VERSION ""

NS_ :

BS_:

BU_:

BO_ 2566697982 FPOC: 64 Vector__XXX
 SG_ FusedOutput10Current : 144|16@1+ (0.005,0) [0|321.275] "A" Vector__XXX
 SG_ FusedOutput11Current : 160|16@1+ (0.005,0) [0|321.275] "A" Vector__XXX
 SG_ FusedOutput12Current : 176|16@1+ (0.005,0) [0|321.275] "A" Vector__XXX
 SG_ FusedOutput13Current : 192|16@1+ (0.005,0) [0|321.275] "A" Vector__XXX
 SG_ FusedOutput14Current : 208|16@1+ (0.005,0) [0|321.275] "A" Vector__XXX
 SG_ FusedOutput15Current : 224|16@1+ (0.005,0) [0|321.275] "A" Vector__XXX
 SG_ FusedOutput16Current : 240|16@1+ (0.005,0) [0|321.275] "A" Vector__XXX
 SG_ FusedOutput17Current : 256|16@1+ (0.005,0) [0|321.275] "A" Vector__XXX
 SG_ FusedOutput18Current : 272|16@1+ (0.005,0) [0|321.275] "A" Vector__XXX
 SG_ FusedOutput19Current : 288|16@1+ (0.005,0) [0|321.275] "A" Vector__XXX
 SG_ FusedOutput1Current : 0|16@1+ (0.005,0) [0|321.275] "A" Vector__XXX
 SG_ FusedOutput20Current : 304|16@1+ (0.005,0) [0|321.275] "A" Vector__XXX
 SG_ FusedOutput21Current : 320|16@1+ (0.005,0) [0|321.275] "A" Vector__XXX
 SG_ FusedOutput22Current : 336|16@1+ (0.005,0) [0|321.275] "A" Vector__XXX
 SG_ FusedOutput23Current : 352|16@1+ (0.005,0) [0|321.275] "A" Vector__XXX
 SG_ FusedOutput24Current : 368|16@1+ (0.005,0) [0|321.275] "A" Vector__XXX
 SG_ FusedOutput25Current : 384|16@1+ (0.005,0) [0|321.275] "A" Vector__XXX
 SG_ FusedOutput26Current : 400|16@1+ (0.005,0) [0|321.275] "A" Vector__XXX
 SG_ FusedOutput27Current : 416|16@1+ (0.005,0) [0|321.275] "A" Vector__XXX
 SG_ FusedOutput28Current : 432|16@1+ (0.005,0) [0|321.275] "A" Vector__XXX
 SG_ FusedOutput29Current : 448|16@1+ (0.005,0) [0|321.275] "A" Vector__XXX
 SG_ FusedOutput2Current : 16|16@1+ (0.005,0) [0|321.275] "A" Vector__XXX
 SG_ FusedOutput30Current : 464|16@1+ (0.005,0) [0|321.275] "A" Vector__XXX
 SG_ FusedOutput31Current : 480|16@1+ (0.005,0) [0|321.275] "A" Vector__XXX
 SG_ FusedOutput32Current : 496|16@1+ (0.005,0) [0|321.275] "A" Vector__XXX
 SG_ FusedOutput3Current : 32|16@1+ (0.005,0) [0|321.275] "A" Vector__XXX
 SG_ FusedOutput4Current : 48|16@1+ (0.005,0) [0|321.275] "A" Vector__XXX
 SG_ FusedOutput5Current : 64|16@1+ (0.005,0) [0|321.275] "A" Vector__XXX
 SG_ FusedOutput6Current : 80|16@1+ (0.005,0) [0|321.275] "A" Vector__XXX
 SG_ FusedOutput7Current : 96|16@1+ (0.005,0) [0|321.275] "A" Vector__XXX
 SG_ FusedOutput8Current : 112|16@1+ (0.005,0) [0|321.275] "A" Vector__XXX
 SG_ FusedOutput9Current : 128|16@1+ (0.005,0) [0|321.275] "A" Vector__XXX

BO_ 2566698238 SPOS: 8 Vector__XXX
 SG_ SwitchedOutput1 : 6|2@1+ (1,0) [0|3] "" Vector__XXX
 SG_ SwitchedOutput10 : 20|2@1+ (1,0) [0|3] "" Vector__XXX
 SG_ SwitchedOutput11 : 18|2@1+ (1,0) [0|3] "" Vector__XXX
 SG_ SwitchedOutput12 : 16|2@1+ (1,0) [0|3] "" Vector__XXX
 SG_ SwitchedOutput13 : 30|2@1+ (1,0) [0|3] "" Vector__XXX
 SG_ SwitchedOutput14 : 28|2@1+ (1,0) [0|3] "" Vector__XXX
 SG_ SwitchedOutput15 : 26|2@1+ (1,0) [0|3] "" Vector__XXX
 SG_ SwitchedOutput16 : 24|2@1+ (1,0) [0|3] "" Vector__XXX
 SG_ SwitchedOutput17 : 38|2@1+ (1,0) [0|3] "" Vector__XXX
 SG_ SwitchedOutput18 : 36|2@1+ (1,0) [0|3] "" Vector__XXX
 SG_ SwitchedOutput19 : 34|2@1+ (1,0) [0|3] "" Vector__XXX
 SG_ SwitchedOutput2 : 4|2@1+ (1,0) [0|3] "" Vector__XXX
 SG_ SwitchedOutput20 : 32|2@1+ (1,0) [0|3] "" Vector__XXX
 SG_ SwitchedOutput21 : 46|2@1+ (1,0) [0|3] "" Vector__XXX
 SG_ SwitchedOutput22 : 44|2@1+ (1,0) [0|3] "" Vector__XXX
 SG_ SwitchedOutput23 : 42|2@1+ (1,0) [0|3] "" Vector__XXX
 SG_ SwitchedOutput24 : 40|2@1+ (1,0) [0|3] "" Vector__XXX
 SG_ SwitchedOutput25 : 54|2@1+ (1,0) [0|3] "" Vector__XXX
 SG_ SwitchedOutput26 : 52|2@1+ (1,0) [0|3] "" Vector__XXX
 SG_ SwitchedOutput27 : 50|2@1+ (1,0) [0|3] "" Vector__XXX
 SG_ SwitchedOutput28 : 48|2@1+ (1,0) [0|3] "" Vector__XXX
 SG_ SwitchedOutput29 : 62|2@1+ (1,0) [0|3] "" Vector__XXX
 SG_ SwitchedOutput3 : 2|2@1+ (1,0) [0|3] "" Vector__XXX
 SG_ SwitchedOutput30 : 60|2@1+ (1,0) [0|3] "" Vector__XXX
 SG_ SwitchedOutput31 : 58|2@1+ (1,0) [0|3] "" Vector__XXX
 SG_ SwitchedOutput32 : 56|2@1+ (1,0) [0|3] "" Vector__XXX
 SG_ SwitchedOutput4 : 0|2@1+ (1,0) [0|3] "" Vector__XXX
 SG_ SwitchedOutput5 : 14|2@1+ (1,0) [0|3] "" Vector__XXX
 SG_ SwitchedOutput6 : 12|2@1+ (1,0) [0|3] "" Vector__XXX
 SG_ SwitchedOutput7 : 10|2@1+ (1,0) [0|3] "" Vector__XXX
 SG_ SwitchedOutput8 : 8|2@1+ (1,0) [0|3] "" Vector__XXX
 SG_ SwitchedOutput9 : 22|2@1+ (1,0) [0|3] "" Vector__XXX

BO_ 2566698494 FPOS: 8 Vector__XXX
 SG_ FusedOutput1 : 6|2@1+ (1,0) [0|3] "" Vector__XXX
 SG_ FusedOutput10 : 20|2@1+ (1,0) [0|3] "" Vector__XXX
 SG_ FusedOutput11 : 18|2@1+ (1,0) [0|3] "" Vector__XXX
 SG_ FusedOutput12 : 16|2@1+ (1,0) [0|3] "" Vector__XXX
 SG_ FusedOutput13 : 30|2@1+ (1,0) [0|3] "" Vector__XXX
 SG_ FusedOutput14 : 28|2@1+ (1,0) [0|3] "" Vector__XXX
 SG_ FusedOutput15 : 26|2@1+ (1,0) [0|3] "" Vector__XXX
 SG_ FusedOutput16 : 24|2@1+ (1,0) [0|3] "" Vector__XXX
 SG_ FusedOutput17 : 38|2@1+ (1,0) [0|3] "" Vector__XXX
 SG_ FusedOutput18 : 36|2@1+ (1,0) [0|3] "" Vector__XXX
 SG_ FusedOutput19 : 34|2@1+ (1,0) [0|3] "" Vector__XXX
 SG_ FusedOutput2 : 4|2@1+ (1,0) [0|3] "" Vector__XXX
 SG_ FusedOutput20 : 32|2@1+ (1,0) [0|3] "" Vector__XXX
 SG_ FusedOutput21 : 46|2@1+ (1,0) [0|3] "" Vector__XXX
 SG_ FusedOutput22 : 44|2@1+ (1,0) [0|3] "" Vector__XXX
 SG_ FusedOutput23 : 42|2@1+ (1,0) [0|3] "" Vector__XXX
 SG_ FusedOutput24 : 40|2@1+ (1,0) [0|3] "" Vector__XXX
 SG_ FusedOutput25 : 54|2@1+ (1,0) [0|3] "" Vector__XXX
 SG_ FusedOutput26 : 52|2@1+ (1,0) [0|3] "" Vector__XXX
 SG_ FusedOutput27 : 50|2@1+ (1,0) [0|3] "" Vector__XXX
 SG_ FusedOutput28 : 48|2@1+ (1,0) [0|3] "" Vector__XXX
 SG_ FusedOutput29 : 62|2@1+ (1,0) [0|3] "" Vector__XXX
 SG_ FusedOutput3 : 2|2@1+ (1,0) [0|3] "" Vector__XXX
 SG_ FusedOutput30 : 60|2@1+ (1,0) [0|3] "" Vector__XXX
 SG_ FusedOutput31 : 58|2@1+ (1,0) [0|3] "" Vector__XXX
 SG_ FusedOutput32 : 56|2@1+ (1,0) [0|3] "" Vector__XXX
 SG_ FusedOutput4 : 0|2@1+ (1,0) [0|3] "" Vector__XXX
 SG_ FusedOutput5 : 14|2@1+ (1,0) [0|3] "" Vector__XXX
 SG_ FusedOutput6 : 12|2@1+ (1,0) [0|3] "" Vector__XXX
 SG_ FusedOutput7 : 10|2@1+ (1,0) [0|3] "" Vector__XXX
 SG_ FusedOutput8 : 8|2@1+ (1,0) [0|3] "" Vector__XXX
 SG_ FusedOutput9 : 22|2@1+ (1,0) [0|3] "" Vector__XXX

BO_ 2566698750 VEP5: 8 Vector__XXX
 SG_ SLIBatteryPackCapacity : 16|16@1+ (1,0) [0|64255] "Ah" Vector__XXX
 SG_ SLIBatteryPackHealth : 32|8@1+ (0.5,0) [0|125] "%" Vector__XXX
 SG_ SLIBatteryPackStateofCharge : 0|16@1+ (0.0025,0) [0|160.6375] "%" Vector__XXX
 SG_ SLICrnkngPrdtdMnmmBttrVltg : 40|8@1+ (0.2,0) [0|50] "V" Vector__XXX

BO_ 2566699006 HSS2: 8 Vector__XXX
 SG_ HrdBttrPkRmnngChrg : 0|16@1+ (0.0025,0) [0|160.6375] "%" Vector__XXX
 SG_ HrdSstmEngnStpStrtRmnngPrntg : 16|8@1+ (0.4,0) [0|100] "%" Vector__XXX
 SG_ HrdPrplsnMdMxmmSpdSttng : 24|8@1+ (1,0) [0|250] "km/h" Vector__XXX
 SG_ HrdPrplsnMdRmnngDstn : 32|16@1+ (0.03125,0) [0|2007.96875] "km" Vector__XXX

BO_ 2566699262 AT2S2: 8 Vector__XXX
 SG_ Atttt2DsPttFtTtNxtAtvRt : 0|32@1+ (1,0) [0|4.21108E+09] "s" Vector__XXX
 SG_ Atttt2SCRSstTSLstSstCEvt : 32|32@1+ (1,0) [0|4.21108E+09] "s" Vector__XXX

BO_ 2566699518 AT1S2: 8 Vector__XXX
 SG_ Atttt1DsPttFtTtNxtAtvRt : 0|32@1+ (1,0) [0|4.21108E+09] "s" Vector__XXX
 SG_ Atttt1SCRSstTSLstSstCEvt : 32|32@1+ (1,0) [0|4.21108E+09] "s" Vector__XXX

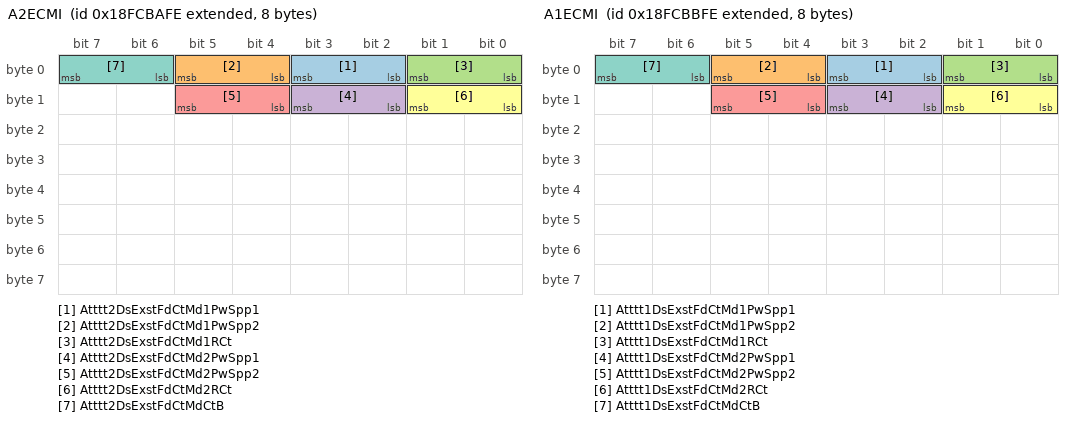
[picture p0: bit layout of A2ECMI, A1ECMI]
BO_ 2566699774 A2ECMI: 8 Vector__XXX
 SG_ Atttt2DsExstFdCtMd1PwSpp1 : 2|2@1+ (1,0) [0|3] "" Vector__XXX
 SG_ Atttt2DsExstFdCtMd1PwSpp2 : 4|2@1+ (1,0) [0|3] "" Vector__XXX
 SG_ Atttt2DsExstFdCtMd1RCt : 0|2@1+ (1,0) [0|3] "" Vector__XXX
 SG_ Atttt2DsExstFdCtMd2PwSpp1 : 10|2@1+ (1,0) [0|3] "" Vector__XXX
 SG_ Atttt2DsExstFdCtMd2PwSpp2 : 12|2@1+ (1,0) [0|3] "" Vector__XXX
 SG_ Atttt2DsExstFdCtMd2RCt : 8|2@1+ (1,0) [0|3] "" Vector__XXX
 SG_ Atttt2DsExstFdCtMdCtB : 6|2@1+ (1,0) [0|3] "" Vector__XXX

BO_ 2566700030 A1ECMI: 8 Vector__XXX
 SG_ Atttt1DsExstFdCtMd1PwSpp1 : 2|2@1+ (1,0) [0|3] "" Vector__XXX
 SG_ Atttt1DsExstFdCtMd1PwSpp2 : 4|2@1+ (1,0) [0|3] "" Vector__XXX
 SG_ Atttt1DsExstFdCtMd1RCt : 0|2@1+ (1,0) [0|3] "" Vector__XXX
 SG_ Atttt1DsExstFdCtMd2PwSpp1 : 10|2@1+ (1,0) [0|3] "" Vector__XXX
 SG_ Atttt1DsExstFdCtMd2PwSpp2 : 12|2@1+ (1,0) [0|3] "" Vector__XXX
 SG_ Atttt1DsExstFdCtMd2RCt : 8|2@1+ (1,0) [0|3] "" Vector__XXX
 SG_ Atttt1DsExstFdCtMdCtB : 6|2@1+ (1,0) [0|3] "" Vector__XXX

BO_ 2566700286 A2SCRSI2: 8 Vector__XXX
 SG_ Aftrtrtmnt2TtlDslExhstFldUsd : 0|32@1+ (0.5,0) [0|2105540607.5] "l" Vector__XXX

BO_ 2566700542 A1SCRSI2: 8 Vector__XXX
 SG_ Aftrtrtmnt1TtlDslExhstFldUsd : 0|32@1+ (0.5,0) [0|2105540607.5] "l" Vector__XXX
 SG_ AftrtrtmntTrpDslExhstFld : 32|32@1+ (0.05,0) [0|210554060.75] "l" Vector__XXX

BO_ 2566701566 TRF3: 8 Vector__XXX
 SG_ TransmissionClutch2Pressure : 0|8@1+ (16,0) [0|4000] "kPa" Vector__XXX
 SG_ TrnsmssnOlTrnsmssnClrOtltTmprtr : 8|8@1+ (1,-40) [-40|210] "degC" Vector__XXX

BO_ 2566701822 HSS1: 8 Vector__XXX
 SG_ ExtrnlEnrgSrCnntnStts : 48|4@1+ (1,0) [0|15] "" Vector__XXX
 SG_ HrdPrplsnMdTrnstnStts : 44|4@1+ (1,0) [0|15] "" Vector__XXX
 SG_ HrdSstmEltrAltrntrIndtr : 18|2@1+ (1,0) [0|3] "" Vector__XXX
 SG_ HrdSstmHghVltgExpsrIndtr : 24|2@1+ (1,0) [0|3] "" Vector__XXX
 SG_ HrdSstmIntlztnIndtr : 22|2@1+ (1,0) [0|3] "" Vector__XXX
 SG_ HrdSstmMtrOvrspdAdlAlrm : 16|2@1+ (1,0) [0|3] "" Vector__XXX
 SG_ HrdSstmMtrOvrspdIndtr : 14|2@1+ (1,0) [0|3] "" Vector__XXX
 SG_ HrdSstmPrplsnDslStts : 52|2@1+ (1,0) [0|3] "" Vector__XXX
 SG_ HrdSstmRgnrtvBrkngIndtr : 20|2@1+ (1,0) [0|3] "" Vector__XXX
 SG_ HybridPropulsionModeStatus : 40|4@1+ (1,0) [0|15] "" Vector__XXX
 SG_ HybridSystemEngineAssistStatus : 10|2@1+ (1,0) [0|3] "" Vector__XXX
 SG_ HybridSystemOBDRelatedDTCStatus : 6|2@1+ (1,0) [0|3] "" Vector__XXX
 SG_ HybridSystemOverheatIndicator : 2|2@1+ (1,0) [0|3] "" Vector__XXX
 SG_ HybridSystemServiceIndicator : 12|2@1+ (1,0) [0|3] "" Vector__XXX
 SG_ HybridSystemStopIndicator : 4|2@1+ (1,0) [0|3] "" Vector__XXX
 SG_ HybridSystemWarningIndicator : 0|2@1+ (1,0) [0|3] "" Vector__XXX
 SG_ PropulsionSystemActive : 8|2@1+ (1,0) [0|3] "" Vector__XXX
 SG_ StoredEnergySourceLevel : 32|8@1+ (0.4,0) [0|100] "%" Vector__XXX
 SG_ StrdEnrgSrInrsngMdAllwd : 28|2@1+ (1,0) [0|3] "" Vector__XXX
 SG_ StrdEnrgSrOnlMdAllwd : 26|2@1+ (1,0) [0|3] "" Vector__XXX

BO_ 2566702078 GFI4: 8 Vector__XXX
 SG_ SupplyGasMethanePercentage : 0|16@1+ (0.0025,0) [0|160.6375] "%" Vector__XXX

BO_ 2566702334 A2SCREGT2: 8 Vector__XXX
 SG_ Aftrtrtmnt2SCRIntrmdtTmprtr : 0|16@1+ (0.03125,-273) [-273|1734.96875] "degC" Vector__XXX
 SG_ Atttt2SCRItdtTptPFMI : 16|5@1+ (1,0) [0|31] "binary" Vector__XXX

BO_ 2566702590 A1SCREGT2: 8 Vector__XXX
 SG_ Aftrtrtmnt1SCRIntrmdtTmprtr : 0|16@1+ (0.03125,-273) [-273|1734.96875] "degC" Vector__XXX
 SG_ Atttt1SCRItdtTptPFMI : 16|5@1+ (1,0) [0|31] "binary" Vector__XXX

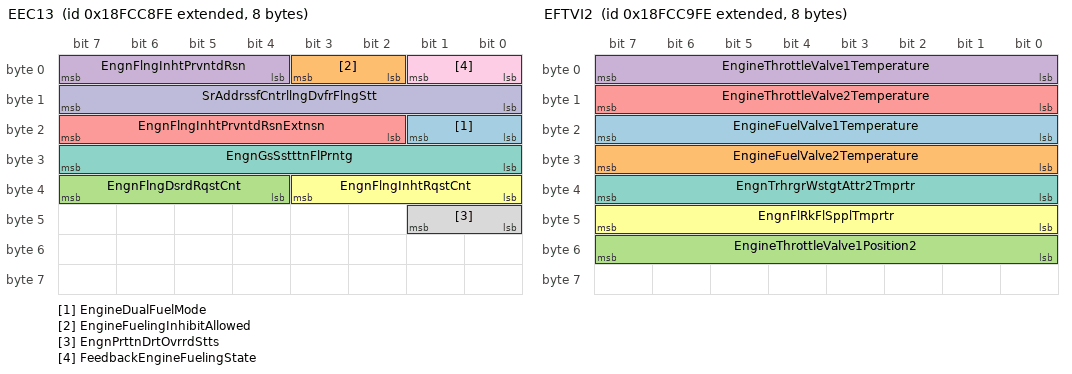
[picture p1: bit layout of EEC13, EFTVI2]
BO_ 2566703358 EEC13: 8 Vector__XXX
 SG_ EngineDualFuelMode : 16|2@1+ (1,0) [0|3] "" Vector__XXX
 SG_ EngineFuelingInhibitAllowed : 2|2@1+ (1,0) [0|3] "" Vector__XXX
 SG_ EngnFlngDsrdRqstCnt : 36|4@1+ (1,0) [0|15] "" Vector__XXX
 SG_ EngnFlngInhtPrvntdRsn : 4|4@1+ (1,0) [0|15] "" Vector__XXX
 SG_ EngnFlngInhtPrvntdRsnExtnsn : 18|6@1+ (1,0) [0|63] "" Vector__XXX
 SG_ EngnFlngInhtRqstCnt : 32|4@1+ (1,0) [0|15] "" Vector__XXX
 SG_ EngnGsSstttnFlPrntg : 24|8@1+ (0.5,0) [0|125] "%" Vector__XXX
 SG_ EngnPrttnDrtOvrrdStts : 40|2@1+ (1,0) [0|3] "" Vector__XXX
 SG_ FeedbackEngineFuelingState : 0|2@1+ (1,0) [0|3] "" Vector__XXX
 SG_ SrAddrssfCntrllngDvfrFlngStt : 8|8@1+ (1,0) [0|255] "SA" Vector__XXX

BO_ 2566703614 EFTVI2: 8 Vector__XXX
 SG_ EngineFuelValve1Temperature : 16|8@1+ (1,-40) [-40|210] "degC" Vector__XXX
 SG_ EngineFuelValve2Temperature : 24|8@1+ (1,-40) [-40|210] "degC" Vector__XXX
 SG_ EngineThrottleValve1Position2 : 48|8@1+ (0.4,0) [0|100] "%" Vector__XXX
 SG_ EngineThrottleValve1Temperature : 0|8@1+ (1,-40) [-40|210] "degC" Vector__XXX
 SG_ EngineThrottleValve2Temperature : 8|8@1+ (1,-40) [-40|210] "degC" Vector__XXX
 SG_ EngnFlRkFlSpplTmprtr : 40|8@1+ (1,-40) [-40|210] "degC" Vector__XXX
 SG_ EngnTrhrgrWstgtAttr2Tmprtr : 32|8@1+ (1,-40) [-40|210] "degC" Vector__XXX

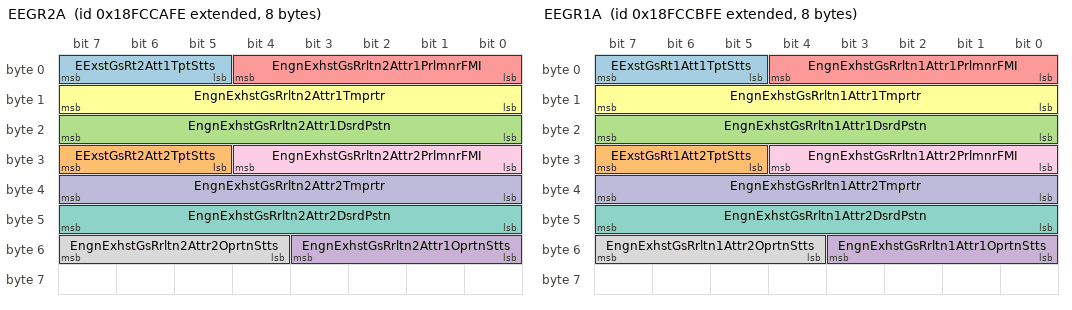
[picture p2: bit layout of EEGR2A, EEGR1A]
BO_ 2566703870 EEGR2A: 8 Vector__XXX
 SG_ EExstGsRt2Att1TptStts : 5|3@1+ (1,0) [0|7] "" Vector__XXX
 SG_ EExstGsRt2Att2TptStts : 29|3@1+ (1,0) [0|7] "" Vector__XXX
 SG_ EngnExhstGsRrltn2Attr1DsrdPstn : 16|8@1+ (0.4,0) [0|100] "%" Vector__XXX
 SG_ EngnExhstGsRrltn2Attr1OprtnStts : 48|4@1+ (1,0) [0|15] "" Vector__XXX
 SG_ EngnExhstGsRrltn2Attr1PrlmnrFMI : 0|5@1+ (1,0) [0|31] "binary" Vector__XXX
 SG_ EngnExhstGsRrltn2Attr1Tmprtr : 8|8@1+ (1,-40) [-40|210] "degC" Vector__XXX
 SG_ EngnExhstGsRrltn2Attr2DsrdPstn : 40|8@1+ (0.4,0) [0|100] "%" Vector__XXX
 SG_ EngnExhstGsRrltn2Attr2OprtnStts : 52|4@1+ (1,0) [0|15] "" Vector__XXX
 SG_ EngnExhstGsRrltn2Attr2PrlmnrFMI : 24|5@1+ (1,0) [0|31] "binary" Vector__XXX
 SG_ EngnExhstGsRrltn2Attr2Tmprtr : 32|8@1+ (1,-40) [-40|210] "degC" Vector__XXX

BO_ 2566704126 EEGR1A: 8 Vector__XXX
 SG_ EExstGsRt1Att1TptStts : 5|3@1+ (1,0) [0|7] "" Vector__XXX
 SG_ EExstGsRt1Att2TptStts : 29|3@1+ (1,0) [0|7] "" Vector__XXX
 SG_ EngnExhstGsRrltn1Attr1DsrdPstn : 16|8@1+ (0.4,0) [0|100] "%" Vector__XXX
 SG_ EngnExhstGsRrltn1Attr1OprtnStts : 48|4@1+ (1,0) [0|15] "" Vector__XXX
 SG_ EngnExhstGsRrltn1Attr1PrlmnrFMI : 0|5@1+ (1,0) [0|31] "binary" Vector__XXX
 SG_ EngnExhstGsRrltn1Attr1Tmprtr : 8|8@1+ (1,-40) [-40|210] "degC" Vector__XXX
 SG_ EngnExhstGsRrltn1Attr2DsrdPstn : 40|8@1+ (0.4,0) [0|100] "%" Vector__XXX
 SG_ EngnExhstGsRrltn1Attr2OprtnStts : 52|4@1+ (1,0) [0|15] "" Vector__XXX
 SG_ EngnExhstGsRrltn1Attr2PrlmnrFMI : 24|5@1+ (1,0) [0|31] "binary" Vector__XXX
 SG_ EngnExhstGsRrltn1Attr2Tmprtr : 32|8@1+ (1,-40) [-40|210] "degC" Vector__XXX

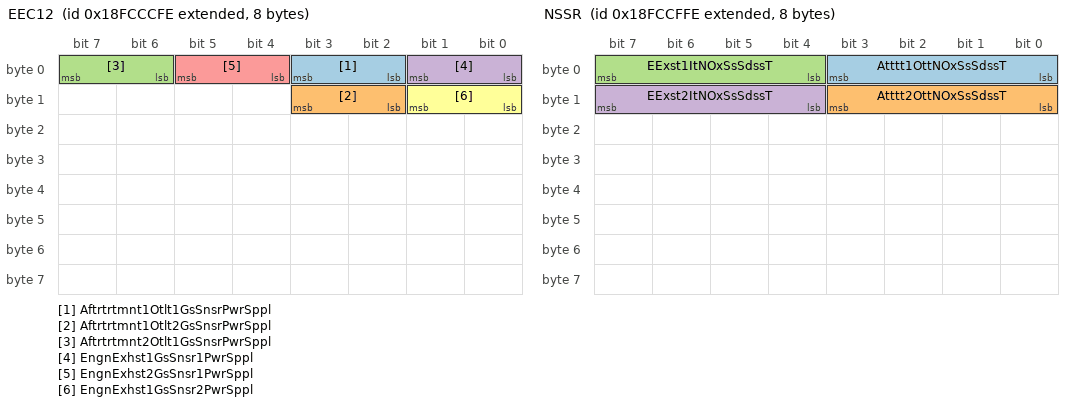
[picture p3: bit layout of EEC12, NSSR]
BO_ 2566704382 EEC12: 8 Vector__XXX
 SG_ Aftrtrtmnt1Otlt1GsSnsrPwrSppl : 2|2@1+ (1,0) [0|3] "" Vector__XXX
 SG_ Aftrtrtmnt1Otlt2GsSnsrPwrSppl : 10|2@1+ (1,0) [0|3] "" Vector__XXX
 SG_ Aftrtrtmnt2Otlt1GsSnsrPwrSppl : 6|2@1+ (1,0) [0|3] "" Vector__XXX
 SG_ EngnExhst1GsSnsr1PwrSppl : 0|2@1+ (1,0) [0|3] "" Vector__XXX
 SG_ EngnExhst2GsSnsr1PwrSppl : 4|2@1+ (1,0) [0|3] "" Vector__XXX
 SG_ EngnExhst1GsSnsr2PwrSppl : 8|2@1+ (1,0) [0|3] "" Vector__XXX

BO_ 2566705150 NSSR: 8 Vector__XXX
 SG_ Atttt1OttNOxSsSdssT : 0|4@1+ (1,0) [0|15] "" Vector__XXX
 SG_ Atttt2OttNOxSsSdssT : 8|4@1+ (1,0) [0|15] "" Vector__XXX
 SG_ EExst1ItNOxSsSdssT : 4|4@1+ (1,0) [0|15] "" Vector__XXX
 SG_ EExst2ItNOxSsSdssT : 12|4@1+ (1,0) [0|15] "" Vector__XXX

BO_ 2566705406 EPSI: 8 Vector__XXX
 SG_ Aftrtrtmnt1PrtltSnsr : 0|16@1+ (0.0125,0) [0|803.1875] "mg/(m*m*m)" Vector__XXX
 SG_ Aftrtrtmnt1PrtltSnsrCrrnt : 32|16@1+ (0.00390625,0) [0|250.99609375] "micro A" Vector__XXX
 SG_ Aftrtrtmnt2PrtltSnsr : 16|16@1+ (0.0125,0) [0|803.1875] "mg/(m*m*m)" Vector__XXX

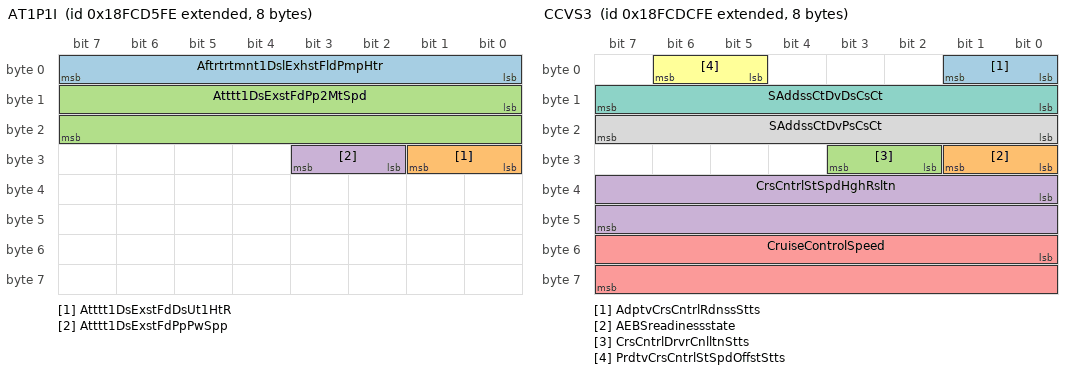
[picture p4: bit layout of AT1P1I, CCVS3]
BO_ 2566706686 AT1P1I: 8 Vector__XXX
 SG_ Aftrtrtmnt1DslExhstFldPmpHtr : 0|8@1+ (0.4,0) [0|100] "%" Vector__XXX
 SG_ Atttt1DsExstFdDsUt1HtR : 24|2@1+ (1,0) [0|3] "" Vector__XXX
 SG_ Atttt1DsExstFdPp2MtSpd : 8|16@1+ (0.5,0) [0|32127.5] "rpm" Vector__XXX
 SG_ Atttt1DsExstFdPpPwSpp : 26|2@1+ (1,0) [0|3] "" Vector__XXX

BO_ 2566706942 AT1DPF2S5: 8 Vector__XXX
 SG_ Atttt1DsPttFt2StSsAssFq3 : 0|16@1+ (0.1,0) [0|6425.5] "MHz" Vector__XXX
 SG_ Atttt1DsPttFt2StSsAssFq4 : 32|16@1+ (0.1,0) [0|6425.5] "MHz" Vector__XXX
 SG_ Atttt1DsPttFt2StSsFq3StS : 16|16@1+ (0.0025,0) [0|160.6375] "%" Vector__XXX
 SG_ Atttt1DsPttFt2StSsFq4StS : 48|16@1+ (0.0025,0) [0|160.6375] "%" Vector__XXX

BO_ 2566707198 AT1DPF2S4: 8 Vector__XXX
 SG_ Atttt1DsPttFt2StSsAssFq1 : 0|16@1+ (0.1,0) [0|6425.5] "MHz" Vector__XXX
 SG_ Atttt1DsPttFt2StSsAssFq2 : 32|16@1+ (0.1,0) [0|6425.5] "MHz" Vector__XXX
 SG_ Atttt1DsPttFt2StSsFq1StS : 16|16@1+ (0.0025,0) [0|160.6375] "%" Vector__XXX
 SG_ Atttt1DsPttFt2StSsFq2StS : 48|16@1+ (0.0025,0) [0|160.6375] "%" Vector__XXX

BO_ 2566707454 AT1DPF2S3: 8 Vector__XXX
 SG_ Atttt1DsPttFt2StSsAssRqstFq1 : 0|16@1+ (0.1,0) [0|6425.5] "MHz" Vector__XXX
 SG_ Atttt1DsPttFt2StSsAssRqstFq2 : 16|16@1+ (0.1,0) [0|6425.5] "MHz" Vector__XXX
 SG_ Atttt1DsPttFt2StSsAssRqstFq3 : 32|16@1+ (0.1,0) [0|6425.5] "MHz" Vector__XXX
 SG_ Atttt1DsPttFt2StSsAssRqstFq4 : 48|16@1+ (0.1,0) [0|6425.5] "MHz" Vector__XXX

BO_ 2566707710 AT1DPF1S5: 8 Vector__XXX
 SG_ Atttt1DsPttFt1StSsAssFq3 : 0|16@1+ (0.1,0) [0|6425.5] "MHz" Vector__XXX
 SG_ Atttt1DsPttFt1StSsAssFq4 : 32|16@1+ (0.1,0) [0|6425.5] "MHz" Vector__XXX
 SG_ Atttt1DsPttFt1StSsFq3StS : 16|16@1+ (0.0025,0) [0|160.6375] "%" Vector__XXX
 SG_ Atttt1DsPttFt1StSsFq4StS : 48|16@1+ (0.0025,0) [0|160.6375] "%" Vector__XXX

BO_ 2566707966 AT1DPF1S4: 8 Vector__XXX
 SG_ Atttt1DsPttFt1StSsAssFq1 : 0|16@1+ (0.1,0) [0|6425.5] "MHz" Vector__XXX
 SG_ Atttt1DsPttFt1StSsAssFq2 : 32|16@1+ (0.1,0) [0|6425.5] "MHz" Vector__XXX
 SG_ Atttt1DsPttFt1StSsFq1StS : 16|16@1+ (0.0025,0) [0|160.6375] "%" Vector__XXX
 SG_ Atttt1DsPttFt1StSsFq2StS : 48|16@1+ (0.0025,0) [0|160.6375] "%" Vector__XXX

BO_ 2566708222 AT1DPF1S3: 8 Vector__XXX
 SG_ Atttt1DsPttFt1StSsAssRqstFq1 : 0|16@1+ (0.1,0) [0|6425.5] "MHz" Vector__XXX
 SG_ Atttt1DsPttFt1StSsAssRqstFq2 : 16|16@1+ (0.1,0) [0|6425.5] "MHz" Vector__XXX
 SG_ Atttt1DsPttFt1StSsAssRqstFq3 : 32|16@1+ (0.1,0) [0|6425.5] "MHz" Vector__XXX
 SG_ Atttt1DsPttFt1StSsAssRqstFq4 : 48|16@1+ (0.1,0) [0|6425.5] "MHz" Vector__XXX

BO_ 2566708478 CCVS3: 8 Vector__XXX
 SG_ AdptvCrsCntrlRdnssStts : 0|2@1+ (1,0) [0|3] "" Vector__XXX
 SG_ AEBSreadinessstate : 24|2@1+ (1,0) [0|3] "" Vector__XXX
 SG_ CrsCntrlDrvrCnlltnStts : 26|2@1+ (1,0) [0|3] "" Vector__XXX
 SG_ CrsCntrlStSpdHghRsltn : 32|16@1+ (0.00390625,0) [0|250.996] "km/h" Vector__XXX
 SG_ CruiseControlSpeed : 48|16@1+ (0.00390625,0) [0|250.996] "km/h" Vector__XXX
 SG_ PrdtvCrsCntrlStSpdOffstStts : 5|2@1+ (1,0) [0|3] "" Vector__XXX
 SG_ SAddssCtDvDsCsCt : 8|8@1+ (1,0) [0|255] "SA" Vector__XXX
 SG_ SAddssCtDvPsCsCt : 16|8@1+ (1,0) [0|255] "SA" Vector__XXX

BO_ 2566708734 AT2AC3: 8 Vector__XXX
 SG_ Aftrtrtmnt2SndrArAsltPrssr : 0|16@1+ (0.1,0) [0|6425.5] "kPa" Vector__XXX

BO_ 2566708990 AT1AC3: 8 Vector__XXX
 SG_ Aftrtrtmnt1SndrArAsltPrssr : 0|16@1+ (0.1,0) [0|6425.5] "kPa" Vector__XXX
 SG_ OprtrIndmntOvrrdRnwlRqrd : 16|2@1+ (1,0) [0|3] "" Vector__XXX

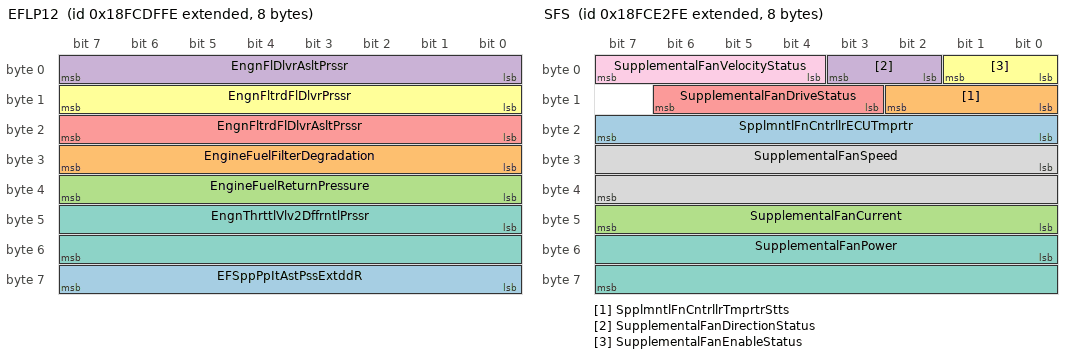
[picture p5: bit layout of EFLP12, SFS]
BO_ 2566709246 EFLP12: 8 Vector__XXX
 SG_ EFSppPpItAstPssExtddR : 56|8@1+ (5,0) [0|1250] "kPa" Vector__XXX
 SG_ EngineFuelFilterDegradation : 24|8@1+ (1,0) [0|250] "%" Vector__XXX
 SG_ EngineFuelReturnPressure : 32|8@1+ (1.64,-7) [-7|403] "kPa" Vector__XXX
 SG_ EngnFlDlvrAsltPrssr : 0|8@1+ (4,0) [0|1000] "kPa" Vector__XXX
 SG_ EngnFltrdFlDlvrAsltPrssr : 16|8@1+ (4,0) [0|1000] "kPa" Vector__XXX
 SG_ EngnFltrdFlDlvrPrssr : 8|8@1+ (4,0) [0|1000] "kPa" Vector__XXX
 SG_ EngnThrttlVlv2DffrntlPrssr : 40|16@1+ (0.1,0) [0|6425.5] "kPa" Vector__XXX

BO_ 2566709502 DPFC2: 8 Vector__XXX
 SG_ Aftertreatment1FuelMassRate : 32|16@1+ (0.05,0) [0|3212.75] "g/min" Vector__XXX
 SG_ Aftertreatment2FuelMassRate : 48|16@1+ (0.05,0) [0|3212.75] "g/min" Vector__XXX
 SG_ Atttt1DsPttFtItTptStPt : 0|16@1+ (0.03125,-273) [-273|1734.96875] "degC" Vector__XXX
 SG_ EngineUnburnedFuelPercentage : 16|16@1+ (0.0025,0) [0|160.6375] "%" Vector__XXX

BO_ 2566709758 LFE2: 8 Vector__XXX
 SG_ EngineDieselFuelDemandRate : 32|16@1+ (0.05,0) [0|3212.75] "l/h" Vector__XXX
 SG_ EngineFuelRateHighResolution : 0|32@1+ (0.001,0) [0|4211081.215] "l/h" Vector__XXX

BO_ 2566710014 SFS: 8 Vector__XXX
 SG_ SpplmntlFnCntrllrECUTmprtr : 16|8@1+ (1,-40) [-40|210] "degC" Vector__XXX
 SG_ SpplmntlFnCntrllrTmprtrStts : 8|3@1+ (1,0) [0|7] "" Vector__XXX
 SG_ SupplementalFanCurrent : 40|8@1+ (1,-125) [-125|125] "A" Vector__XXX
 SG_ SupplementalFanDirectionStatus : 2|2@1+ (1,0) [0|3] "" Vector__XXX
 SG_ SupplementalFanDriveStatus : 11|4@1+ (1,0) [0|15] "" Vector__XXX
 SG_ SupplementalFanEnableStatus : 0|2@1+ (1,0) [0|3] "" Vector__XXX
 SG_ SupplementalFanPower : 48|16@1+ (0.5,0) [0|32127.5] "W" Vector__XXX
 SG_ SupplementalFanSpeed : 24|16@1+ (0.5,0) [0|32127.5] "rpm" Vector__XXX
 SG_ SupplementalFanVelocityStatus : 4|4@1+ (1,0) [0|15] "" Vector__XXX

BO_ 2566710526 EFP: 8 Vector__XXX
 SG_ EngineFuelDensity : 16|16@1+ (0.00003052,0) [0|1.961] "g/cc" Vector__XXX
 SG_ EngineFuelDynamicViscosity : 0|16@1+ (0.015625,0) [0|1003.984375] "Cp" Vector__XXX
 SG_ EngnFl1Tmprtr1HghRsltn : 48|16@1+ (0.03125,-273) [-273|1734.96875] "degC" Vector__XXX
 SG_ EngnFlDltrtHghRsltn : 32|16@1+ (0.0001220703125,0) [0|7.844] "" Vector__XXX

BO_ 2566710782 HOP: 8 Vector__XXX
 SG_ HdrlOlRltvDltrtHghRsltn : 32|16@1+ (0.0001220703125,0) [0|7.844] "" Vector__XXX
 SG_ HdrlOlTmprtrHghRsltn : 48|16@1+ (0.03125,-273) [-273|1734.96875] "degC" Vector__XXX
 SG_ HydraulicOilDensity : 16|16@1+ (0.00003052,0) [0|1.961] "g/cc" Vector__XXX
 SG_ HydraulicOilDynamicViscosity : 0|16@1+ (0.015625,0) [0|1003.984375] "Cp" Vector__XXX

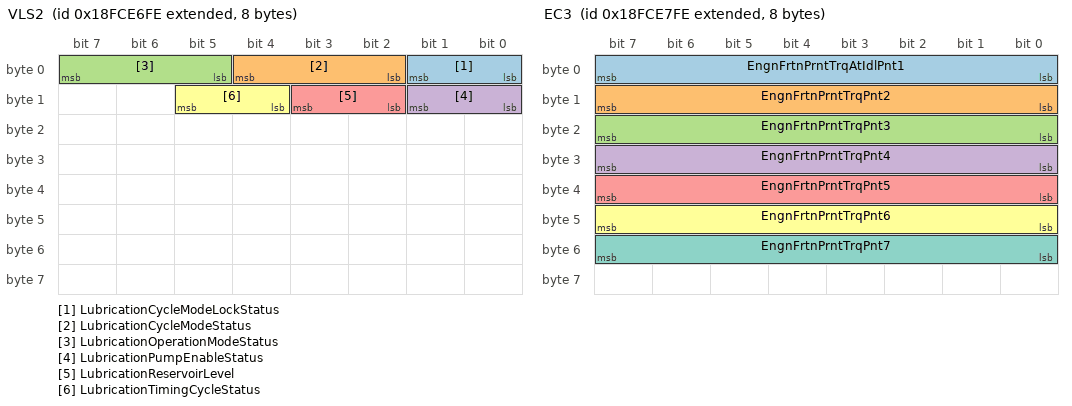
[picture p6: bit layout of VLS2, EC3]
BO_ 2566711038 VLS2: 8 Vector__XXX
 SG_ LubricationCycleModeLockStatus : 0|2@1+ (1,0) [0|3] "" Vector__XXX
 SG_ LubricationCycleModeStatus : 2|3@1+ (1,0) [0|7] "" Vector__XXX
 SG_ LubricationOperationModeStatus : 5|3@1+ (1,0) [0|7] "" Vector__XXX
 SG_ LubricationPumpEnableStatus : 8|2@1+ (1,0) [0|3] "" Vector__XXX
 SG_ LubricationReservoirLevel : 10|2@1+ (1,0) [0|3] "" Vector__XXX
 SG_ LubricationTimingCycleStatus : 12|2@1+ (1,0) [0|3] "" Vector__XXX

BO_ 2566711294 EC3: 8 Vector__XXX
 SG_ EngnFrtnPrntTrqAtIdlPnt1 : 0|8@1+ (1,-125) [-125|125] "%" Vector__XXX
 SG_ EngnFrtnPrntTrqPnt2 : 8|8@1+ (1,-125) [-125|125] "%" Vector__XXX
 SG_ EngnFrtnPrntTrqPnt3 : 16|8@1+ (1,-125) [-125|125] "%" Vector__XXX
 SG_ EngnFrtnPrntTrqPnt4 : 24|8@1+ (1,-125) [-125|125] "%" Vector__XXX
 SG_ EngnFrtnPrntTrqPnt5 : 32|8@1+ (1,-125) [-125|125] "%" Vector__XXX
 SG_ EngnFrtnPrntTrqPnt6 : 40|8@1+ (1,-125) [-125|125] "%" Vector__XXX
 SG_ EngnFrtnPrntTrqPnt7 : 48|8@1+ (1,-125) [-125|125] "%" Vector__XXX

BO_ 2566711550 IVAC: 8 Vector__XXX
 SG_ ItVvAttSstOPss1SdCt : 0|2@1+ (1,0) [0|3] "" Vector__XXX
 SG_ ItVvAttSstOPss2SdCt : 2|2@1+ (1,0) [0|3] "" Vector__XXX

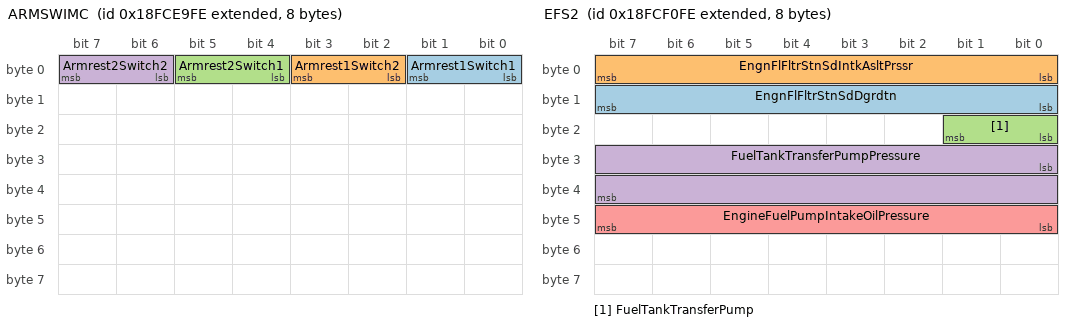
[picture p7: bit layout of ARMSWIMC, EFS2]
BO_ 2566711806 ARMSWIMC: 8 Vector__XXX
 SG_ Armrest1Switch1 : 0|2@1+ (1,0) [0|3] "" Vector__XXX
 SG_ Armrest1Switch2 : 2|2@1+ (1,0) [0|3] "" Vector__XXX
 SG_ Armrest2Switch1 : 4|2@1+ (1,0) [0|3] "" Vector__XXX
 SG_ Armrest2Switch2 : 6|2@1+ (1,0) [0|3] "" Vector__XXX

BO_ 2566712318 AFT2NAI: 8 Vector__XXX
 SG_ Aftrtrtmnt2NOxAdsrrDslftnStts : 2|2@1+ (1,0) [0|3] "" Vector__XXX
 SG_ Aftrtrtmnt2NOxAdsrrRgnrtnStts : 0|2@1+ (1,0) [0|3] "" Vector__XXX

BO_ 2566712574 AFT1NAI: 8 Vector__XXX
 SG_ Aftrtrtmnt1NOxAdsrrDslftnStts : 2|2@1+ (1,0) [0|3] "" Vector__XXX
 SG_ Aftrtrtmnt1NOxAdsrrRgnrtnStts : 0|2@1+ (1,0) [0|3] "" Vector__XXX

BO_ 2566712830 AT2WUDOC: 8 Vector__XXX
 SG_ Atttt2WUpDsOxdtCtstItTpt : 0|16@1+ (0.03125,-273) [-273|1734.96875] "degC" Vector__XXX
 SG_ Atttt2WUpDsOxdtCtstOttTpt : 16|16@1+ (0.03125,-273) [-273|1734.96875] "degC" Vector__XXX

BO_ 2566713598 EFS2: 8 Vector__XXX
 SG_ EngnFlFltrStnSdDgrdtn : 8|8@1+ (1,0) [0|250] "%" Vector__XXX
 SG_ EngnFlFltrStnSdIntkAsltPrssr : 0|8@1+ (2,0) [0|500] "kPa" Vector__XXX
 SG_ FuelTankTransferPump : 16|2@1+ (1,0) [0|3] "" Vector__XXX
 SG_ FuelTankTransferPumpPressure : 24|16@1+ (0.1,0) [0|6425.5] "kPa" Vector__XXX
 SG_ EngineFuelPumpIntakeOilPressure : 40|8@1+ (4,0) [0|1000] "kPa" Vector__XXX

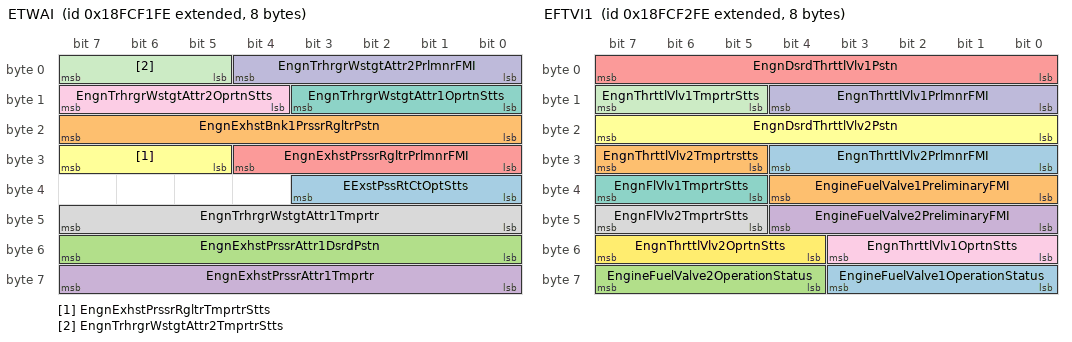
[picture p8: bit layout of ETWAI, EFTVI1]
BO_ 2566713854 ETWAI: 8 Vector__XXX
 SG_ EExstPssRtCtOptStts : 32|4@1+ (1,0) [0|15] "" Vector__XXX
 SG_ EngnExhstBnk1PrssrRgltrPstn : 16|8@1+ (0.4,0) [0|100] "%" Vector__XXX
 SG_ EngnExhstPrssrAttr1DsrdPstn : 48|8@1+ (0.4,0) [0|100] "%" Vector__XXX
 SG_ EngnExhstPrssrAttr1Tmprtr : 56|8@1+ (1,-40) [-40|210] "degC" Vector__XXX
 SG_ EngnExhstPrssrRgltrPrlmnrFMI : 24|5@1+ (1,0) [0|31] "binary" Vector__XXX
 SG_ EngnExhstPrssrRgltrTmprtrStts : 29|3@1+ (1,0) [0|7] "" Vector__XXX
 SG_ EngnTrhrgrWstgtAttr1OprtnStts : 8|4@1+ (1,0) [0|15] "" Vector__XXX
 SG_ EngnTrhrgrWstgtAttr1Tmprtr : 40|8@1+ (1,-40) [-40|210] "degC" Vector__XXX
 SG_ EngnTrhrgrWstgtAttr2OprtnStts : 12|4@1+ (1,0) [0|15] "" Vector__XXX
 SG_ EngnTrhrgrWstgtAttr2PrlmnrFMI : 0|5@1+ (1,0) [0|31] "binary" Vector__XXX
 SG_ EngnTrhrgrWstgtAttr2TmprtrStts : 5|3@1+ (1,0) [0|7] "" Vector__XXX

BO_ 2566714110 EFTVI1: 8 Vector__XXX
 SG_ EngineFuelValve1OperationStatus : 56|4@1+ (1,0) [0|15] "" Vector__XXX
 SG_ EngineFuelValve1PreliminaryFMI : 32|5@1+ (1,0) [0|31] "binary" Vector__XXX
 SG_ EngineFuelValve2OperationStatus : 60|4@1+ (1,0) [0|15] "" Vector__XXX
 SG_ EngineFuelValve2PreliminaryFMI : 40|5@1+ (1,0) [0|31] "binary" Vector__XXX
 SG_ EngnDsrdThrttlVlv1Pstn : 0|8@1+ (0.4,0) [0|100] "%" Vector__XXX
 SG_ EngnDsrdThrttlVlv2Pstn : 16|8@1+ (0.4,0) [0|100] "%" Vector__XXX
 SG_ EngnFlVlv1TmprtrStts : 37|3@1+ (1,0) [0|7] "" Vector__XXX
 SG_ EngnFlVlv2TmprtrStts : 45|3@1+ (1,0) [0|7] "" Vector__XXX
 SG_ EngnThrttlVlv1OprtnStts : 48|4@1+ (1,0) [0|15] "" Vector__XXX
 SG_ EngnThrttlVlv1PrlmnrFMI : 8|5@1+ (1,0) [0|31] "binary" Vector__XXX
 SG_ EngnThrttlVlv1TmprtrStts : 13|3@1+ (1,0) [0|7] "" Vector__XXX
 SG_ EngnThrttlVlv2OprtnStts : 52|4@1+ (1,0) [0|15] "" Vector__XXX
 SG_ EngnThrttlVlv2PrlmnrFMI : 24|5@1+ (1,0) [0|31] "binary" Vector__XXX
 SG_ EngnThrttlVlv2Tmprtrstts : 29|3@1+ (1,0) [0|7] "" Vector__XXX

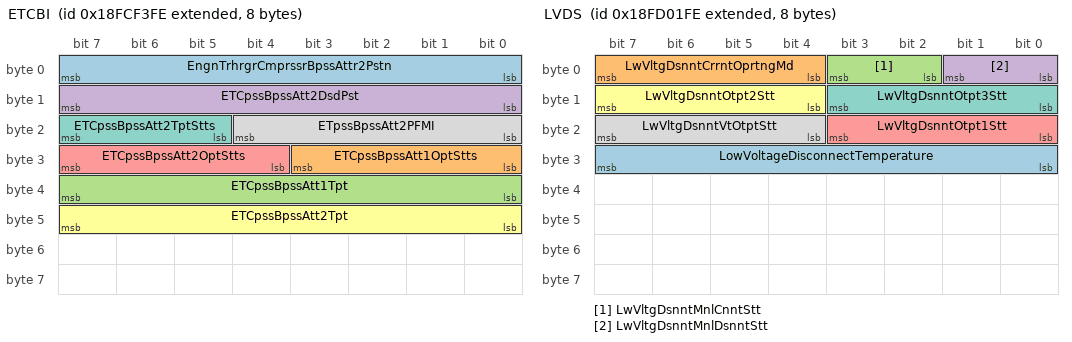
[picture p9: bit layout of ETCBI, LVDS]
BO_ 2566714366 ETCBI: 8 Vector__XXX
 SG_ EngnTrhrgrCmprssrBpssAttr2Pstn : 0|8@1+ (0.4,0) [0|100] "%" Vector__XXX
 SG_ ETCpssBpssAtt1OptStts : 24|4@1+ (1,0) [0|15] "" Vector__XXX
 SG_ ETCpssBpssAtt1Tpt : 32|8@1+ (1,-40) [-40|210] "degC" Vector__XXX
 SG_ ETCpssBpssAtt2DsdPst : 8|8@1+ (0.4,0) [0|100] "%" Vector__XXX
 SG_ ETCpssBpssAtt2OptStts : 28|4@1+ (1,0) [0|15] "" Vector__XXX
 SG_ ETCpssBpssAtt2Tpt : 40|8@1+ (1,-40) [-40|210] "degC" Vector__XXX
 SG_ ETCpssBpssAtt2TptStts : 21|3@1+ (1,0) [0|7] "" Vector__XXX
 SG_ ETpssBpssAtt2PFMI : 16|5@1+ (1,0) [0|31] "binary" Vector__XXX

BO_ 2566714622 CAC2: 8 Vector__XXX
 SG_ EngnChrgArClr2AmntArTmprtr : 32|16@1+ (0.03125,-273) [-273|1734.96875] "degC" Vector__XXX
 SG_ EngnChrgArClr2Effn : 48|8@1+ (0.4,0) [0|100] "%" Vector__XXX
 SG_ EngnChrgArClr2IntkTmprtr : 0|16@1+ (0.03125,-273) [-273|1734.96875] "degC" Vector__XXX
 SG_ EngnChrgArClr2OtltTmprtr : 16|16@1+ (0.03125,-273) [-273|1734.96875] "degC" Vector__XXX

BO_ 2566714878 CAC2P: 8 Vector__XXX
 SG_ EngnChrgArClr2PrlrEffn : 32|8@1+ (0.4,0) [0|100] "%" Vector__XXX
 SG_ EngnChrgArClr2PrlrIntkTmprtr : 0|16@1+ (0.03125,-273) [-273|1734.96875] "degC" Vector__XXX
 SG_ EngnChrgArClr2PrlrOtltTmprtr : 16|16@1+ (0.03125,-273) [-273|1734.96875] "degC" Vector__XXX

BO_ 2566715134 CAC1: 8 Vector__XXX
 SG_ EngnChrgArClr1AmntArTmprtr : 16|16@1+ (0.03125,-273) [-273|1734.96875] "degC" Vector__XXX
 SG_ EngnChrgArClr1Effn : 32|8@1+ (0.4,0) [0|100] "%" Vector__XXX
 SG_ EngnChrgArClr1IntkTmprtr : 0|16@1+ (0.03125,-273) [-273|1734.96875] "degC" Vector__XXX

BO_ 2566715390 CAC1P: 8 Vector__XXX
 SG_ EngnChrgArClr1PrlrEffn : 32|8@1+ (0.4,0) [0|100] "%" Vector__XXX
 SG_ EngnChrgArClr1PrlrIntkTmprtr : 0|16@1+ (0.03125,-273) [-273|1734.96875] "degC" Vector__XXX
 SG_ EngnChrgArClr1PrlrOtltTmprtr : 16|16@1+ (0.03125,-273) [-273|1734.96875] "degC" Vector__XXX

BO_ 2566715646 DPF2S2: 8 Vector__XXX
 SG_ Atttt2DsPttFtStSM : 32|16@1+ (0.0025,0) [0|160.6375] "%" Vector__XXX
 SG_ Atttt2DsPttFtStSMx : 16|16@1+ (0.0025,0) [0|160.6375] "%" Vector__XXX
 SG_ Atttt2DsPttFtStSStddDvt : 0|16@1+ (0.0025,0) [0|160.6375] "%" Vector__XXX

BO_ 2566715902 DPF1S2: 8 Vector__XXX
 SG_ Atttt1DsPttFtStSM : 32|16@1+ (0.0025,0) [0|160.6375] "%" Vector__XXX
 SG_ Atttt1DsPttFtStSMx : 16|16@1+ (0.0025,0) [0|160.6375] "%" Vector__XXX
 SG_ Atttt1DsPttFtStSStddDvt : 0|16@1+ (0.0025,0) [0|160.6375] "%" Vector__XXX

BO_ 2566717438 ET5: 8 Vector__XXX
 SG_ EngnExhstGsRrltn2MxrIntkTmprtr : 16|16@1+ (0.03125,-273) [-273|1734.96875] "degC" Vector__XXX
 SG_ EngnExhstGsRrltn2Tmprtr : 0|16@1+ (0.03125,-273) [-273|1734.96875] "degC" Vector__XXX

BO_ 2566717950 LVDS: 8 Vector__XXX
 SG_ LowVoltageDisconnectTemperature : 24|8@1+ (1,-40) [-40|210] "degC" Vector__XXX
 SG_ LwVltgDsnntCrrntOprtngMd : 4|4@1+ (1,0) [0|15] "" Vector__XXX
 SG_ LwVltgDsnntMnlCnntStt : 2|2@1+ (1,0) [0|3] "" Vector__XXX
 SG_ LwVltgDsnntMnlDsnntStt : 0|2@1+ (1,0) [0|3] "" Vector__XXX
 SG_ LwVltgDsnntOtpt1Stt : 16|4@1+ (1,0) [0|15] "" Vector__XXX
 SG_ LwVltgDsnntOtpt2Stt : 12|4@1+ (1,0) [0|15] "" Vector__XXX
 SG_ LwVltgDsnntOtpt3Stt : 8|4@1+ (1,0) [0|15] "" Vector__XXX
 SG_ LwVltgDsnntVtOtptStt : 20|4@1+ (1,0) [0|15] "" Vector__XXX

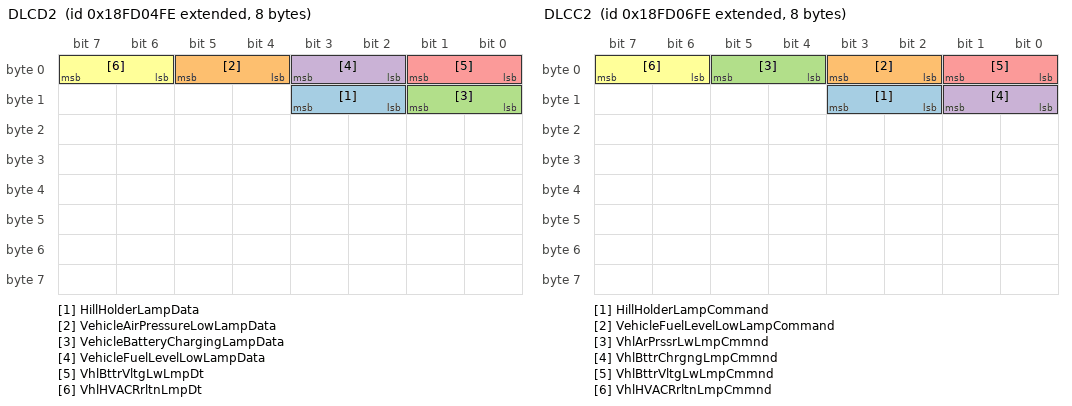
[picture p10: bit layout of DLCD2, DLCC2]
BO_ 2566718718 DLCD2: 8 Vector__XXX
 SG_ HillHolderLampData : 10|2@1+ (1,0) [0|3] "" Vector__XXX
 SG_ VehicleAirPressureLowLampData : 4|2@1+ (1,0) [0|3] "" Vector__XXX
 SG_ VehicleBatteryChargingLampData : 8|2@1+ (1,0) [0|3] "" Vector__XXX
 SG_ VehicleFuelLevelLowLampData : 2|2@1+ (1,0) [0|3] "" Vector__XXX
 SG_ VhlBttrVltgLwLmpDt : 0|2@1+ (1,0) [0|3] "" Vector__XXX
 SG_ VhlHVACRrltnLmpDt : 6|2@1+ (1,0) [0|3] "" Vector__XXX

BO_ 2566718974 DLCD1: 8 Vector__XXX
 SG_ CmprssnBrkEnlSwthIndtrLmpDt : 10|2@1+ (1,0) [0|3] "" Vector__XXX
 SG_ EngineAmberWarningLampData : 2|2@1+ (1,0) [0|3] "" Vector__XXX
 SG_ EngineBrakeActiveLampData : 8|2@1+ (1,0) [0|3] "" Vector__XXX
 SG_ EngineCoolantLevelLowLampData : 16|2@1+ (1,0) [0|3] "" Vector__XXX
 SG_ EngineOilPressureLowLampData : 12|2@1+ (1,0) [0|3] "" Vector__XXX
 SG_ EngineProtectLampData : 0|2@1+ (1,0) [0|3] "" Vector__XXX
 SG_ EngineRedStopLampData : 4|2@1+ (1,0) [0|3] "" Vector__XXX
 SG_ EngineSpeedHighLampData : 30|2@1+ (1,0) [0|3] "" Vector__XXX
 SG_ EngineSpeedVeryHighLampData : 32|2@1+ (1,0) [0|3] "" Vector__XXX
 SG_ EngineWaitToStartLampData : 62|2@1+ (1,0) [0|3] "" Vector__XXX
 SG_ EngnArFltrRstrtnLmpDt : 20|2@1+ (1,0) [0|3] "" Vector__XXX
 SG_ EngnClntTmprtrHghLmpDt : 14|2@1+ (1,0) [0|3] "" Vector__XXX
 SG_ EngnCntrlMdl1RdfrUsLmpDt : 24|2@1+ (1,0) [0|3] "" Vector__XXX
 SG_ EngnCntrlMdl2RdfrUsLmpDt : 26|2@1+ (1,0) [0|3] "" Vector__XXX
 SG_ EngnCntrlMdl3RdfrUsLmpDt : 28|2@1+ (1,0) [0|3] "" Vector__XXX
 SG_ EngnFlFltrRstrtdLmpDt : 22|2@1+ (1,0) [0|3] "" Vector__XXX
 SG_ EngnIdlMngmntAtvLmpDt : 18|2@1+ (1,0) [0|3] "" Vector__XXX
 SG_ OBDMalfunctionIndicatorLampData : 6|2@1+ (1,0) [0|3] "" Vector__XXX
 SG_ VhlAlrtnRtLmtLmpDt : 34|2@1+ (1,0) [0|3] "" Vector__XXX
 SG_ EngnStpStrtAtmtStpAtvLmpDt : 38|2@1+ (1,0) [0|3] "" Vector__XXX
 SG_ EngnStpStrtAtmtStrtFldLmpDt : 40|2@1+ (1,0) [0|3] "" Vector__XXX
 SG_ EngineStopStartEnabledLampData : 42|2@1+ (1,0) [0|3] "" Vector__XXX

BO_ 2566719230 DLCC2: 8 Vector__XXX
 SG_ HillHolderLampCommand : 10|2@1+ (1,0) [0|3] "" Vector__XXX
 SG_ VehicleFuelLevelLowLampCommand : 2|2@1+ (1,0) [0|3] "" Vector__XXX
 SG_ VhlArPrssrLwLmpCmmnd : 4|2@1+ (1,0) [0|3] "" Vector__XXX
 SG_ VhlBttrChrgngLmpCmmnd : 8|2@1+ (1,0) [0|3] "" Vector__XXX
 SG_ VhlBttrVltgLwLmpCmmnd : 0|2@1+ (1,0) [0|3] "" Vector__XXX
 SG_ VhlHVACRrltnLmpCmmnd : 6|2@1+ (1,0) [0|3] "" Vector__XXX

BO_ 2566719486 DLCC1: 8 Vector__XXX
 SG_ CmprssnBrkEnlSwthIndtrLmpCmmnd : 10|2@1+ (1,0) [0|3] "" Vector__XXX
 SG_ EngineAmberWarningLampCommand : 2|2@1+ (1,0) [0|3] "" Vector__XXX
 SG_ EngineBrakeActiveLampCommand : 8|2@1+ (1,0) [0|3] "" Vector__XXX
 SG_ EngineOilPressureLowLampCommand : 12|2@1+ (1,0) [0|3] "" Vector__XXX
 SG_ EngineProtectLampCommand : 0|2@1+ (1,0) [0|3] "" Vector__XXX
 SG_ EngineRedStopLampCommand : 4|2@1+ (1,0) [0|3] "" Vector__XXX
 SG_ EngineSpeedHighLampCommand : 30|2@1+ (1,0) [0|3] "" Vector__XXX
 SG_ EngineSpeedVeryHighLampCommand : 32|2@1+ (1,0) [0|3] "" Vector__XXX
 SG_ EngnArFltrRstrtnLmpCmmnd : 20|2@1+ (1,0) [0|3] "" Vector__XXX
 SG_ EngnClntLvlLwLmpCmmnd : 16|2@1+ (1,0) [0|3] "" Vector__XXX
 SG_ EngnClntTmprtrHghLmpCmmnd : 14|2@1+ (1,0) [0|3] "" Vector__XXX
 SG_ EngnCntrlMdl1RdfrUsLmpCmmnd : 24|2@1+ (1,0) [0|3] "" Vector__XXX
 SG_ EngnCntrlMdl2RdfrUsLmpCmmnd : 26|2@1+ (1,0) [0|3] "" Vector__XXX
 SG_ EngnCntrlMdl3RdfrUsLmpCmmnd : 28|2@1+ (1,0) [0|3] "" Vector__XXX
 SG_ EngnFlFltrRstrtdLmpCmmnd : 22|2@1+ (1,0) [0|3] "" Vector__XXX
 SG_ EngnIdlMngmntAtvLmpCmmnd : 18|2@1+ (1,0) [0|3] "" Vector__XXX
 SG_ EngnIdlMngmntPndngEvntLmpCmmnd : 36|2@1+ (1,0) [0|3] "" Vector__XXX
 SG_ OBDMlfntnIndtrLmpCmmnd : 6|2@1+ (1,0) [0|3] "" Vector__XXX
 SG_ VhlAlrtnRtLmtLmpCmmnd : 34|2@1+ (1,0) [0|3] "" Vector__XXX
 SG_ EngnStpStrtAtmtStpAtvLmpCmmnd : 38|2@1+ (1,0) [0|3] "" Vector__XXX
 SG_ EngnStpStrtAtmtStrtFldLmpCmmnd : 40|2@1+ (1,0) [0|3] "" Vector__XXX
 SG_ EngnStpStrtEnldLmpCmmnd : 42|2@1+ (1,0) [0|3] "" Vector__XXX

BO_ 2566719998 HRLFC: 8 Vector__XXX
 SG_ EngineTripFuelHighResolution : 0|32@1+ (0.001,0) [0|4211081.215] "l" Vector__XXX
 SG_ EngnTtlFlUsdHghRsltn : 32|32@1+ (0.001,0) [0|4211081.215] "l" Vector__XXX

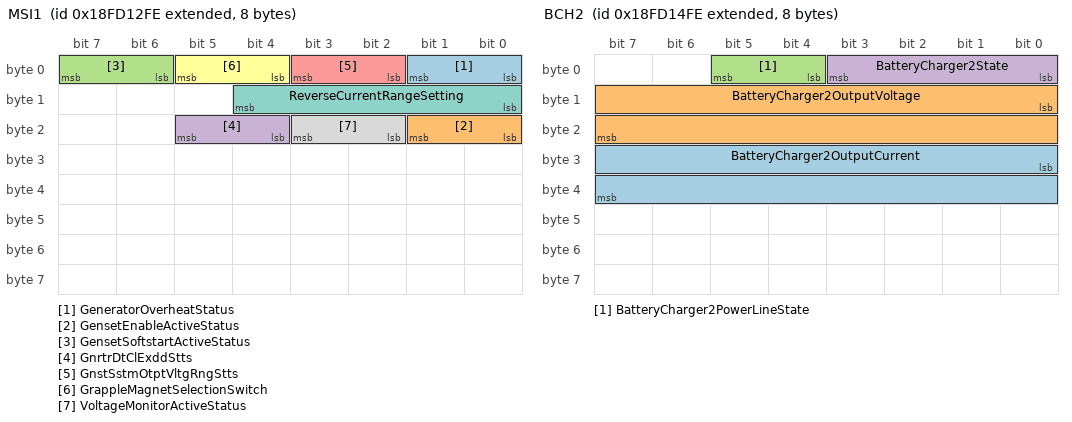
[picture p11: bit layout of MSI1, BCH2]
BO_ 2566722302 MSI1: 8 Vector__XXX
 SG_ GeneratorOverheatStatus : 0|2@1+ (1,0) [0|3] "" Vector__XXX
 SG_ GensetEnableActiveStatus : 16|2@1+ (1,0) [0|3] "" Vector__XXX
 SG_ GensetSoftstartActiveStatus : 6|2@1+ (1,0) [0|3] "" Vector__XXX
 SG_ GnrtrDtClExddStts : 20|2@1+ (1,0) [0|3] "" Vector__XXX
 SG_ GnstSstmOtptVltgRngStts : 2|2@1+ (1,0) [0|3] "" Vector__XXX
 SG_ GrappleMagnetSelectionSwitch : 4|2@1+ (1,0) [0|3] "" Vector__XXX
 SG_ ReverseCurrentRangeSetting : 8|5@1+ (1,0) [0|31] "" Vector__XXX
 SG_ VoltageMonitorActiveStatus : 18|2@1+ (1,0) [0|3] "" Vector__XXX

BO_ 2566722558 MSCI: 8 Vector__XXX
 SG_ MagnetBoostTime : 0|8@1+ (0.25,0) [0|62.5] "s" Vector__XXX
 SG_ MagnetRatedPower : 8|16@1+ (0.5,0) [0|32127.5] "kW" Vector__XXX

BO_ 2566722814 BCH2: 8 Vector__XXX
 SG_ BatteryCharger2OutputCurrent : 24|16@1+ (0.05,-1600) [-1600|1612.75] "A" Vector__XXX
 SG_ BatteryCharger2OutputVoltage : 8|16@1+ (0.05,0) [0|3212.75] "V" Vector__XXX
 SG_ BatteryCharger2PowerLineState : 4|2@1+ (1,0) [0|3] "" Vector__XXX
 SG_ BatteryCharger2State : 0|4@1+ (1,0) [0|15] "" Vector__XXX

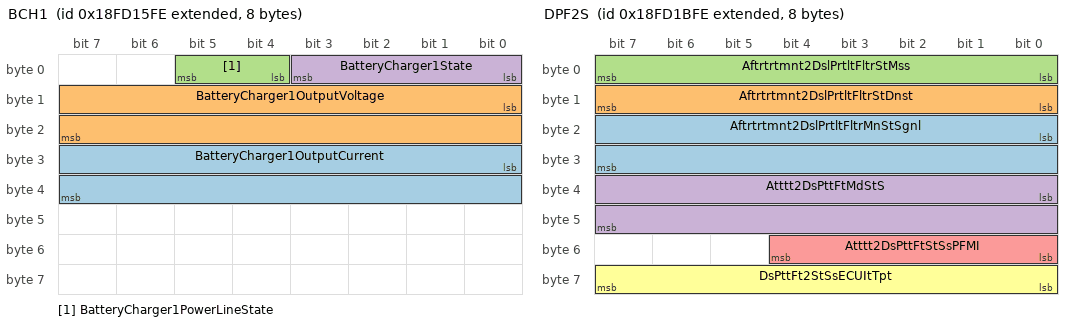
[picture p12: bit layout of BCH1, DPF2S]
BO_ 2566723070 BCH1: 8 Vector__XXX
 SG_ BatteryCharger1OutputCurrent : 24|16@1+ (0.05,-1600) [-1600|1612.75] "A" Vector__XXX
 SG_ BatteryCharger1OutputVoltage : 8|16@1+ (0.05,0) [0|3212.75] "V" Vector__XXX
 SG_ BatteryCharger1PowerLineState : 4|2@1+ (1,0) [0|3] "" Vector__XXX
 SG_ BatteryCharger1State : 0|4@1+ (1,0) [0|15] "" Vector__XXX

BO_ 2566724350 AT1WUDOC: 8 Vector__XXX
 SG_ Atttt1WUpDsOxdtCtstItTpt : 0|16@1+ (0.03125,-273) [-273|1734.96875] "degC" Vector__XXX
 SG_ Atttt1WUpDsOxdtCtstOttTpt : 16|16@1+ (0.03125,-273) [-273|1734.96875] "degC" Vector__XXX

BO_ 2566724606 DPF2S: 8 Vector__XXX
 SG_ Aftrtrtmnt2DslPrtltFltrMnStSgnl : 16|16@1+ (0.0025,0) [0|160.6375] "%" Vector__XXX
 SG_ Aftrtrtmnt2DslPrtltFltrStDnst : 8|8@1+ (0.08,0) [0|20] "g/L" Vector__XXX
 SG_ Aftrtrtmnt2DslPrtltFltrStMss : 0|8@1+ (4,0) [0|1000] "g" Vector__XXX
 SG_ Atttt2DsPttFtMdStS : 32|16@1+ (0.0025,0) [0|160.6375] "%" Vector__XXX
 SG_ Atttt2DsPttFtStSsPFMI : 48|5@1+ (1,0) [0|31] "binary" Vector__XXX
 SG_ DsPttFt2StSsECUItTpt : 56|8@1+ (1,-40) [-40|210] "degC" Vector__XXX

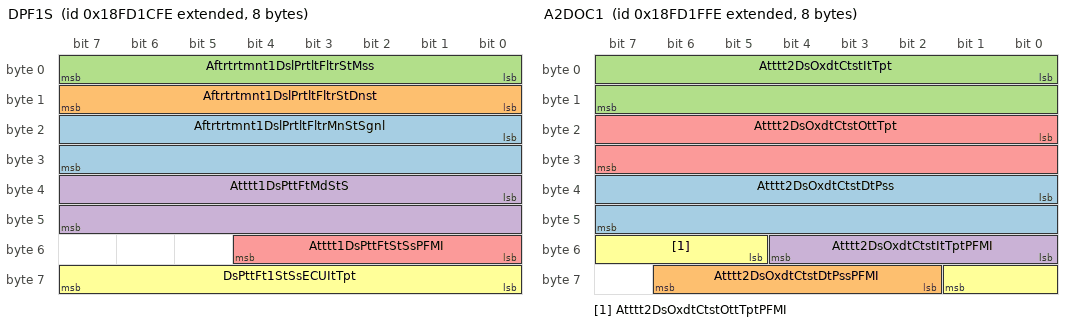
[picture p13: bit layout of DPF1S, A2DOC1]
BO_ 2566724862 DPF1S: 8 Vector__XXX
 SG_ Aftrtrtmnt1DslPrtltFltrMnStSgnl : 16|16@1+ (0.0025,0) [0|160.6375] "%" Vector__XXX
 SG_ Aftrtrtmnt1DslPrtltFltrStDnst : 8|8@1+ (0.08,0) [0|20] "g/L" Vector__XXX
 SG_ Aftrtrtmnt1DslPrtltFltrStMss : 0|8@1+ (4,0) [0|1000] "g" Vector__XXX
 SG_ Atttt1DsPttFtMdStS : 32|16@1+ (0.0025,0) [0|160.6375] "%" Vector__XXX
 SG_ Atttt1DsPttFtStSsPFMI : 48|5@1+ (1,0) [0|31] "binary" Vector__XXX
 SG_ DsPttFt1StSsECUItTpt : 56|8@1+ (1,-40) [-40|210] "degC" Vector__XXX

BO_ 2566725118 ATDT2: 8 Vector__XXX
 SG_ Atttt1TWCtstDtTpt : 0|16@1+ (0.03125,-273) [-273|1734.96875] "degC" Vector__XXX
 SG_ Atttt2TWCtstDtTpt : 16|16@1+ (0.03125,-273) [-273|1734.96875] "degC" Vector__XXX

BO_ 2566725374 ATDT1: 8 Vector__XXX
 SG_ Atttt1GsOxdtCtstDtTpt : 0|16@1+ (0.03125,-273) [-273|1734.96875] "degC" Vector__XXX
 SG_ Atttt2GsOxdtCtstDtTpt : 16|16@1+ (0.03125,-273) [-273|1734.96875] "degC" Vector__XXX

BO_ 2566725630 A2DOC1: 8 Vector__XXX
 SG_ Atttt2DsOxdtCtstDtPss : 32|16@1+ (0.5,0) [0|32127.5] "kPa" Vector__XXX
 SG_ Atttt2DsOxdtCtstDtPssPFMI : 58|5@1+ (1,0) [0|31] "binary" Vector__XXX
 SG_ Atttt2DsOxdtCtstItTpt : 0|16@1+ (0.03125,-273) [-273|1734.96875] "degC" Vector__XXX
 SG_ Atttt2DsOxdtCtstItTptPFMI : 48|5@1+ (1,0) [0|31] "binary" Vector__XXX
 SG_ Atttt2DsOxdtCtstOttTpt : 16|16@1+ (0.03125,-273) [-273|1734.96875] "degC" Vector__XXX
 SG_ Atttt2DsOxdtCtstOttTptPFMI : 53|5@1+ (1,0) [0|31] "binary" Vector__XXX

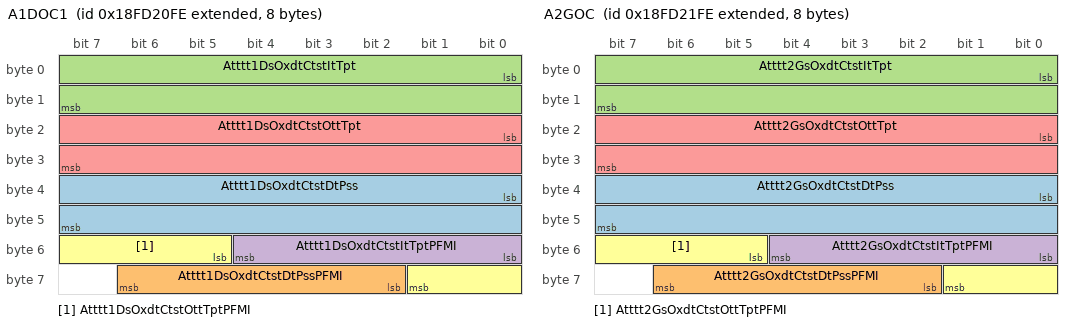
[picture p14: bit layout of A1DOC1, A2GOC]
BO_ 2566725886 A1DOC1: 8 Vector__XXX
 SG_ Atttt1DsOxdtCtstDtPss : 32|16@1+ (0.1,0) [0|6425.5] "kPa" Vector__XXX
 SG_ Atttt1DsOxdtCtstDtPssPFMI : 58|5@1+ (1,0) [0|31] "binary" Vector__XXX
 SG_ Atttt1DsOxdtCtstItTpt : 0|16@1+ (0.03125,-273) [-273|1734.96875] "degC" Vector__XXX
 SG_ Atttt1DsOxdtCtstItTptPFMI : 48|5@1+ (1,0) [0|31] "binary" Vector__XXX
 SG_ Atttt1DsOxdtCtstOttTpt : 16|16@1+ (0.03125,-273) [-273|1734.96875] "degC" Vector__XXX
 SG_ Atttt1DsOxdtCtstOttTptPFMI : 53|5@1+ (1,0) [0|31] "binary" Vector__XXX

BO_ 2566726142 A2GOC: 8 Vector__XXX
 SG_ Atttt2GsOxdtCtstDtPss : 32|16@1+ (0.1,0) [0|6425.5] "kPa" Vector__XXX
 SG_ Atttt2GsOxdtCtstDtPssPFMI : 58|5@1+ (1,0) [0|31] "binary" Vector__XXX
 SG_ Atttt2GsOxdtCtstItTpt : 0|16@1+ (0.03125,-273) [-273|1734.96875] "degC" Vector__XXX
 SG_ Atttt2GsOxdtCtstItTptPFMI : 48|5@1+ (1,0) [0|31] "binary" Vector__XXX
 SG_ Atttt2GsOxdtCtstOttTpt : 16|16@1+ (0.03125,-273) [-273|1734.96875] "degC" Vector__XXX
 SG_ Atttt2GsOxdtCtstOttTptPFMI : 53|5@1+ (1,0) [0|31] "binary" Vector__XXX

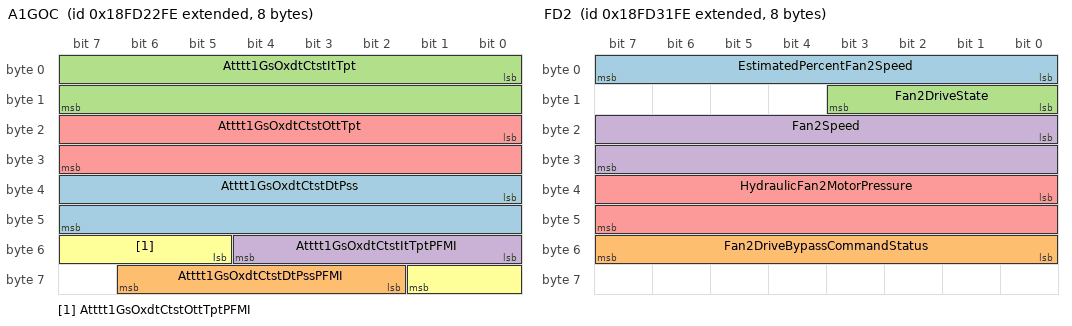
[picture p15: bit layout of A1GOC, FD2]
BO_ 2566726398 A1GOC: 8 Vector__XXX
 SG_ Atttt1GsOxdtCtstDtPss : 32|16@1+ (0.1,0) [0|6425.5] "kPa" Vector__XXX
 SG_ Atttt1GsOxdtCtstDtPssPFMI : 58|5@1+ (1,0) [0|31] "binary" Vector__XXX
 SG_ Atttt1GsOxdtCtstItTpt : 0|16@1+ (0.03125,-273) [-273|1734.96875] "degC" Vector__XXX
 SG_ Atttt1GsOxdtCtstItTptPFMI : 48|5@1+ (1,0) [0|31] "binary" Vector__XXX
 SG_ Atttt1GsOxdtCtstOttTpt : 16|16@1+ (0.03125,-273) [-273|1734.96875] "degC" Vector__XXX
 SG_ Atttt1GsOxdtCtstOttTptPFMI : 53|5@1+ (1,0) [0|31] "binary" Vector__XXX

BO_ 2566730238 FD2: 8 Vector__XXX
 SG_ EstimatedPercentFan2Speed : 0|8@1+ (0.4,0) [0|100] "%" Vector__XXX
 SG_ Fan2DriveBypassCommandStatus : 48|8@1+ (0.4,0) [0|100] "%" Vector__XXX
 SG_ Fan2DriveState : 8|4@1+ (1,0) [0|15] "" Vector__XXX
 SG_ Fan2Speed : 16|16@1+ (0.125,0) [0|8031.875] "rpm" Vector__XXX
 SG_ HydraulicFan2MotorPressure : 32|16@1+ (0.5,0) [0|32127.5] "kPa" Vector__XXX

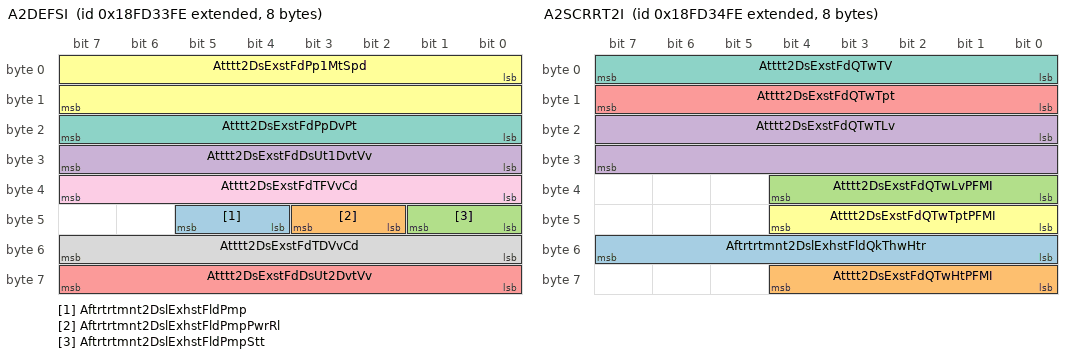
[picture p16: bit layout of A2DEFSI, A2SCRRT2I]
BO_ 2566730750 A2DEFSI: 8 Vector__XXX
 SG_ Aftrtrtmnt2DslExhstFldPmp : 44|2@1+ (1,0) [0|3] "" Vector__XXX
 SG_ Aftrtrtmnt2DslExhstFldPmpPwrRl : 42|2@1+ (1,0) [0|3] "" Vector__XXX
 SG_ Aftrtrtmnt2DslExhstFldPmpStt : 40|2@1+ (1,0) [0|3] "" Vector__XXX
 SG_ Atttt2DsExstFdDsUt1DvtVv : 24|8@1+ (0.4,0) [0|100] "%" Vector__XXX
 SG_ Atttt2DsExstFdDsUt2DvtVv : 56|8@1+ (0.4,0) [0|100] "%" Vector__XXX
 SG_ Atttt2DsExstFdPp1MtSpd : 0|16@1+ (0.5,0) [0|32127.5] "rpm" Vector__XXX
 SG_ Atttt2DsExstFdPpDvPt : 16|8@1+ (0.4,0) [0|100] "%" Vector__XXX
 SG_ Atttt2DsExstFdTDVvCd : 48|8@1+ (0.4,0) [0|100] "%" Vector__XXX
 SG_ Atttt2DsExstFdTFVvCd : 32|8@1+ (0.4,0) [0|100] "%" Vector__XXX

BO_ 2566731006 A2SCRRT2I: 8 Vector__XXX
 SG_ Aftrtrtmnt2DslExhstFldQkThwHtr : 48|8@1+ (0.4,0) [0|100] "%" Vector__XXX
 SG_ Atttt2DsExstFdQTwHtPFMI : 56|5@1+ (1,0) [0|31] "binary" Vector__XXX
 SG_ Atttt2DsExstFdQTwLvPFMI : 32|5@1+ (1,0) [0|31] "binary" Vector__XXX
 SG_ Atttt2DsExstFdQTwTLv : 16|16@1+ (0.1,0) [0|6425.5] "mm" Vector__XXX
 SG_ Atttt2DsExstFdQTwTpt : 8|8@1+ (1,-40) [-40|210] "degC" Vector__XXX
 SG_ Atttt2DsExstFdQTwTptPFMI : 40|5@1+ (1,0) [0|31] "binary" Vector__XXX
 SG_ Atttt2DsExstFdQTwTV : 0|8@1+ (0.4,0) [0|100] "%" Vector__XXX

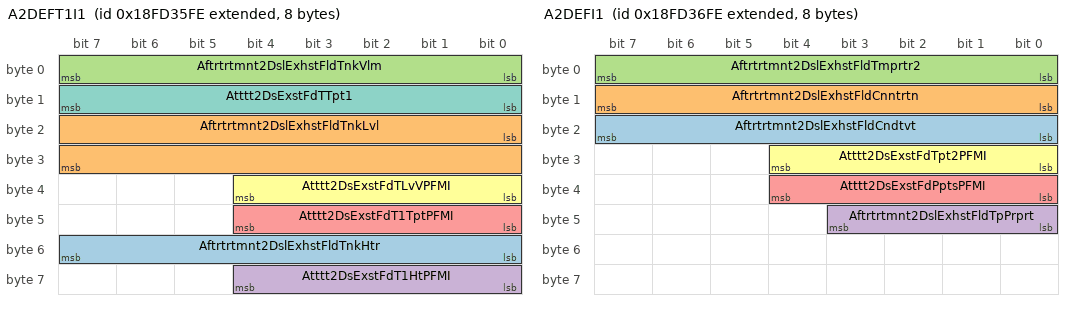
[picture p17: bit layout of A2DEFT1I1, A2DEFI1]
BO_ 2566731262 A2DEFT1I1: 8 Vector__XXX
 SG_ Aftrtrtmnt2DslExhstFldTnkHtr : 48|8@1+ (0.4,0) [0|100] "%" Vector__XXX
 SG_ Aftrtrtmnt2DslExhstFldTnkLvl : 16|16@1+ (0.1,0) [0|6425.5] "mm" Vector__XXX
 SG_ Aftrtrtmnt2DslExhstFldTnkVlm : 0|8@1+ (0.4,0) [0|100] "%" Vector__XXX
 SG_ Atttt2DsExstFdT1HtPFMI : 56|5@1+ (1,0) [0|31] "binary" Vector__XXX
 SG_ Atttt2DsExstFdT1TptPFMI : 40|5@1+ (1,0) [0|31] "binary" Vector__XXX
 SG_ Atttt2DsExstFdTLvVPFMI : 32|5@1+ (1,0) [0|31] "binary" Vector__XXX
 SG_ Atttt2DsExstFdTTpt1 : 8|8@1+ (1,-40) [-40|210] "degC" Vector__XXX

BO_ 2566731518 A2DEFI1: 8 Vector__XXX
 SG_ Aftrtrtmnt2DslExhstFldCndtvt : 16|8@1+ (5,0) [0|1250] "µSiemens/mm" Vector__XXX
 SG_ Aftrtrtmnt2DslExhstFldCnntrtn : 8|8@1+ (0.25,0) [0|62.5] "%" Vector__XXX
 SG_ Aftrtrtmnt2DslExhstFldTmprtr2 : 0|8@1+ (1,-40) [-40|210] "degC" Vector__XXX
 SG_ Aftrtrtmnt2DslExhstFldTpPrprt : 40|4@1+ (1,0) [0|15] "" Vector__XXX
 SG_ Atttt2DsExstFdPptsPFMI : 32|5@1+ (1,0) [0|31] "binary" Vector__XXX
 SG_ Atttt2DsExstFdTpt2PFMI : 24|5@1+ (1,0) [0|31] "binary" Vector__XXX

BO_ 2566731774 A2SCRSI1: 8 Vector__XXX
 SG_ Aftrtrtmnt2SCRCnvrsnEffn : 32|8@1+ (0.4,0) [0|100] "%" Vector__XXX
 SG_ Aftrtrtmnt2SCRSstmSlftnLvl : 40|8@1+ (1,0) [0|250] "%" Vector__XXX
 SG_ Atttt2DsExstFdAvCspt : 0|16@1+ (0.05,0) [0|3212.75] "l/h" Vector__XXX
 SG_ Atttt2SCRCddDsExstFdCspt : 16|16@1+ (0.05,0) [0|3212.75] "l/h" Vector__XXX

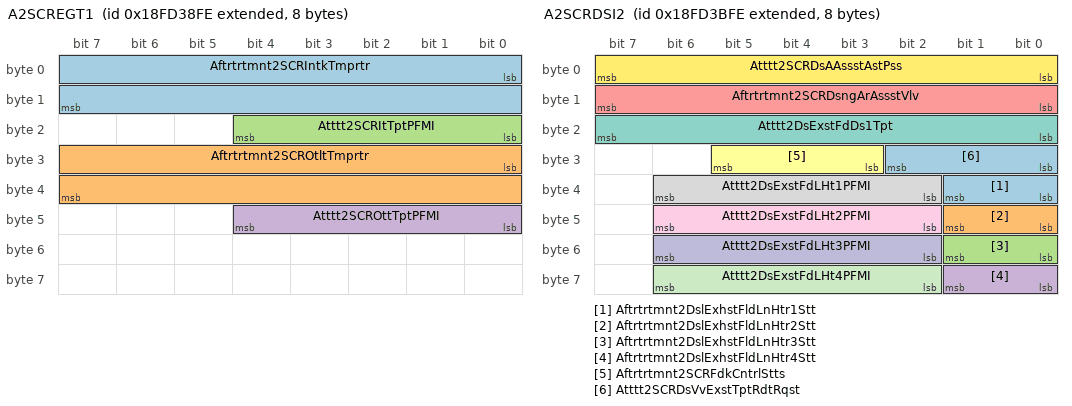
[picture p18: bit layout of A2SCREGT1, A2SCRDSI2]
BO_ 2566732030 A2SCREGT1: 8 Vector__XXX
 SG_ Aftrtrtmnt2SCRIntkTmprtr : 0|16@1+ (0.03125,-273) [-273|1734.96875] "degC" Vector__XXX
 SG_ Aftrtrtmnt2SCROtltTmprtr : 24|16@1+ (0.03125,-273) [-273|1734.96875] "degC" Vector__XXX
 SG_ Atttt2SCRItTptPFMI : 16|5@1+ (1,0) [0|31] "" Vector__XXX
 SG_ Atttt2SCROttTptPFMI : 40|5@1+ (1,0) [0|31] "" Vector__XXX

BO_ 2566732286 A2SCREGP: 8 Vector__XXX
 SG_ Aftrtrtmnt2SCRDffrntlPrssr : 0|16@1+ (0.1,0) [0|6425.5] "kPa" Vector__XXX
 SG_ Aftrtrtmnt2SCRIntkAsltPrssr : 40|16@1+ (0.1,0) [0|6425.5] "kPa" Vector__XXX
 SG_ Aftrtrtmnt2SCRIntkPrssr : 24|16@1+ (0.1,-3212.7) [-3212.7|3212.8] "kPa" Vector__XXX
 SG_ Atttt2SCRDtPssPFMI : 16|5@1+ (1,0) [0|31] "" Vector__XXX

BO_ 2566732542 A2SCRDSR2: 8 Vector__XXX
 SG_ Aftrtrtmnt2DslExhstFldLnHtr1 : 8|2@1+ (1,0) [0|3] "" Vector__XXX
 SG_ Aftrtrtmnt2DslExhstFldLnHtr10 : 48|2@1+ (1,0) [0|3] "" Vector__XXX
 SG_ Aftrtrtmnt2DslExhstFldLnHtr2 : 10|2@1+ (1,0) [0|3] "" Vector__XXX
 SG_ Aftrtrtmnt2DslExhstFldLnHtr3 : 12|2@1+ (1,0) [0|3] "" Vector__XXX
 SG_ Aftrtrtmnt2DslExhstFldLnHtr4 : 14|2@1+ (1,0) [0|3] "" Vector__XXX
 SG_ Aftrtrtmnt2DslExhstFldLnHtr5 : 38|2@1+ (1,0) [0|3] "" Vector__XXX
 SG_ Aftrtrtmnt2DslExhstFldLnHtr6 : 40|2@1+ (1,0) [0|3] "" Vector__XXX
 SG_ Aftrtrtmnt2DslExhstFldLnHtr7 : 42|2@1+ (1,0) [0|3] "" Vector__XXX
 SG_ Aftrtrtmnt2DslExhstFldLnHtr8 : 44|2@1+ (1,0) [0|3] "" Vector__XXX
 SG_ Aftrtrtmnt2DslExhstFldLnHtr9 : 46|2@1+ (1,0) [0|3] "" Vector__XXX
 SG_ Aftrtrtmnt2DslExhstFldLnHtrRl1 : 32|2@1+ (1,0) [0|3] "" Vector__XXX
 SG_ Aftrtrtmnt2DslExhstFldLnHtrRl2 : 34|2@1+ (1,0) [0|3] "" Vector__XXX
 SG_ Aftrtrtmnt2DslExhstFldLnHtrRl3 : 36|2@1+ (1,0) [0|3] "" Vector__XXX
 SG_ Atttt2DsExstFdDsFtSppssRqst : 2|2@1+ (1,0) [0|3] "" Vector__XXX
 SG_ Atttt2DsExstFdDsHtMdRqst : 4|3@1+ (1,0) [0|7] "" Vector__XXX
 SG_ Atttt2DsExstFdQTwHtCd : 24|8@1+ (0.4,0) [0|100] "%" Vector__XXX
 SG_ Atttt2DsExstFdTHtCd : 16|8@1+ (0.4,0) [0|100] "%" Vector__XXX

BO_ 2566732798 A2SCRDSI2: 8 Vector__XXX
 SG_ Aftrtrtmnt2DslExhstFldLnHtr1Stt : 32|2@1+ (1,0) [0|3] "" Vector__XXX
 SG_ Aftrtrtmnt2DslExhstFldLnHtr2Stt : 40|2@1+ (1,0) [0|3] "" Vector__XXX
 SG_ Aftrtrtmnt2DslExhstFldLnHtr3Stt : 48|2@1+ (1,0) [0|3] "" Vector__XXX
 SG_ Aftrtrtmnt2DslExhstFldLnHtr4Stt : 56|2@1+ (1,0) [0|3] "" Vector__XXX
 SG_ Aftrtrtmnt2SCRDsngArAssstVlv : 8|8@1+ (0.4,0) [0|100] "%" Vector__XXX
 SG_ Aftrtrtmnt2SCRFdkCntrlStts : 27|3@1+ (1,0) [0|7] "" Vector__XXX
 SG_ Atttt2DsExstFdDs1Tpt : 16|8@1+ (1,-40) [-40|210] "degC" Vector__XXX
 SG_ Atttt2DsExstFdLHt1PFMI : 34|5@1+ (1,0) [0|31] "binary" Vector__XXX
 SG_ Atttt2DsExstFdLHt2PFMI : 42|5@1+ (1,0) [0|31] "binary" Vector__XXX
 SG_ Atttt2DsExstFdLHt3PFMI : 50|5@1+ (1,0) [0|31] "binary" Vector__XXX
 SG_ Atttt2DsExstFdLHt4PFMI : 58|5@1+ (1,0) [0|31] "binary" Vector__XXX
 SG_ Atttt2SCRDsAAssstAstPss : 0|8@1+ (8,0) [0|2000] "kPa" Vector__XXX
 SG_ Atttt2SCRDsVvExstTptRdtRqst : 24|3@1+ (1,0) [0|7] "" Vector__XXX

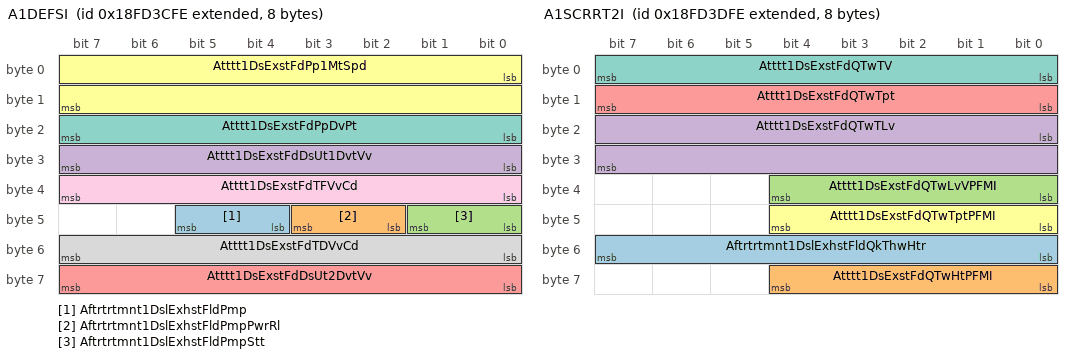
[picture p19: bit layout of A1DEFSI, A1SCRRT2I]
BO_ 2566733054 A1DEFSI: 8 Vector__XXX
 SG_ Aftrtrtmnt1DslExhstFldPmp : 44|2@1+ (1,0) [0|3] "" Vector__XXX
 SG_ Aftrtrtmnt1DslExhstFldPmpPwrRl : 42|2@1+ (1,0) [0|3] "" Vector__XXX
 SG_ Aftrtrtmnt1DslExhstFldPmpStt : 40|2@1+ (1,0) [0|3] "" Vector__XXX
 SG_ Atttt1DsExstFdDsUt1DvtVv : 24|8@1+ (0.4,0) [0|100] "%" Vector__XXX
 SG_ Atttt1DsExstFdDsUt2DvtVv : 56|8@1+ (0.4,0) [0|100] "%" Vector__XXX
 SG_ Atttt1DsExstFdPp1MtSpd : 0|16@1+ (0.5,0) [0|32127.5] "rpm" Vector__XXX
 SG_ Atttt1DsExstFdPpDvPt : 16|8@1+ (0.4,0) [0|100] "%" Vector__XXX
 SG_ Atttt1DsExstFdTDVvCd : 48|8@1+ (0.4,0) [0|100] "%" Vector__XXX
 SG_ Atttt1DsExstFdTFVvCd : 32|8@1+ (0.4,0) [0|100] "%" Vector__XXX

BO_ 2566733310 A1SCRRT2I: 8 Vector__XXX
 SG_ Aftrtrtmnt1DslExhstFldQkThwHtr : 48|8@1+ (0.4,0) [0|100] "%" Vector__XXX
 SG_ Atttt1DsExstFdQTwHtPFMI : 56|5@1+ (1,0) [0|31] "binary" Vector__XXX
 SG_ Atttt1DsExstFdQTwLvVPFMI : 32|5@1+ (1,0) [0|31] "binary" Vector__XXX
 SG_ Atttt1DsExstFdQTwTLv : 16|16@1+ (0.1,0) [0|6425.5] "mm" Vector__XXX
 SG_ Atttt1DsExstFdQTwTpt : 8|8@1+ (1,-40) [-40|210] "degC" Vector__XXX
 SG_ Atttt1DsExstFdQTwTptPFMI : 40|5@1+ (1,0) [0|31] "binary" Vector__XXX
 SG_ Atttt1DsExstFdQTwTV : 0|8@1+ (0.4,0) [0|100] "%" Vector__XXX

BO_ 2566733822 A1SCREGP: 8 Vector__XXX
 SG_ Aftrtrtmnt1SCRDffrntlPrssr : 0|16@1+ (0.1,0) [0|6425.5] "kPa" Vector__XXX
 SG_ Aftrtrtmnt1SCRIntkAsltPrssr : 40|16@1+ (0.1,0) [0|6425.5] "kPa" Vector__XXX
 SG_ Aftrtrtmnt1SCRIntkPrssr : 24|16@1+ (0.1,-3212.7) [-3212.7|3212.8] "kPa" Vector__XXX
 SG_ Atttt1SCRDtPssPFMI : 16|5@1+ (1,0) [0|31] "" Vector__XXX

BO_ 2566734078 A1SCRDSR2: 8 Vector__XXX
 SG_ Aftrtrtmnt1DslExhstFldLnHtr1 : 8|2@1+ (1,0) [0|3] "" Vector__XXX
 SG_ Aftrtrtmnt1DslExhstFldLnHtr10 : 56|2@1+ (1,0) [0|3] "" Vector__XXX
 SG_ Aftrtrtmnt1DslExhstFldLnHtr2 : 10|2@1+ (1,0) [0|3] "" Vector__XXX
 SG_ Aftrtrtmnt1DslExhstFldLnHtr3 : 12|2@1+ (1,0) [0|3] "" Vector__XXX
 SG_ Aftrtrtmnt1DslExhstFldLnHtr4 : 14|2@1+ (1,0) [0|3] "" Vector__XXX
 SG_ Aftrtrtmnt1DslExhstFldLnHtr5 : 46|2@1+ (1,0) [0|3] "" Vector__XXX
 SG_ Aftrtrtmnt1DslExhstFldLnHtr6 : 48|2@1+ (1,0) [0|3] "" Vector__XXX
 SG_ Aftrtrtmnt1DslExhstFldLnHtr7 : 50|2@1+ (1,0) [0|3] "" Vector__XXX
 SG_ Aftrtrtmnt1DslExhstFldLnHtr8 : 52|2@1+ (1,0) [0|3] "" Vector__XXX
 SG_ Aftrtrtmnt1DslExhstFldLnHtr9 : 54|2@1+ (1,0) [0|3] "" Vector__XXX
 SG_ Aftrtrtmnt1DslExhstFldLnHtrRl1 : 40|2@1+ (1,0) [0|3] "" Vector__XXX
 SG_ Aftrtrtmnt1DslExhstFldLnHtrRl2 : 42|2@1+ (1,0) [0|3] "" Vector__XXX
 SG_ Aftrtrtmnt1DslExhstFldLnHtrRl3 : 44|2@1+ (1,0) [0|3] "" Vector__XXX
 SG_ Atttt1DsExstFdDsFtSppssRqst : 2|2@1+ (1,0) [0|3] "" Vector__XXX
 SG_ Atttt1DsExstFdDsHtMdRqst : 4|3@1+ (1,0) [0|7] "" Vector__XXX
 SG_ Atttt1DsExstFdPpHtCd : 32|8@1+ (0.4,0) [0|100] "%" Vector__XXX
 SG_ Atttt1DsExstFdQTwHtCd : 24|8@1+ (0.4,0) [0|100] "%" Vector__XXX
 SG_ Atttt1DsExstFdTHtCd : 16|8@1+ (0.4,0) [0|100] "%" Vector__XXX

CM_ BO_ 2566697982 "Fused Power Output Current";
CM_ SG_ 2566697982 FusedOutput10Current "Measured electrical current flowing out of Power Distribution Module (PDM) Fused Output #10.…";
CM_ SG_ 2566697982 FusedOutput11Current "Measured electrical current flowing out of Power Distribution Module (PDM) Fused Output #11.…";
CM_ SG_ 2566697982 FusedOutput12Current "Measured electrical current flowing out of Power Distribution Module (PDM) Fused Output #12.…";
CM_ SG_ 2566697982 FusedOutput13Current "Measured electrical current flowing out of Power Distribution Module (PDM) Fused Output #13.…";
CM_ SG_ 2566697982 FusedOutput14Current "Measured electrical current flowing out of Power Distribution Module (PDM) Fused Output #14.…";
CM_ SG_ 2566697982 FusedOutput15Current "Measured electrical current flowing out of Power Distribution Module (PDM) Fused Output #15.…";
CM_ SG_ 2566697982 FusedOutput16Current "Measured electrical current flowing out of Power Distribution Module (PDM) Fused Output #16.…";
CM_ SG_ 2566697982 FusedOutput17Current "Measured electrical current flowing out of Power Distribution Module (PDM) Fused Output #17.…";
CM_ SG_ 2566697982 FusedOutput18Current "Measured electrical current flowing out of Power Distribution Module (PDM) Fused Output #18.…";
CM_ SG_ 2566697982 FusedOutput19Current "Measured electrical current flowing out of Power Distribution Module (PDM) Fused Output #19.…";
CM_ SG_ 2566697982 FusedOutput1Current "Measured electrical current flowing out of Power Distribution Module (PDM) Fused Output #1.…";
CM_ SG_ 2566697982 FusedOutput20Current "Measured electrical current flowing out of Power Distribution Module (PDM) Fused Output #20.…";
CM_ SG_ 2566697982 FusedOutput21Current "Measured electrical current flowing out of Power Distribution Module (PDM) Fused Output #21.…";
CM_ SG_ 2566697982 FusedOutput22Current "Measured electrical current flowing out of Power Distribution Module (PDM) Fused Output #22.…";
CM_ SG_ 2566697982 FusedOutput23Current "Measured electrical current flowing out of Power Distribution Module (PDM) Fused Output #23.…";
CM_ SG_ 2566697982 FusedOutput24Current "Measured electrical current flowing out of Power Distribution Module (PDM) Fused Output #24.…";
CM_ SG_ 2566697982 FusedOutput25Current "Measured electrical current flowing out of Power Distribution Module (PDM) Fused Output #25.…";
CM_ SG_ 2566697982 FusedOutput26Current "Measured electrical current flowing out of Power Distribution Module (PDM) Fused Output #26.…";
CM_ SG_ 2566697982 FusedOutput27Current "Measured electrical current flowing out of Power Distribution Module (PDM) Fused Output #27.…";
CM_ SG_ 2566697982 FusedOutput28Current "Measured electrical current flowing out of Power Distribution Module (PDM) Fused Output #28.…";
CM_ SG_ 2566697982 FusedOutput29Current "Measured electrical current flowing out of Power Distribution Module (PDM) Fused Output #29.…";
CM_ SG_ 2566697982 FusedOutput2Current "Measured electrical current flowing out of Power Distribution Module (PDM) Fused Output #2.…";
CM_ SG_ 2566697982 FusedOutput30Current "Measured electrical current flowing out of Power Distribution Module (PDM) Fused Output #30.…";
CM_ SG_ 2566697982 FusedOutput31Current "Measured electrical current flowing out of Power Distribution Module (PDM) Fused Output #31.…";
CM_ SG_ 2566697982 FusedOutput32Current "Measured electrical current flowing out of Power Distribution Module (PDM) Fused Output #32.…";
CM_ SG_ 2566697982 FusedOutput3Current "Measured electrical current flowing out of Power Distribution Module (PDM) Fused Output #3.…";
CM_ SG_ 2566697982 FusedOutput4Current "Measured electrical current flowing out of Power Distribution Module (PDM) Fused Output #4.…";
CM_ SG_ 2566697982 FusedOutput5Current "Measured electrical current flowing out of Power Distribution Module (PDM) Fused Output #5.…";
CM_ SG_ 2566697982 FusedOutput6Current "Measured electrical current flowing out of Power Distribution Module (PDM) Fused Output #6.…";
CM_ SG_ 2566697982 FusedOutput7Current "Measured electrical current flowing out of Power Distribution Module (PDM) Fused Output #7.…";
CM_ SG_ 2566697982 FusedOutput8Current "Measured electrical current flowing out of Power Distribution Module (PDM) Fused Output #8.…";
CM_ SG_ 2566697982 FusedOutput9Current "Measured electrical current flowing out of Power Distribution Module (PDM) Fused Output #9.…";
CM_ BO_ 2566698238 "Switched Power Output Status";
CM_ SG_ 2566698238 SwitchedOutput1 "State of Switched Output #1. Used to indicate the output state.00b = Output off01b = Output on10b = Reserved11b = Take no action…";
CM_ SG_ 2566698238 SwitchedOutput10 "State of Switched Output #10. Used to indicate the output state.00b = Output off01b = Output on10b = Reserved11b = Take no action…";
CM_ SG_ 2566698238 SwitchedOutput11 "State of Switched Output #11. Used to indicate the output state.00b = Output off01b = Output on10b = Reserved11b = Take no action…";
CM_ SG_ 2566698238 SwitchedOutput12 "State of Switched Output #12. Used to indicate the output state.00b = Output off01b = Output on10b = Reserved11b = Take no action…";
CM_ SG_ 2566698238 SwitchedOutput13 "State of Switched Output #13. Used to indicate the output state.00b = Output off01b = Output on10b = Reserved11b = Take no action…";
CM_ SG_ 2566698238 SwitchedOutput14 "State of Switched Output #14. Used to indicate the output state.00b = Output off01b = Output on10b = Reserved11b = Take no action…";
CM_ SG_ 2566698238 SwitchedOutput15 "State of Switched Output #15. Used to indicate the output state.00b = Output off01b = Output on10b = Reserved11b = Take no action…";
CM_ SG_ 2566698238 SwitchedOutput16 "State of Switched Output #16. Used to indicate the output state.00b = Output off01b = Output on10b = Reserved11b = Take no action…";
CM_ SG_ 2566698238 SwitchedOutput17 "State of Switched Output #17. Used to indicate the output state.00b = Output off01b = Output on10b = Reserved11b = Take no action…";
CM_ SG_ 2566698238 SwitchedOutput18 "State of Switched Output #18. Used to indicate the output state.00b = Output off01b = Output on10b = Reserved11b = Take no action…";
CM_ SG_ 2566698238 SwitchedOutput19 "State of Switched Output #19. Used to indicate the output state.00b = Output off01b = Output on10b = Reserved11b = Take no action…";
CM_ SG_ 2566698238 SwitchedOutput2 "State of Switched Output #2. Used to indicate the output state.00b = Output off01b = Output on10b = Reserved11b = Take no action…";
CM_ SG_ 2566698238 SwitchedOutput20 "State of Switched Output #20. Used to indicate the output state.00b = Output off01b = Output on10b = Reserved11b = Take no action…";
CM_ SG_ 2566698238 SwitchedOutput21 "State of Switched Output #21. Used to indicate the output state.00b = Output off01b = Output on10b = Reserved11b = Take no action…";
CM_ SG_ 2566698238 SwitchedOutput22 "State of Switched Output #22. Used to indicate the output state.00b = Output off01b = Output on10b = Reserved11b = Take no action…";
CM_ SG_ 2566698238 SwitchedOutput23 "State of Switched Output #23. Used to indicate the output state.00b = Output off01b = Output on10b = Reserved11b = Take no action…";
CM_ SG_ 2566698238 SwitchedOutput24 "State of Switched Output #24. Used to indicate the output state.00b = Output off01b = Output on10b = Reserved11b = Take no action…";
CM_ SG_ 2566698238 SwitchedOutput25 "State of Switched Output #25. Used to indicate the output state.00b = Output off01b = Output on10b = Reserved11b = Take no action…";
CM_ SG_ 2566698238 SwitchedOutput26 "State of Switched Output #26. Used to indicate the output state.00b = Output off01b = Output on10b = Reserved11b = Take no action…";
CM_ SG_ 2566698238 SwitchedOutput27 "State of Switched Output #27. Used to indicate the output state.00b = Output off01b = Output on10b = Reserved11b = Take no action…";
CM_ SG_ 2566698238 SwitchedOutput28 "State of Switched Output #28. Used to indicate the output state.00b = Output off01b = Output on10b = Reserved11b = Take no action…";
CM_ SG_ 2566698238 SwitchedOutput29 "State of Switched Output #29. Used to indicate the output state.00b = Output off01b = Output on10b = Reserved11b = Take no action…";
CM_ SG_ 2566698238 SwitchedOutput3 "State of Switched Output #3. Used to indicate the output state.00b = Output off01b = Output on10b = Reserved11b = Take no action…";
CM_ SG_ 2566698238 SwitchedOutput30 "State of Switched Output #30. Used to indicate the output state.00b = Output off01b = Output on10b = Reserved11b = Take no action…";
CM_ SG_ 2566698238 SwitchedOutput31 "State of Switched Output #31. Used to indicate the output state.00b = Output off01b = Output on10b = Reserved11b = Take no action…";
CM_ SG_ 2566698238 SwitchedOutput32 "State of Switched Output #32. Used to indicate the output state.00b = Output off01b = Output on10b = Reserved11b = Take no action…";
CM_ SG_ 2566698238 SwitchedOutput4 "State of Switched Output #4. Used to indicate the output state.00b = Output off01b = Output on10b = Reserved11b = Take no action…";
CM_ SG_ 2566698238 SwitchedOutput5 "State of Switched Output #5. Used to indicate the output state.00b = Output off01b = Output on10b = Reserved11b = Take no action…";
CM_ SG_ 2566698238 SwitchedOutput6 "State of Switched Output #6. Used to indicate the output state.00b = Output off01b = Output on10b = Reserved11b = Take no action…";
CM_ SG_ 2566698238 SwitchedOutput7 "State of Switched Output #7. Used to indicate the output state.00b = Output off01b = Output on10b = Reserved11b = Take no action…";
CM_ SG_ 2566698238 SwitchedOutput8 "State of Switched Output #8. Used to indicate the output state.00b = Output off01b = Output on10b = Reserved11b = Take no action…";
CM_ SG_ 2566698238 SwitchedOutput9 "State of Switched Output #9. Used to indicate the output state.00b = Output off01b = Output on10b = Reserved11b = Take no action…";
CM_ BO_ 2566698494 "Fused Power Output Status";
CM_ SG_ 2566698494 FusedOutput1 "State of Fused Output #1. Used to indicate the output state.00b = Output not powered01b = Output powered10b = Reserved11b = Take no action…";
CM_ SG_ 2566698494 FusedOutput10 "State of Fused Output #10. Used to indicate the output state.00b = Output not powered01b = Output powered10b = Reserved11b = Take no action…";
CM_ SG_ 2566698494 FusedOutput11 "State of Fused Output #11. Used to indicate the output state.00b = Output not powered01b = Output powered10b = Reserved11b = Take no action…";
CM_ SG_ 2566698494 FusedOutput12 "State of Fused Output #12. Used to indicate the output state.00b = Output not powered01b = Output powered10b = Reserved11b = Take no action…";
CM_ SG_ 2566698494 FusedOutput13 "State of Fused Output #13. Used to indicate the output state.00b = Output not powered01b = Output powered10b = Reserved11b = Take no action…";
CM_ SG_ 2566698494 FusedOutput14 "State of Fused Output #14. Used to indicate the output state.00b = Output not powered01b = Output powered10b = Reserved11b = Take no action…";
CM_ SG_ 2566698494 FusedOutput15 "State of Fused Output #15. Used to indicate the output state.00b = Output not powered01b = Output powered10b = Reserved11b = Take no action…";
CM_ SG_ 2566698494 FusedOutput16 "State of Fused Output #16. Used to indicate the output state.00b = Output not powered01b = Output powered10b = Reserved11b = Take no action…";
CM_ SG_ 2566698494 FusedOutput17 "State of Fused Output #17. Used to indicate the output state.00b = Output not powered01b = Output powered10b = Reserved11b = Take no action…";
CM_ SG_ 2566698494 FusedOutput18 "State of Fused Output #18. Used to indicate the output state.00b = Output not powered01b = Output powered10b = Reserved11b = Take no action…";
CM_ SG_ 2566698494 FusedOutput19 "State of Fused Output #19. Used to indicate the output state.00b = Output not powered01b = Output powered10b = Reserved11b = Take no action…";
CM_ SG_ 2566698494 FusedOutput2 "State of Fused Output #2. Used to indicate the output state.00b = Output not powered01b = Output powered10b = Reserved11b = Take no action…";
CM_ SG_ 2566698494 FusedOutput20 "State of Fused Output #20. Used to indicate the output state.00b = Output not powered01b = Output powered10b = Reserved11b = Take no action…";
CM_ SG_ 2566698494 FusedOutput21 "State of Fused Output #21. Used to indicate the output state.00b = Output not powered01b = Output powered10b = Reserved11b = Take no action…";
CM_ SG_ 2566698494 FusedOutput22 "State of Fused Output #22. Used to indicate the output state.00b = Output not powered01b = Output powered10b = Reserved11b = Take no action…";
CM_ SG_ 2566698494 FusedOutput23 "State of Fused Output #23. Used to indicate the output state.00b = Output not powered01b = Output powered10b = Reserved11b = Take no action…";
CM_ SG_ 2566698494 FusedOutput24 "State of Fused Output #24. Used to indicate the output state.00b = Output not powered01b = Output powered10b = Reserved11b = Take no action…";
CM_ SG_ 2566698494 FusedOutput25 "State of Fused Output #25. Used to indicate the output state.00b = Output not powered01b = Output powered10b = Reserved11b = Take no action…";
CM_ SG_ 2566698494 FusedOutput26 "State of Fused Output #26. Used to indicate the output state.00b = Output not powered01b = Output powered10b = Reserved11b = Take no action…";
CM_ SG_ 2566698494 FusedOutput27 "State of Fused Output #27. Used to indicate the output state.00b = Output not powered01b = Output powered10b = Reserved11b = Take no action…";
CM_ SG_ 2566698494 FusedOutput28 "State of Fused Output #28. Used to indicate the output state.00b = Output not powered01b = Output powered10b = Reserved11b = Take no action…";
CM_ SG_ 2566698494 FusedOutput29 "State of Fused Output #29. Used to indicate the output state.00b = Output not powered01b = Output powered10b = Reserved11b = Take no action…";
CM_ SG_ 2566698494 FusedOutput3 "State of Fused Output #3. Used to indicate the output state.00b = Output not powered01b = Output powered10b = Reserved11b = Take no action…";
CM_ SG_ 2566698494 FusedOutput30 "State of Fused Output #30. Used to indicate the output state.00b = Output not powered01b = Output powered10b = Reserved11b = Take no action…";
CM_ SG_ 2566698494 FusedOutput31 "State of Fused Output #31. Used to indicate the output state.00b = Output not powered01b = Output powered10b = Reserved11b = Take no action…";
CM_ SG_ 2566698494 FusedOutput32 "State of Fused Output #32. Used to indicate the output state.00b = Output not powered01b = Output powered10b = Reserved11b = Take no action…";
CM_ SG_ 2566698494 FusedOutput4 "State of Fused Output #4. Used to indicate the output state.00b = Output not powered01b = Output powered10b = Reserved11b = Take no action…";
CM_ SG_ 2566698494 FusedOutput5 "State of Fused Output #5. Used to indicate the output state.00b = Output not powered01b = Output powered10b = Reserved11b = Take no action…";
CM_ SG_ 2566698494 FusedOutput6 "State of Fused Output #6. Used to indicate the output state.00b = Output not powered01b = Output powered10b = Reserved11b = Take no action…";
CM_ SG_ 2566698494 FusedOutput7 "State of Fused Output #7. Used to indicate the output state.00b = Output not powered01b = Output powered10b = Reserved11b = Take no action…";
CM_ SG_ 2566698494 FusedOutput8 "State of Fused Output #8. Used to indicate the output state.00b = Output not powered01b = Output powered10b = Reserved11b = Take no action…";
CM_ SG_ 2566698494 FusedOutput9 "State of Fused Output #9. Used to indicate the output state.00b = Output not powered01b = Output powered10b = Reserved11b = Take no action…";
CM_ BO_ 2566698750 "Vehicle Electrical Power 5";
CM_ SG_ 2566698750 SLIBatteryPackCapacity "Original or rated total reserve capacity of the battery pack used for starting the engine, for lighting, and for ignition (SLI).This parameter shall be used to …";
CM_ SG_ 2566698750 SLIBatteryPackHealth "Capacity of the battery pack relative to its original specification for the battery pack used for starting the engine, for lighting, and for ignition (SLI). 0% …";
CM_ SG_ 2566698750 SLIBatteryPackStateofCharge "Indicates the remaining charge of the battery pack used for starting the engine, for lighting, and for ignition (SLI). 0% means no charge remaining, 100% means …";
CM_ SG_ 2566698750 SLICrnkngPrdtdMnmmBttrVltg "Prediction of the minimum battery voltage used for starting the engine, for lighting, and for ignition (SLI) during a crank event, under present battery conditi…";
CM_ BO_ 2566699006 "Hybrid System Status 2";
CM_ SG_ 2566699006 HrdBttrPkRmnngChrg "Indicates the hybrid battery pack remaining charge. 0% means no charge remaining, 100% means full charge remaining.…";
CM_ SG_ 2566699006 HrdSstmEngnStpStrtRmnngPrntg "Indicates the remaining percentage of engine stop-start operation allowed by the hybrid system.The calculation of the percentage is manufacturer specific.  It i…";
CM_ SG_ 2566699006 HrdPrplsnMdMxmmSpdSttng "The maximum speed setting as requested using Hybrid Propulsion Mode Requested Maximum Speed (SPN 9706).A value of FBh indicates that the sender supports this pa…";
CM_ SG_ 2566699006 HrdPrplsnMdRmnngDstn "While in a Hybrid Propulsion Mode (see SPN 7889) other than Mode 1 - Stored Energy Source Sustaining, this reports a count down of the remaining distance until …";
CM_ BO_ 2566699262 "Aftertreatment 2 Service 2";
CM_ SG_ 2566699262 Atttt2DsPttFtTtNxtAtvRt "Indicates the time to the next active regeneration event of diesel particulate filter 2.…";
CM_ SG_ 2566699262 Atttt2SCRSstTSLstSstCEvt "Indicates the time since the last cleaning event of the SCR system in bank 2.…";
CM_ BO_ 2566699518 "Aftertreatment 1 Service 2";
CM_ SG_ 2566699518 Atttt1DsPttFtTtNxtAtvRt "Indicates the time to the next active regeneration event of diesel particulate filter 1.…";
CM_ SG_ 2566699518 Atttt1SCRSstTSLstSstCEvt "Indicates the time since the last cleaning event of the SCR system in bank 1.…";
CM_ BO_ 2566699774 "Aftertreatment 2 SCR Electronic Control Module Information";
CM_ SG_ 2566699774 Atttt2DsExstFdCtMd1PwSpp1 "State signal which indicates when the DEF control module 1 power supply of aftertreatment 2 is being driven. On means the ECU is powering the aftertreatment 2 D…";
CM_ SG_ 2566699774 Atttt2DsExstFdCtMd1PwSpp2 "State signal which indicates when the DEF control module 1 power supply 2 of aftertreatment 2 is being driven. On means the ECU is powering the aftertreatment 2…";
CM_ SG_ 2566699774 Atttt2DsExstFdCtMd1RCt "State signal which indicates when the DEF control module 1 relay of aftertreatment 2 is being energized. On means the ECU is powering the Aftertreatment 2 DEF d…";
CM_ SG_ 2566699774 Atttt2DsExstFdCtMd2PwSpp1 "State signal which indicates when the DEF control module 2 power supply of aftertreatment 2 is being driven. On means the ECU is powering the aftertreatment 2 D…";
CM_ SG_ 2566699774 Atttt2DsExstFdCtMd2PwSpp2 "State signal which indicates when the DEF control module 2 power supply 2 of aftertreatment 2 is being driven. On means the ECU is powering the aftertreatment 2…";
CM_ SG_ 2566699774 Atttt2DsExstFdCtMd2RCt "State signal which indicates when the DEF control module 2 relay of aftertreatment 2 is being energized. On means the ECU is powering the Aftertreatment 2 DEF d…";
CM_ SG_ 2566699774 Atttt2DsExstFdCtMdCtB "The status of the circuit breaker that is used to power the Diesel Exhaust Fluid control module.00b = Off01b = On10b = Error11b = Not available…";
CM_ BO_ 2566700030 "Aftertreatment 1 SCR Electronic Control Module Information";
CM_ SG_ 2566700030 Atttt1DsExstFdCtMd1PwSpp1 "State signal which indicates when the DEF control module power supply of aftertreatment 1 is being driven. On means the ECU is powering the aftertreatment 1 DEF…";
CM_ SG_ 2566700030 Atttt1DsExstFdCtMd1PwSpp2 "State signal which indicates when the DEF control module 1 power supply 2 of aftertreatment 1 is being driven. On means the ECU is powering the aftertreatment 1…";
CM_ SG_ 2566700030 Atttt1DsExstFdCtMd1RCt "State signal which indicates when the DEF control module relay of aftertreatment 1 is being energized. On means the ECU is powering the Aftertreatment 1 DEF dos…";
CM_ SG_ 2566700030 Atttt1DsExstFdCtMd2PwSpp1 "State signal which indicates when the DEF control module 2 power supply of aftertreatment 1 is being driven. On means the ECU is powering the aftertreatment 1 D…";
CM_ SG_ 2566700030 Atttt1DsExstFdCtMd2PwSpp2 "State signal which indicates when the DEF control module 2 power supply 2 of aftertreatment 1 is being driven. On means the ECU is powering the aftertreatment 1…";
CM_ SG_ 2566700030 Atttt1DsExstFdCtMd2RCt "State signal which indicates when the DEF control module 2 relay of aftertreatment 1 is being energized. On means the ECU is powering the Aftertreatment 1 DEF d…";
CM_ SG_ 2566700030 Atttt1DsExstFdCtMdCtB "The status of the circuit breaker that is used to power the diesel exhaust control module.00b = off01b = on10b = error11b = not available…";
CM_ BO_ 2566700286 "Aftertreatment 2 SCR Service Information 2";
CM_ SG_ 2566700286 Aftrtrtmnt2TtlDslExhstFldUsd "Total amount of DEF used by aftertreatment device 2 over the lifetime of the device.…";
CM_ BO_ 2566700542 "Aftertreatment 1 SCR Service Information 2";
CM_ SG_ 2566700542 Aftrtrtmnt1TtlDslExhstFldUsd "Total amount of DEF used by aftertreatment device 1 over the lifetime of the device.…";
CM_ SG_ 2566700542 AftrtrtmntTrpDslExhstFld "DEF consumed during all or part of a journey.…";
CM_ BO_ 2566701566 "Transmission Fluids 3";
CM_ SG_ 2566701566 TransmissionClutch2Pressure "Gage pressure of hydraulic actuation fluid for a second transmission clutch. In dual input clutch applications, this refers to the second input clutch.…";
CM_ SG_ 2566701566 TrnsmssnOlTrnsmssnClrOtltTmprtr "Temperature of transmission lubricant after it exits from the transmission cooler.…";
CM_ BO_ 2566701822 "Hybrid System Status 1";
CM_ SG_ 2566701822 ExtrnlEnrgSrCnntnStts "External Energy Source Connection Status provides feedback to the External Energy Source Connection Demand (SPN 7890).  This parameter allows for status of two …";
CM_ SG_ 2566701822 HrdPrplsnMdTrnstnStts "Hybrid Propulsion Mode Transition Status is sent by the Hybrid System controller to indicate the reason for a mode transition occurring or being denied.  This p…";
CM_ SG_ 2566701822 HrdSstmEltrAltrntrIndtr "Signal from the hybrid system indicating that the electric alternator is failed or needs servicing.  The alternator Indicator (e.g. dash lamp) is to be activate…";
CM_ SG_ 2566701822 HrdSstmHghVltgExpsrIndtr "This signal indicates the condition and state of the the hybrid system or electric vehicle system high voltage exposure detection system (e.g. High Voltage Inte…";
CM_ SG_ 2566701822 HrdSstmIntlztnIndtr "Signal indicating when the hybrid system or electric vehicle system is initialized and ready to start the engine or other power source (e.g. fuel cell). The int…";
CM_ SG_ 2566701822 HrdSstmMtrOvrspdAdlAlrm "Signal from the hybrid system indicating that the overspeed audible alarm should be activated.00b = Motor Overspeed Audible Alarm is off01b = Motor Overspeed Au…";
CM_ SG_ 2566701822 HrdSstmMtrOvrspdIndtr "Signal from the hybrid system indicating that the hybrid system motor is exceeding maximum speed limit.00b = Hybrid System Motor Overspeed Indicator is off01b =…";
CM_ SG_ 2566701822 HrdSstmPrplsnDslStts "Indicates if the hybrid system is in a state where propulsion is not available. This may be due to Hybrid System Propulsion Disable Request (SPN 7558), Hybrid S…";
CM_ SG_ 2566701822 HrdSstmRgnrtvBrkngIndtr "Signal from the hybrid system indicating when regenerative braking is active.00b = Regenerative braking is inactive, but not disabled01b = Regenerative braking …";
CM_ SG_ 2566701822 HybridPropulsionModeStatus "Hybrid Propulsion Mode Status is the current Hybrid System Controller propulsion mode.  This parameter would typically echo the Hybrid Propulsion Mode Request (…";
CM_ SG_ 2566701822 HybridSystemEngineAssistStatus "Provides the engine an indication of when the hybrid system is not mechanically assisting rotation (i.e. not motoring) the engine. When this parameter is in sta…";
CM_ SG_ 2566701822 HybridSystemOBDRelatedDTCStatus "Signal from hybrid system indicating the status of OBD related DTCs00b = Hybrid System does not have an active OBD related DTC01b = Hybrid System has an active …";
CM_ SG_ 2566701822 HybridSystemOverheatIndicator "Signal from a hybrid system indicating that at least one of its monitored temperatures is above normal acceptable limits, and as a result, hybrid system operati…";
CM_ SG_ 2566701822 HybridSystemServiceIndicator "Signal from the hybrid system indicating that the hybrid system or one of its components requires servicing (e.g. oil change, coolant change).00b = Hybrid Servi…";
CM_ SG_ 2566701822 HybridSystemStopIndicator "Signal from a hybrid system indicating that some aspect of its operation is not functioning correctly, and as a result, the vehicle must be stopped. The indicat…";
CM_ SG_ 2566701822 HybridSystemWarningIndicator "Signal from a hybrid system indicating that some aspect of its operation is not functioning correctly, and as a result, hybrid system operation may be altered o…";
CM_ SG_ 2566701822 PropulsionSystemActive "Indicates when the hybrid system or electric vehicle system is ready to provide or is actively providing propulsion as defined in ARB regulation 13CCR1971.1, wh…";
CM_ SG_ 2566701822 StoredEnergySourceLevel "Stored Energy Source Level indicates the current operating stored energy source capacity.In a Diesel-Electric Hybrid, this is the current percentage of the HVES…";
CM_ SG_ 2566701822 StrdEnrgSrInrsngMdAllwd "Stored Energy Source Increasing Mode Allowed is sent by the Hybrid System controller to indicate when the Stored Energy Source Increasing Mode is available for …";
CM_ SG_ 2566701822 StrdEnrgSrOnlMdAllwd "Stored Energy Source Only Mode Allowed is sent by the Hybrid System controller to indicate when Stored Energy Source Only Mode is available for use and/or allow…";
CM_ BO_ 2566702078 "Fuel Information 4 (Gaseous)";
CM_ SG_ 2566702078 SupplyGasMethanePercentage "The percentage of methane in the gas supplied to the engine.…";
CM_ BO_ 2566702334 "Aftertreatment 2 SCR Exhaust Gas Temperature 2";
CM_ SG_ 2566702334 Aftrtrtmnt2SCRIntrmdtTmprtr "Temperature of engine combustion byproducts at an intermediate point in the SCR component in exhaust bank 2.…";
CM_ SG_ 2566702334 Atttt2SCRItdtTptPFMI "Used to identify the applicable J1939-73 FMI detected in the aftertreatment SCR intermediate temperature sensor by the manufacturer’s sensor control software in…";
CM_ BO_ 2566702590 "Aftertreatment 1 SCR Exhaust Gas Temperature 2";
CM_ SG_ 2566702590 Aftrtrtmnt1SCRIntrmdtTmprtr "Temperature of engine combustion byproducts at an intermediate point in the SCR component in exhaust bank 1.…";
CM_ SG_ 2566702590 Atttt1SCRItdtTptPFMI "Used to identify the applicable J1939-73 FMI detected in the aftertreatment SCR intermediate temperature sensor by the manufacturer’s sensor control software in…";
CM_ BO_ 2566703358 "Electronic Engine Controller 13";
CM_ SG_ 2566703358 EngineDualFuelMode "Actual dual fuel mode, off or on.00b = Actual dual fuel mode off01b = Actual dual fuel mode on10b = Reserved11b = Not available…";
CM_ SG_ 2566703358 EngineFuelingInhibitAllowed "This parameter is broadcast by the engine control system, and indicates to other devices on the network whether or not it will respond to requests to inhibit en…";
CM_ SG_ 2566703358 EngnFlngDsrdRqstCnt "A signal issued by the engine control system indicating the number of devices from which the engine control system has received a fueling desired request. Reque…";
CM_ SG_ 2566703358 EngnFlngInhtPrvntdRsn "If Engine Fueling Inhibit Allowed (SPN 5795) indicates that the engine will inhibit fueling, then this parameter and Engine Fueling Inhibit Prevented Reason Ext…";
CM_ SG_ 2566703358 EngnFlngInhtPrvntdRsnExtnsn "If Engine Fueling Inhibit Allowed (SPN 5795) indicates that the engine will inhibit fueling, then this parameter indicate the reason.  If more than one reason e…";
CM_ SG_ 2566703358 EngnFlngInhtRqstCnt "A signal issued by the engine control system indicating the number of devices from which the engine control system has received a fueling not desired request. R…";
CM_ SG_ 2566703358 EngnGsSstttnFlPrntg "Percentage of Gaseous fuel used. 0% means no Gaseous fuel used and 100% means completely gaseous fuel is used.Gas substitution is the process for a dual fuel en…";
CM_ SG_ 2566703358 EngnPrttnDrtOvrrdStts "Status of overriding an engine protection derate.This is to temporarily override an engine protection derate due to coolant temperature, oil pressure etc… This …";
CM_ SG_ 2566703358 FeedbackEngineFuelingState "This parameter provides feedback to the network that SPN 5793 Desired Engine Fueling State was honored. SPN 5795 Engine Fueling Inhibit Allowed indicates the en…";
CM_ SG_ 2566703358 SrAddrssfCntrllngDvfrFlngStt "The J1939 source address of the device currently controlling the fueling state via SPN 5793.254 (FEh) is used to indicate that the Source Address of Controlling…";
CM_ BO_ 2566703614 "Engine Fuel/Throttle Valve Information 2";
CM_ SG_ 2566703614 EngineFuelValve1Temperature "Temperature of the Engine Fuel Valve 1 drive circuitry. Temperature excursions may affect the torque output.…";
CM_ SG_ 2566703614 EngineFuelValve2Temperature "Temperature of the Engine Fuel Valve 2 drive circuitry. Temperature excursions may affect the torque output.…";
CM_ SG_ 2566703614 EngineThrottleValve1Position2 "The position of the valve used to regulate the supply of a fluid, usually air or fuel/air mixture, to an engine. This position is measured by a second sensor.…";
CM_ SG_ 2566703614 EngineThrottleValve1Temperature "Temperature of the engine throttle valve 1 drive circuitry (SPN 51).  Temperature excursions may affect the torque output.…";
CM_ SG_ 2566703614 EngineThrottleValve2Temperature "Temperature of the engine throttle valve 2 drive circuitry (SPN 3673).  Temperature excursions may affect the torque output.…";
CM_ SG_ 2566703614 EngnFlRkFlSpplTmprtr "Temperature of fuel in the engine fuel rack.…";
CM_ SG_ 2566703614 EngnTrhrgrWstgtAttr2Tmprtr "Temperature of the Engine Turbocharger Wastegate Actuator 2 drive circuitry.  Temperature excursions may affect the torque output.…";
CM_ BO_ 2566703870 "Engine Exhaust Gas Recirculation 2 Actuator";
CM_ SG_ 2566703870 EExstGsRt2Att1TptStts "Used to identify the status of the Engine Exhaust Gas Recirculation 2 Actuator 1 drive circuitry temperature.  Temperature excursions may affect the torque outp…";
CM_ SG_ 2566703870 EExstGsRt2Att2TptStts "Used to identify the status of the Engine Exhaust Gas Recirculation 2 Actuator 2 drive circuitry temperature.  Temperature excursions may affect the torque outp…";
CM_ SG_ 2566703870 EngnExhstGsRrltn2Attr1DsrdPstn "The requested position of the Engine Exhaust Gas Recirculation 2 Actuator 1 by the engine ECU, where 0% represents fully closed and 100% represents fully open.T…";
CM_ SG_ 2566703870 EngnExhstGsRrltn2Attr1OprtnStts "Used to identify the status of Exhaust Gas Recirculation 2 Actuator 10000b = Normal0001b = Alarm (fully operational but needs service)0010b = Alarm High Severit…";
CM_ SG_ 2566703870 EngnExhstGsRrltn2Attr1PrlmnrFMI "Used to identify the applicable J1939-73 FMI detected in the Engine Exhaust Gas Recirculation 2 Actuator 1 by the manufacturer’s software.  When there are multi…";
CM_ SG_ 2566703870 EngnExhstGsRrltn2Attr1Tmprtr "Temperature of the Engine Exhaust Gas Recirculation 2 Actuator 1 drive circuitry.  Temperature excursions may affect the torque output.…";
CM_ SG_ 2566703870 EngnExhstGsRrltn2Attr2DsrdPstn "The requested position of the Engine Exhaust Gas Recirculation 2 Actuator 2 by the engine ECU, where 0% represents fully closed and 100% represents fully open.T…";
CM_ SG_ 2566703870 EngnExhstGsRrltn2Attr2OprtnStts "Used to identify the status of Exhaust Gas Recirculation 2 Actuator 20000b = Normal0001b = Alarm (fully operational but needs service)0010b = Alarm High Severit…";
CM_ SG_ 2566703870 EngnExhstGsRrltn2Attr2PrlmnrFMI "Used to identify the applicable J1939-73 FMI detected in the Engine Exhaust Gas Recirculation 2 Actuator 2 by the manufacturer’s software. When there are multip…";
CM_ SG_ 2566703870 EngnExhstGsRrltn2Attr2Tmprtr "Temperature of the Engine Exhaust Gas Recirculation 2 Actuator 2 drive circuitry.  Temperature excursions may affect the torque output.…";
CM_ BO_ 2566704126 "Engine Exhaust Gas Recirculation 1 Actuator";
CM_ SG_ 2566704126 EExstGsRt1Att1TptStts "Used to identify the status of the Engine Exhaust Gas Recirculation 1 Actuator 1 drive circuitry temperature.  Temperature excursions may affect the torque outp…";
CM_ SG_ 2566704126 EExstGsRt1Att2TptStts "Used to identify the status of the Engine Exhaust Gas Recirculation 1 Actuator 2 drive circuitry temperature.  Temperature excursions may affect the torque outp…";
CM_ SG_ 2566704126 EngnExhstGsRrltn1Attr1DsrdPstn "The requested position of the Engine Exhaust Gas Recirculation 1 Actuator 1 by the engine ECU, where 0% represents fully closed and 100% represents fully open.T…";
CM_ SG_ 2566704126 EngnExhstGsRrltn1Attr1OprtnStts "Used to identify the status of Exhaust Gas Recirculation 1 Actuator 10000b = Normal0001b = Alarm (fully operational but needs service)0010b = Alarm High Severit…";
CM_ SG_ 2566704126 EngnExhstGsRrltn1Attr1PrlmnrFMI "Used to identify the applicable J1939-73 FMI detected in the Engine Exhaust Gas Recirculation 1 Actuator 1 by the manufacturer’s software.  When there are multi…";
CM_ SG_ 2566704126 EngnExhstGsRrltn1Attr1Tmprtr "Temperature of the Engine Exhaust Gas Recirculation 1 Actuator 1 drive circuitry.  Temperature excursions may affect the torque output.…";
CM_ SG_ 2566704126 EngnExhstGsRrltn1Attr2DsrdPstn "The requested position of the Engine Exhaust Gas Recirculation 1 Actuator 2 by the engine ECU, where 0% represents fully closed and 100% represents fully open.T…";
CM_ SG_ 2566704126 EngnExhstGsRrltn1Attr2OprtnStts "Used to identify the status of Exhaust Gas Recirculation 1 Actuator 20000b = Normal0001b = Alarm (fully operational but needs service)0010b = Alarm High Severit…";
CM_ SG_ 2566704126 EngnExhstGsRrltn1Attr2PrlmnrFMI "Used to identify the applicable J1939-73 FMI detected in the Engine Exhaust Gas Recirculation 1 Actuator 2 by the manufacturer’s software. When there are multip…";
CM_ SG_ 2566704126 EngnExhstGsRrltn1Attr2Tmprtr "Temperature of the Engine Exhaust Gas Recirculation 1 Actuator 2 drive circuitry.  Temperature excursions may affect the torque output.…";
CM_ BO_ 2566704382 "Electronic Engine Controller 12";
CM_ SG_ 2566704382 Aftrtrtmnt1Otlt1GsSnsrPwrSppl "State signal which indicates when the Aftertreatment 1 Outlet 1 Gas Sensor driver output is being driven. On means the ECU is powering the Aftertreatment 1 Outl…";
CM_ SG_ 2566704382 Aftrtrtmnt1Otlt2GsSnsrPwrSppl "State signal which indicates when the Aftertreatment 1 Outlet 2 Gas Sensor driver output is being driven.00b = Off01b = On: The ECU is powering the Aftertreatme…";
CM_ SG_ 2566704382 Aftrtrtmnt2Otlt1GsSnsrPwrSppl "State signal which indicates when the Aftertreatment 2 Outlet 1 Gas Sensor driver output is being driven.  On means the ECU is powering the Aftertreatment 2 Out…";
CM_ SG_ 2566704382 EngnExhst1GsSnsr1PwrSppl "State signal which indicates when the Engine Exhaust 1 Intake 1 Gas Sensor driver output is being driven.  On means the ECU is powering the Engine Exhaust 1 Int…";
CM_ SG_ 2566704382 EngnExhst2GsSnsr1PwrSppl "State signal which indicates when the Engine Exhaust 2 Intake 1 Gas Sensor driver output is being driven.  On means the ECU is powering the Engine Exhaust 2 Int…";
CM_ SG_ 2566704382 EngnExhst1GsSnsr2PwrSppl "State signal which indicates when the Engine Exhaust 1 Intake 2 Gas Sensor driver output is being driven.00b = Off01b = On: The ECU is powering the Engine Exhau…";
CM_ BO_ 2566705150 "NOx Sensor Self-Diagnosis Request";
CM_ SG_ 2566705150 Atttt1OttNOxSsSdssT "Signal to trigger the self-diagnosis of NOx sensor ATO1 (Aftertreatment Outlet Bank 1)0000b = Diagnostic mode disabled0001b = NOx Sensor ATO1 Self Diagnosis Req…";
CM_ SG_ 2566705150 Atttt2OttNOxSsSdssT "Signal to trigger the self-diagnosis of NOx sensor ATO2 (Aftertreatment Outlet Bank 2)0000b = Diagnostic mode disabled0001b = NOx Sensor ATO2 Self Diagnosis Req…";
CM_ SG_ 2566705150 EExst1ItNOxSsSdssT "Signal to trigger the self-diagnosis of NOx sensor EEB1h (Engine Exhaust Intake Bank 1).  This sensor is located at the intake of the aftertreatment system if a…";
CM_ SG_ 2566705150 EExst2ItNOxSsSdssT "Signal to trigger the self-diagnosis of NOx sensor EEB2h (Engine Exhaust Intake Bank 2).  This sensor is located at the intake of the aftertreatment system if a…";
CM_ BO_ 2566705406 "Engine Particulate Sensor Information";
CM_ SG_ 2566705406 Aftrtrtmnt1PrtltSnsr "The particulate sensor measures the mass concentration of particulate matter in the exhaust downstream of the DPF in exhaust bank 1.…";
CM_ SG_ 2566705406 Aftrtrtmnt1PrtltSnsrCrrnt "Raw aftertreatment 1 PM sensor electrical current reading.…";
CM_ SG_ 2566705406 Aftrtrtmnt2PrtltSnsr "The particulate sensor measures the mass concentration of particulate matter in the exhaust downstream of the DPF in exhaust bank 2.…";
CM_ BO_ 2566706686 "Aftertreatment 1 Diesel Exhaust Fluid Pump 1 Information";
CM_ SG_ 2566706686 Aftrtrtmnt1DslExhstFldPmpHtr "Percentage of heating applied to the aftertreatment 1 diesel exhaust fluid pump heater. A value of 0% means no heating applied, a value of 100% means full heati…";
CM_ SG_ 2566706686 Atttt1DsExstFdDsUt1HtR "The status of the relay that controls Aftertreatment 1 diesel exhaust fluid dosing Unit 1 Heater.00b = Off01b = On10b = Error11b = Not available…";
CM_ SG_ 2566706686 Atttt1DsExstFdPp2MtSpd "Rotational speed of the motor driving the second pump for the diesel exhaust fluid used in aftertreatment system 1 (exhaust bank 1).…";
CM_ SG_ 2566706686 Atttt1DsExstFdPpPwSpp "State signal which indicates when the aftertreatment 1 Diesel Exhaust Fluid (DEF) pump power output is being driven.  On means the ECU is powering the aftertrea…";
CM_ BO_ 2566706942 "Aftertreatment 1 Diesel Particulate Filter 2 Soot 5";
CM_ SG_ 2566706942 Atttt1DsPttFt2StSsAssFq3 "The analysis frequency associated with the frequency 3 soot signal for the diesel particulate filter 2 soot sensor.  See SPN 5646.…";
CM_ SG_ 2566706942 Atttt1DsPttFt2StSsAssFq4 "The analysis frequency associated with the frequency 4 soot signal for the diesel particulate filter 2 soot sensor.  See SPN 5647.…";
CM_ SG_ 2566706942 Atttt1DsPttFt2StSsFq3StS "The soot signal attenuation measurement for analysis frequency 3 for the diesel particulate filter 2 soot sensor.  See SPN 5646.…";
CM_ SG_ 2566706942 Atttt1DsPttFt2StSsFq4StS "The soot signal attenuation measurement for analysis frequency 4 for the diesel particulate filter 2 soot sensor.  See SPN 5647.…";
CM_ BO_ 2566707198 "Aftertreatment 1 Diesel Particulate Filter 2 Soot 4";
CM_ SG_ 2566707198 Atttt1DsPttFt2StSsAssFq1 "The analysis frequency associated with the frequency 1 soot signal for the diesel particulate filter 2 soot sensor.  See SPN 5644.…";
CM_ SG_ 2566707198 Atttt1DsPttFt2StSsAssFq2 "The analysis frequency associated with the frequency 2 soot signal for the diesel particulate filter 2 soot sensor.  See SPN 5645.…";
CM_ SG_ 2566707198 Atttt1DsPttFt2StSsFq1StS "The soot signal attenuation measurement for analysis frequency 1 for the diesel particulate filter 2 soot sensor.  See SPN 5644.…";
CM_ SG_ 2566707198 Atttt1DsPttFt2StSsFq2StS "The soot signal attenuation measurement for analysis frequency 2 for the diesel particulate filter 2 soot sensor.  See SPN 5645.…";
CM_ BO_ 2566707454 "Aftertreatment 1 Diesel Particulate Filter 2 Soot 3";
CM_ SG_ 2566707454 Atttt1DsPttFt2StSsAssRqstFq1 "First requested analysis frequency for the diesel particulate filter 2 soot sensor.…";
CM_ SG_ 2566707454 Atttt1DsPttFt2StSsAssRqstFq2 "Second requested analysis frequency for the diesel particulate filter 2 soot sensor.…";
CM_ SG_ 2566707454 Atttt1DsPttFt2StSsAssRqstFq3 "Third requested analysis frequency for the diesel particulate filter 2 soot sensor.…";
CM_ SG_ 2566707454 Atttt1DsPttFt2StSsAssRqstFq4 "Fourth requested analysis frequency for the diesel particulate filter 2 soot sensor.…";
CM_ BO_ 2566707710 "Aftertreatment 1 Diesel Particulate Filter 1 Soot 5";
CM_ SG_ 2566707710 Atttt1DsPttFt1StSsAssFq3 "The analysis frequency associated with the frequency 3 soot signal for the diesel particulate filter 1 soot sensor.  See SPN 5634.…";
CM_ SG_ 2566707710 Atttt1DsPttFt1StSsAssFq4 "The analysis frequency associated with the frequency 4 soot signal for the diesel particulate filter 1 soot sensor.  See SPN 5635.…";
CM_ SG_ 2566707710 Atttt1DsPttFt1StSsFq3StS "The soot signal attenuation measurement for analysis frequency 3 for the diesel particulate filter 1 soot sensor.  See SPN 5634.…";
CM_ SG_ 2566707710 Atttt1DsPttFt1StSsFq4StS "The soot signal attenuation measurement for analysis frequency 4 for the diesel particulate filter 1 soot sensor.  See SPN 5635.…";
CM_ BO_ 2566707966 "Aftertreatment 1 Diesel Particulate Filter 1 Soot 4";
CM_ SG_ 2566707966 Atttt1DsPttFt1StSsAssFq1 "The analysis frequency associated with the frequency 1 soot signal for the diesel particulate filter 1 soot sensor.  See SPN 5632.…";
CM_ SG_ 2566707966 Atttt1DsPttFt1StSsAssFq2 "The analysis frequency associated with the frequency 2 soot signal for the diesel particulate filter 1 soot sensor.  See SPN 5633.…";
CM_ SG_ 2566707966 Atttt1DsPttFt1StSsFq1StS "The soot signal attenuation measurement for analysis frequency 1 for the diesel particulate filter 1 soot sensor.  See SPN 5632.…";
CM_ SG_ 2566707966 Atttt1DsPttFt1StSsFq2StS "The soot signal attenuation measurement for analysis frequency 2 for the diesel particulate filter 1 soot sensor.  See SPN 5633.…";
CM_ BO_ 2566708222 "Aftertreatment 1 Diesel Particulate Filter 1 Soot 3";
CM_ SG_ 2566708222 Atttt1DsPttFt1StSsAssRqstFq1 "First requested analysis frequency for the diesel particulate filter 1 soot sensor.…";
CM_ SG_ 2566708222 Atttt1DsPttFt1StSsAssRqstFq2 "Second requested analysis frequency for the diesel particulate filter 1 soot sensor.…";
CM_ SG_ 2566708222 Atttt1DsPttFt1StSsAssRqstFq3 "Third requested analysis frequency for the diesel particulate filter 1 soot sensor.…";
CM_ SG_ 2566708222 Atttt1DsPttFt1StSsAssRqstFq4 "Fourth requested analysis frequency for the diesel particulate filter 1 soot sensor.…";
CM_ BO_ 2566708478 "Cruise Control / Vehicle Speed 3";
CM_ SG_ 2566708478 AdptvCrsCntrlRdnssStts "This parameter is used to indicate an application's state of readiness for responding to commands from an adaptive cruise control system controller.00b = Off --…";
CM_ SG_ 2566708478 AEBSreadinessstate "Advanced emergency braking systems (AEBS) will limit the engine torque via TSC1 during warning and braking phases. Therefore the engine controller gives a feedb…";
CM_ SG_ 2566708478 CrsCntrlDrvrCnlltnStts "State signal which indicates that the cruise control is cancelled by driver action.  Driver actions could include switch off, brake pedal activation, clutch ped…";
CM_ SG_ 2566708478 CrsCntrlStSpdHghRsltn "Value of set (chosen) velocity of velocity control system. See SPN 86 for an alternate resolution.If an algorithm that can modify the cruise control set point e…";
CM_ SG_ 2566708478 CruiseControlSpeed "This parameter is the vehicle speed that the cruise control algorithm is currently using as its cruise control set point.Cruise Control Speed (SPN 7319) will in…";
CM_ SG_ 2566708478 PrdtvCrsCntrlStSpdOffstStts "This parameter indicates if the cruise control algorithm is currently adding the value in Predictive Cruise Control Set Speed Offset (SPN 7316) to the Cruise Co…";
CM_ SG_ 2566708478 SAddssCtDvDsCsCt "The source address of the SAE J1939 device that is currently sending the Cruise Control Disable Command (SPN 5603).If there are multiple devices sending Cruise …";
CM_ SG_ 2566708478 SAddssCtDvPsCsCt "The source address of the SAE J1939 device that is currently sending the Cruise Control Pause Command (SPN 5605).If there are multiple devices sending Cruise Co…";
CM_ BO_ 2566708734 "Aftertreatment 2 Air Control 3";
CM_ SG_ 2566708734 Aftrtrtmnt2SndrArAsltPrssr "Absolute pressure of the secondary air for aftertreatment 2. Secondary air is air provided to the exhaust system (per SAE J2403).For gage pressure, see SPN 3838…";
CM_ BO_ 2566708990 "Aftertreatment 1 Air Control 3";
CM_ SG_ 2566708990 Aftrtrtmnt1SndrArAsltPrssr "Absolute pressure of the secondary air for aftertreatment 1. Secondary air is air provided to the exhaust system (per SAE J2403).For gage pressure, see SPN 3837…";
CM_ SG_ 2566708990 OprtrIndmntOvrrdRnwlRqrd "Indicates the required operator inducement override renewal state.00b = Not Required01b = Required10b = Error11b = Not Available…";
CM_ BO_ 2566709246 "Engine Fluid Level/Pressure 12";
CM_ SG_ 2566709246 EFSppPpItAstPssExtddR "Absolute pressure of fuel at the fuel supply pump intake. See Figures SPN16_A & SPN16_B. See SPN 1381 for alternate resolution.Engine Fuel Supply Pump Intake Ab…";
CM_ SG_ 2566709246 EngineFuelFilterDegradation "The estimated percentage relative to the useful life of the engine fuel filter. This is not a calculation of the physical restriction of the filter.  0% is typi…";
CM_ SG_ 2566709246 EngineFuelReturnPressure "Used to read fuel (or gas) pressure passing through the return line.…";
CM_ SG_ 2566709246 EngnFlDlvrAsltPrssr "Absolute pressure of fuel in system as delivered from supply pump to the injection pump.  See also SPN 94 for Fuel Delivery Pressure (Gage).…";
CM_ SG_ 2566709246 EngnFltrdFlDlvrAsltPrssr "Absolute pressure of fuel in system as delivered from supply pump to the injection pump after the pressure side fuel filter.  See SPN 5579 for gage pressure of …";
CM_ SG_ 2566709246 EngnFltrdFlDlvrPrssr "Gage pressure of fuel in system as delivered from supply pump to the injection pump after the pressure side fuel filter.  See SPN 5580 for absolute pressure of …";
CM_ SG_ 2566709246 EngnThrttlVlv2DffrntlPrssr "The differential pressure between the intake and outlet of the throttle valve 2 (SPN 3673). The differential pressure is measured from the intake with respect t…";
CM_ BO_ 2566709502 "Diesel Particulate Filter Control 2";
CM_ SG_ 2566709502 Aftertreatment1FuelMassRate "Mass rate of total fuel being delivered to aftertreatment 1 for DPF regeneration.…";
CM_ SG_ 2566709502 Aftertreatment2FuelMassRate "Mass rate of total fuel being delivered to Atertreatment 2 for DPF regeneration.…";
CM_ SG_ 2566709502 Atttt1DsPttFtItTptStPt "Set point temperature for the particulate filter (DPF) regeneration at the intake to the DPF for Exhaust bank 1.…";
CM_ SG_ 2566709502 EngineUnburnedFuelPercentage "The unburned amount of diesel fuel coming out of the engine. This fuel increases the temperature while oxidated in the DOC. Therefore, this amount of fuel also …";
CM_ BO_ 2566709758 "Fuel Economy 2 (Liquid)";
CM_ SG_ 2566709758 EngineDieselFuelDemandRate "Amount of diesel fuel that would be consumed by an engine per unit of time if it were not substituting gaseous fuel.  This parameter is the sum of SPN 183 and t…";
CM_ SG_ 2566709758 EngineFuelRateHighResolution "Amount of fuel consumed by engine per unit of time.  NOTE - See SPN 183 for alternate resolution.…";
CM_ BO_ 2566710014 "Supplemental Fan Status";
CM_ SG_ 2566710014 SpplmntlFnCntrllrECUTmprtr "Measured temperature of Supplemental Fan Controller ECU.…";
CM_ SG_ 2566710014 SpplmntlFnCntrllrTmprtrStts "Internal Controller Temperature Status of Supplemental Fan.000b = High most severe 001b = High Least severe 010b = In Range 011b = Low Least severe 100b = Low M…";
CM_ SG_ 2566710014 SupplementalFanCurrent "Measured electrical current of supplemental fan drive.…";
CM_ SG_ 2566710014 SupplementalFanDirectionStatus "Rotational Direction of Supplemental Fan. Fan could be spinning forward or reverse.00b = Forward01b = Reverse10b = Error11b = Not available/Not installed…";
CM_ SG_ 2566710014 SupplementalFanDriveStatus "The drive status of the Supplemental Fan. This status parameter indicates the overall health of the fan drive. It will indicate that the fan is working OK or if…";
CM_ SG_ 2566710014 SupplementalFanEnableStatus "Enable/Disable Status of Supplemental Fan.00b = Disabled01b = Enabled10b = Error11b = Not available/Not installed…";
CM_ SG_ 2566710014 SupplementalFanPower "Estimated Power output of Supplemental Fan…";
CM_ SG_ 2566710014 SupplementalFanSpeed "Measured speed of supplemental fan.…";
CM_ SG_ 2566710014 SupplementalFanVelocityStatus "Status of the rotational velocity of Supplemental Fan. Used to indicate if the fan is spinning at the desired speed. If fan is not able to obtain the commanded …";
CM_ BO_ 2566710526 "Engine Fuel Properties";
CM_ SG_ 2566710526 EngineFuelDensity "Density of engine fuel…";
CM_ SG_ 2566710526 EngineFuelDynamicViscosity "Dynamic viscosity of engine fuel…";
CM_ SG_ 2566710526 EngnFl1Tmprtr1HghRsltn "Engine Fuel Temperature of the first fuel type. See also SPNs 174 or 3468 for alternate resolution.…";
CM_ SG_ 2566710526 EngnFlDltrtHghRsltn "Engine fuel relative dielectricity.…";
CM_ BO_ 2566710782 "Hydraulic Oil Properties";
CM_ SG_ 2566710782 HdrlOlRltvDltrtHghRsltn "Hydraulic oil relative dielectricity used to describe the hydraulic oil quality.  This hydraulic fluid is for the entire hydraulics system of a piece of equipme…";
CM_ SG_ 2566710782 HdrlOlTmprtrHghRsltn "Hydraulic Oil Temperature.  This hydraulic fluid is for the entire hydraulics system of a piece of equipment.…";
CM_ SG_ 2566710782 HydraulicOilDensity "Density of hydraulic oil.  This hydraulic fluid is for the entire hydraulics system of a piece of equipment.…";
CM_ SG_ 2566710782 HydraulicOilDynamicViscosity "Dynamic viscosity of hydraulic oil.  This hydraulic fluid is for the entire hydraulics system of a piece of equipment.…";
CM_ BO_ 2566711038 "Vehicle/Chassis Lubrication System 2";
CM_ SG_ 2566711038 LubricationCycleModeLockStatus "Reports status of the ability to change the lubrication cycle mode.  Locking the lubrication mode would prevent the changing of the lubrication cycle mode, perh…";
CM_ SG_ 2566711038 LubricationCycleModeStatus "Reports the current lubrication cycle mode of the lubrication system000b = Cycle mode # 1 (Lowest Lubrication Frequency)001b = Cycle mode # 2010b = Cycle mode #…";
CM_ SG_ 2566711038 LubricationOperationModeStatus "Reports the current operational mode status of the lubrication system.  Automatic is the normal operation mode of lubrication system. In this mode the operator …";
CM_ SG_ 2566711038 LubricationPumpEnableStatus "Reports the operational status of the lubrication system pump.  In the disabled state, the lubrication pump will not run a lubrication cycle.  In the enabled st…";
CM_ SG_ 2566711038 LubricationReservoirLevel "Reports the status of the lubrication system reservior level.  The lubrication reservoir stores the grease for the lubrication system. The lubrication pump draw…";
CM_ SG_ 2566711038 LubricationTimingCycleStatus "Reports the status of the lubrication activation clock.00b = Paused 01b = Enabled10b = Error 11b = Not available or not installed     Note:  In some vehicles or…";
CM_ BO_ 2566711294 "Engine Configuration 3";
CM_ SG_ 2566711294 EngnFrtnPrntTrqAtIdlPnt1 "The static portion of the friction torque at speed point 1 (SPN 188) of the engine torque map in the engine configuration message.  This parameter does not incl…";
CM_ SG_ 2566711294 EngnFrtnPrntTrqPnt2 "The static portion of the friction torque at speed point 2 (SPN 528) of the engine torque map in the engine configuration message.  This parameter does not incl…";
CM_ SG_ 2566711294 EngnFrtnPrntTrqPnt3 "The static portion of the friction torque at speed point 3 (SPN 529) of the engine torque map in the engine configuration message.  This parameter does not incl…";
CM_ SG_ 2566711294 EngnFrtnPrntTrqPnt4 "The static portion of the friction torque at speed point 4 (SPN 530) of the engine torque map in the engine configuration message.  This parameter does not incl…";
CM_ SG_ 2566711294 EngnFrtnPrntTrqPnt5 "The static portion of the friction torque at speed point 5 (SPN 531) of the engine torque map in the engine configuration message.  This parameter does not incl…";
CM_ SG_ 2566711294 EngnFrtnPrntTrqPnt6 "For engine configuration map modes 1 and 2, this is the static portion of the friction torque at speed point 6 (SPN 532) of the engine torque map.  For engine c…";
CM_ SG_ 2566711294 EngnFrtnPrntTrqPnt7 "The static portion of the friction torque at speed point 7 (SPN 533) of the engine torque map in the engine configuration message.  This parameter does not incl…";
CM_ BO_ 2566711550 "Intake Valve Actuation Control";
CM_ SG_ 2566711550 ItVvAttSstOPss1SdCt "Indicates the current command to the solenoid that controls the intake valve actuation system oil pressure 1 valve. This valve opens or closes a connection from…";
CM_ SG_ 2566711550 ItVvAttSstOPss2SdCt "Indicates the current command to the solenoid that controls the intake valve actuation system oil pressure 2 valve. This valve opens or closes a connection from…";
CM_ BO_ 2566711806 "Armrest Switch Matrix Commands";
CM_ SG_ 2566711806 Armrest1Switch1 "Status of the first switch located in armrest 1.00b = Off01b = On10b = Reserved11b = Don't care/take no action…";
CM_ SG_ 2566711806 Armrest1Switch2 "Status of the second switch located in armrest 1.00b = Off01b = On10b = Reserved11b = Don't care/take no action…";
CM_ SG_ 2566711806 Armrest2Switch1 "Status of the first switch located in armrest 2.00b = Off01b = On10b = Reserved11b = Don't care/take no action…";
CM_ SG_ 2566711806 Armrest2Switch2 "Status of the second switch located in armrest 2.00b = Off01b = On10b = Reserved11b = Don't care/take no action…";
CM_ BO_ 2566712318 "Aftertreatment 2 NOx Adsorber Information";
CM_ SG_ 2566712318 Aftrtrtmnt2NOxAdsrrDslftnStts "Indicates whether the NOx adsorber desulfation regeneration in the second aftertreatment system is active or inactive00b = Inactive01b = Active10b = Error indic…";
CM_ SG_ 2566712318 Aftrtrtmnt2NOxAdsrrRgnrtnStts "Indicates whether the NOx adsorber regeneration in the second aftertreatment system is active or inactive00b = Inactive01b = Active10b = Error indicator11b = No…";
CM_ BO_ 2566712574 "Aftertreatment 1 NOx Adsorber Information";
CM_ SG_ 2566712574 Aftrtrtmnt1NOxAdsrrDslftnStts "Indicates whether the NOx adsorber desulfation regeneration in the first aftertreatment system is active or inactive00b = Inactive01b = Active10b = Error indica…";
CM_ SG_ 2566712574 Aftrtrtmnt1NOxAdsrrRgnrtnStts "Indicates whether the NOx adsorber regeneration in the first aftertreatment system is active or inactive.00b = Inactive01b = Active10b = Error indicator11b = No…";
CM_ BO_ 2566712830 "Aftertreatment 2 Warm Up Diesel Oxidation Catalyst Information";
CM_ SG_ 2566712830 Atttt2WUpDsOxdtCtstItTpt "Temperature of engine combustion byproducts entering the warm up Diesel Oxidation Catalyst in exhaust bank 2.  This diesel parameter should be used with engines…";
CM_ SG_ 2566712830 Atttt2WUpDsOxdtCtstOttTpt "Temperature of engine combustion byproducts leaving the warm up Diesel Oxidation Catalyst in exhaust bank 2.  This diesel parameter should be used with engines …";
CM_ BO_ 2566713598 "Engine Fuel/Lube Systems 2";
CM_ SG_ 2566713598 EngnFlFltrStnSdDgrdtn "The estimated percentage relative to the useful life of the engine fuel filter on the suction side which is located betwee the fuel tank and the fuel supply pum…";
CM_ SG_ 2566713598 EngnFlFltrStnSdIntkAsltPrssr "Absolute pressure of fuel at the intake of the fuel filter (suction side) located between the fuel tank and the fuel supply pump.  See Figures SPN16_A & SPN16_B…";
CM_ SG_ 2566713598 FuelTankTransferPump "Operating state of the fuel tank transfer pump. The fuel tank transfer pump transfers fuel from the secondary fuel tank to the primary fuel tank.00b = Off01b = …";
CM_ SG_ 2566713598 FuelTankTransferPumpPressure "Gage pressure of the fuel in the system as delivered by the transfer pump.…";
CM_ SG_ 2566713598 EngineFuelPumpIntakeOilPressure "Oil pressure at the intake of the engine fuel pump.…";
CM_ BO_ 2566713854 "Engine Turbocharger Wastegate Actuator and Exhaust Back Pressure Regulator Information";
CM_ SG_ 2566713854 EExstPssRtCtOptStts "Used to identify the status of Engine Exhaust Pressure Regulator.0000b = Normal0001b = Alarm (fully operational but needs service)0010b = Alarm High Severity (f…";
CM_ SG_ 2566713854 EngnExhstBnk1PrssrRgltrPstn "The position of the Exhaust Pressure Regulator (EPR) in bank 1 expressed as a percentage of full travel.  One hundred percent means the regulator is fully close…";
CM_ SG_ 2566713854 EngnExhstPrssrAttr1DsrdPstn "The requested position of the Engine Exhaust Pressure Actuator 1 by the engine ECU, where 0% represents fully closed and 100% represents fully open.This is the …";
CM_ SG_ 2566713854 EngnExhstPrssrAttr1Tmprtr "Temperature of the Engine Exhaust Pressure Actuator 1 drive circuitry.  Temperature excursions may affect the torque output.…";
CM_ SG_ 2566713854 EngnExhstPrssrRgltrPrlmnrFMI "Used to identify the applicable J1939-73 FMI detected in the Engine Exhaust Pressure Regulator (EPR) by the manufacturers software.  When there are multiple fai…";
CM_ SG_ 2566713854 EngnExhstPrssrRgltrTmprtrStts "Used to identify the status of the Engine Exhaust Pressure Regulator (EPR) drive circuitry temperature. Temperature excursions may affect the torque output.000b…";
CM_ SG_ 2566713854 EngnTrhrgrWstgtAttr1OprtnStts "Used to identify the status of Engine Turbocharger Wastegate Actuator 1.0000b = Normal0001b = Alarm (fully operational but needs service)0010b = Alarm High Seve…";
CM_ SG_ 2566713854 EngnTrhrgrWstgtAttr1Tmprtr "Temperature of the Engine Turbocharger Wastegate Actuator 1 drive circuitry.  Temperature excursions may affect the torque output.…";
CM_ SG_ 2566713854 EngnTrhrgrWstgtAttr2OprtnStts "Used to identify the status of Engine Turbocharger Wastegate Actuator 2.0000b = Normal0001b = Alarm (fully operational but needs service)0010b = Alarm High Seve…";
CM_ SG_ 2566713854 EngnTrhrgrWstgtAttr2PrlmnrFMI "Used to identify the applicable J1939-73 FMI detected in the Engine Turbocharger Wastegate Actuator 2 by the manufacturers software. When there is multiple fail…";
CM_ SG_ 2566713854 EngnTrhrgrWstgtAttr2TmprtrStts "Used to identify the status of the Engine Turbocharger Wastegate Actuator 2 drive circuitry temperature.  Temperature excursions may affect the torque output.00…";
CM_ BO_ 2566714110 "Engine Fuel/Throttle Valve Information 1";
CM_ SG_ 2566714110 EngineFuelValve1OperationStatus "Used to identify the status of Engine Fuel Valve 1.0000b = Normal0001b = Alarm (fully operational but needs service)0010b = Alarm High Severity (functional but …";
CM_ SG_ 2566714110 EngineFuelValve1PreliminaryFMI "Used to identify the applicable J1939-73 FMI detected in the Engine Fuel Valve 1 by the manufacturers software. When there is multiple failures, the most severe…";
CM_ SG_ 2566714110 EngineFuelValve2OperationStatus "Used to identify the status of Engine Fuel Valve 2.0000b = Normal0001b = Alarm (fully operational but needs service)0010b = Alarm High Severity (functional but …";
CM_ SG_ 2566714110 EngineFuelValve2PreliminaryFMI "Used to identify the applicable J1939-73 FMI detected in the Engine Fuel Valve 2 by the manufacturers software.  When there is multiple failures, the most sever…";
CM_ SG_ 2566714110 EngnDsrdThrttlVlv1Pstn "The desired position of the Throttle valve 1 (SPN 51) that is regulating the fluid, usually air/fuel mixture to the engine as commanded by the Engine Control un…";
CM_ SG_ 2566714110 EngnDsrdThrttlVlv2Pstn "The desired position of the engine throttle valve 2 (SPN 3673) that is regulating the fluid, usually air/fuel mixture to the engine as commanded by the Engine C…";
CM_ SG_ 2566714110 EngnFlVlv1TmprtrStts "Used to identify the status of the Engine Fuel valve 1 drive circuitry temperature.  Temperature excursions may affect the torque output.000b = High Most severe…";
CM_ SG_ 2566714110 EngnFlVlv2TmprtrStts "Used to identify the status of the Engine Fuel valve 2 drive circuitry temperature.  Temperature excursions may affect the torque output.000b = High most severe…";
CM_ SG_ 2566714110 EngnThrttlVlv1OprtnStts "Used to identify the status of engine throttle valve 1 (SPN 51).0000b = Normal0001b = Alarm (fully operational but needs service)0010b = Alarm High Severity (fu…";
CM_ SG_ 2566714110 EngnThrttlVlv1PrlmnrFMI "Used to identify the applicable J1939-73 FMI detected in the engine throttle valve 1 (SPN 51) by the manufacturers software.  When there is multiple failures, t…";
CM_ SG_ 2566714110 EngnThrttlVlv1TmprtrStts "Used to identify the status of the engine throttle valve 1 (SPN 51) drive circuitry temperature.  Temperature excursions may affect the torque output.000b = Hig…";
CM_ SG_ 2566714110 EngnThrttlVlv2OprtnStts "Used to identify the status of engine throttle valve 2 (SPN 3673).0000b = Normal0001b = Alarm (fully operational but needs service)0010b = Alarm High Severity (…";
CM_ SG_ 2566714110 EngnThrttlVlv2PrlmnrFMI "Used to identify the applicable J1939-73 FMI detected in the engine throttle valve 2 (SPN 3673) by the manufacturers software.  When there is multiple failures,…";
CM_ SG_ 2566714110 EngnThrttlVlv2Tmprtrstts "Used to identify the status of the Engine throttle valve 2 (SPN 3673) drive circuitry temperature.  Temperature excursions may affect the torque output.000b = H…";
CM_ BO_ 2566714366 "Engine Turbocharger Compressor Bypass Information";
CM_ SG_ 2566714366 EngnTrhrgrCmprssrBpssAttr2Pstn "Measures the position of the turbocharger compressor bypass actuator 2, where 0% represents bypass fully closed and 100% represents bypass fully open. Typically…";
CM_ SG_ 2566714366 ETCpssBpssAtt1OptStts "Used to identify the status of Engine Turbocharger Compressor Bypass Actuator 1.0000b = Normal0001b = Alarm (fully operational but needs service)0010b = Alarm H…";
CM_ SG_ 2566714366 ETCpssBpssAtt1Tpt "Temperature of the Engine Turbocharger Compressor Bypass Actuator 1 drive circuitry.    Temperature excursions may affect the torque output.…";
CM_ SG_ 2566714366 ETCpssBpssAtt2DsdPst "The desired position of the Engine Turbocharger Compressor Bypass actuator 2 by the engine ECU, where 0% represents bypass fully closed and 100% represents bypa…";
CM_ SG_ 2566714366 ETCpssBpssAtt2OptStts "Used to identify the status of Engine Turbocharger Compressor Bypass Actuator 2.0000b = Normal0001b = Alarm (fully operational but needs service)0010b = Alarm H…";
CM_ SG_ 2566714366 ETCpssBpssAtt2Tpt "Temperature of the Engine Turbocharger Compressor Bypass Actuator 2 drive circuitry.    Temperature excursions may affect the torque output.…";
CM_ SG_ 2566714366 ETCpssBpssAtt2TptStts "Used to identify the status of the Engine Turbocharger Compresssor Bypass Actuator 2 drive circuitry temperature.  Temperature excursions may affect the torque …";
CM_ SG_ 2566714366 ETpssBpssAtt2PFMI "Used to identify the applicable J1939-73 FMI detected in the Engine Turbocharger Compressor Bypass Actuator 1 by the manufacturers software.  When there is mult…";
CM_ BO_ 2566714622 "Charge Air Cooler 2";
CM_ SG_ 2566714622 EngnChrgArClr2AmntArTmprtr "Temperature of the air surrounding charge air cooler 2.…";
CM_ SG_ 2566714622 EngnChrgArClr2Effn "Engine charge air cooler 2 (CAC2) is an indication of the CAC’s ability to reduce the temperature of the combustion air that is being routed through the CAC. 0%…";
CM_ SG_ 2566714622 EngnChrgArClr2IntkTmprtr "Temperature of the combustion air measured at the charge air cooler 2 Intake.…";
CM_ SG_ 2566714622 EngnChrgArClr2OtltTmprtr "Temperature of combustion air after it exits from the Charge Air Cooler 2 but before any mixing of recirculated exhaust gas.…";
CM_ BO_ 2566714878 "Charge Air Cooler 2 Precooler";
CM_ SG_ 2566714878 EngnChrgArClr2PrlrEffn "Engine charge air cooler 2 (CAC2) precooler efficiency is an indication of the precooler’s ability to reduce the temperature of the gas that is being routed thr…";
CM_ SG_ 2566714878 EngnChrgArClr2PrlrIntkTmprtr "Temperature of the combustion air measured at the charge air cooler 2 precooler Intake.…";
CM_ SG_ 2566714878 EngnChrgArClr2PrlrOtltTmprtr "Temperature of the combustion air measured at the charge air cooler 2 precooler outlet.…";
CM_ BO_ 2566715134 "Charge Air Cooler 1";
CM_ SG_ 2566715134 EngnChrgArClr1AmntArTmprtr "Temperature of the air surrounding charge air cooler 1.…";
CM_ SG_ 2566715134 EngnChrgArClr1Effn "Engine charge air cooler 1(CAC1) efficiency is an indication of the CAC’s ability to reduce the temperature of the combustion air that is being routed through t…";
CM_ SG_ 2566715134 EngnChrgArClr1IntkTmprtr "Temperature of the combustion air measured at the CAC 1 Intake.…";
CM_ BO_ 2566715390 "Charge Air Cooler 1 Precooler";
CM_ SG_ 2566715390 EngnChrgArClr1PrlrEffn "Engine charge air cooler 1 (CAC1) precooler efficiency is an indication of the precooler’s ability to reduce the temperature of the combustion air that is being…";
CM_ SG_ 2566715390 EngnChrgArClr1PrlrIntkTmprtr "Temperature of the combustion air measured at the charge air cooler 1 precooler intake.…";
CM_ SG_ 2566715390 EngnChrgArClr1PrlrOtltTmprtr "Temperature of the combustion air measured at the charge air cooler 1 precooler outlet.…";
CM_ BO_ 2566715646 "Diesel Particulate Filter 2 Soot 2";
CM_ SG_ 2566715646 Atttt2DsPttFtStSM "Minimum output signal level of the current soot measurement from diesel particulate filter 2 soot sensor.  This is a statistical value, not the minimum sensing …";
CM_ SG_ 2566715646 Atttt2DsPttFtStSMx "Maximum output signal level of the current soot measurement from diesel particulate filter 2 soot sensor.  This is a statistical value, not the maximum sensing …";
CM_ SG_ 2566715646 Atttt2DsPttFtStSStddDvt "Standard deviation of the soot measurement from diesel particulate filter 2 soot sensor.…";
CM_ BO_ 2566715902 "Diesel Particulate Filter 1 Soot 2";
CM_ SG_ 2566715902 Atttt1DsPttFtStSM "Minimum output signal level of the current soot measurement from diesel particulate filter 1 soot sensor.  This is a statistical value, not the minimum sensing …";
CM_ SG_ 2566715902 Atttt1DsPttFtStSMx "Maximum output signal level of the current soot measurement from diesel particulate filter 1 soot sensor.  This is a statistical value, not the maximum sensing …";
CM_ SG_ 2566715902 Atttt1DsPttFtStSStddDvt "Standard deviation of the soot measurement from diesel particulate filter 1 soot sensor.…";
CM_ BO_ 2566717438 "Engine Temperature 5";
CM_ SG_ 2566717438 EngnExhstGsRrltn2MxrIntkTmprtr "The temperature of the EGR gas entering the intake of EGR2 system mixer.…";
CM_ SG_ 2566717438 EngnExhstGsRrltn2Tmprtr "Temperature of Recirculated Exhaust Gas of EGR2…";
CM_ BO_ 2566717950 "Low Voltage Disconnect  Status";
CM_ SG_ 2566717950 LowVoltageDisconnectTemperature "Internal temperature of the LVD.…";
CM_ SG_ 2566717950 LwVltgDsnntCrrntOprtngMd "Current operating mode of the LVD.  The current mode is dependent on the state of the Manual Disconnect/Connect hardwired inputs and on the most-recent received…";
CM_ SG_ 2566717950 LwVltgDsnntMnlCnntStt "State of the Manual Connect hardwired input to the LVD.  Manual Connect is used to override the LVD's normal activlty and connect all of the LVD outputs.  Manua…";
CM_ SG_ 2566717950 LwVltgDsnntMnlDsnntStt "State of the Manual Disconnect hardwired input to the LVD.  Manual Disconnect is used to override the LVD's normal activlty and dicconnect all of the LVD output…";
CM_ SG_ 2566717950 LwVltgDsnntOtpt1Stt "State of the Output #1 from the LVD.  Output #1 controls an external load or relay.  This external load could be independent of the main output, and may apply t…";
CM_ SG_ 2566717950 LwVltgDsnntOtpt2Stt "State of the Output #2 from the LVD.  Output #2 controls an external load or relay.  This external load could be independent of the main output, and may apply t…";
CM_ SG_ 2566717950 LwVltgDsnntOtpt3Stt "State of the Output #3 from the LVD.  Output #3 controls an external load or relay.  This external load could be independent of the main output, and may apply t…";
CM_ SG_ 2566717950 LwVltgDsnntVtOtptStt "State of the Vout Output from the LVD.  Vout is the LVD's main internal, controllable, high-current output.  If the LVD supports prioritization, this circuit wi…";
CM_ BO_ 2566718718 "Direct Lamp Control Data 2";
CM_ SG_ 2566718718 HillHolderLampData "This message will be transmitted by the controller that is illuminating the lamps.00b = Lamp deactivated (Off)01b = Lamp activated (On)10b = Error11b = Not Avai…";
CM_ SG_ 2566718718 VehicleAirPressureLowLampData "This parameter provides measured data from the Vehicle Air Pressure Low Lamp.00b = Lamp deactivated (Off)01b = Lamp activated (On)10b = Error11b = Not available…";
CM_ SG_ 2566718718 VehicleBatteryChargingLampData "This parameter provides measured data from the Vehicle Battery Charging Lamp.00b = Lamp deactivated (Off)01b = Lamp activated (On)10b = Error11b = Not available…";
CM_ SG_ 2566718718 VehicleFuelLevelLowLampData "This parameter provides measured data from the Vehicle Fuel Level Low Lamp.00b = Lamp deactivated (Off)01b = Lamp activated (On)10b = Error11b = Not available…";
CM_ SG_ 2566718718 VhlBttrVltgLwLmpDt "This parameter provides measured data from the Vehicle Battery Voltage Low Lamp.00b = Lamp deactivated (Off)01b = Lamp activated (On)10b = Error11b = Not availa…";
CM_ SG_ 2566718718 VhlHVACRrltnLmpDt "This parameter provides measured data from the Vehicle HVAC Recirculation Lamp.00b = Lamp deactivated (Off)01b = Lamp activated (On)10b = Error11b = Not availab…";
CM_ BO_ 2566718974 "Direct Lamp Control Data 1";
CM_ SG_ 2566718974 CmprssnBrkEnlSwthIndtrLmpDt "This parameter provides measured data from the Compression Brake Enable Switch Indicator Lamp.00b = Lamp deactivated (Off)01b = Lamp activated (On)10b = Error11…";
CM_ SG_ 2566718974 EngineAmberWarningLampData "This parameter provides measured data from the Engine Amber Warning Lamp.00b = Lamp deactivated (Off)01b = Lamp activated (On)10b = Error11b = Not available…";
CM_ SG_ 2566718974 EngineBrakeActiveLampData "This parameter provides measured data from the Engine Brake Active Lamp.00b = Lamp deactivated (Off)01b = Lamp activated (On)10b = Error11b = Not available…";
CM_ SG_ 2566718974 EngineCoolantLevelLowLampData "This parameter provides measured data from the Engine Coolant Level Low Lamp.00b = Lamp deactivated (Off)01b = Lamp activated (On)10b = Error11b = Not available…";
CM_ SG_ 2566718974 EngineOilPressureLowLampData "This parameter provides measured data from the Engine Oil Pressure Low Lamp.00b = Lamp deactivated (Off)01b = Lamp activated (On)10b = Error11b = Not available…";
CM_ SG_ 2566718974 EngineProtectLampData "This parameter provides measured data from the Engine Protect Lamp.00b = Lamp deactivated (Off)01b = Lamp activated (On)10b = Error11b = Not available…";
CM_ SG_ 2566718974 EngineRedStopLampData "This parameter provides measured data from the Engine Red Stop Lamp.00b = Lamp deactivated (Off)01b = Lamp activated (On)10b = Error11b = Not available…";
CM_ SG_ 2566718974 EngineSpeedHighLampData "This parameter provides measured data from the Engine Speed High Warning Lamp.00b = Lamp Deactivated (Off)01b = Lamp Activated (On)10b = Error11b = Not availabl…";
CM_ SG_ 2566718974 EngineSpeedVeryHighLampData "This parameter provides measured data from the Engine Speed Very High Warning Lamp.00b = Lamp Deactivated (Off)01b = Lamp Activated (On)10b = Error11b = Not ava…";
CM_ SG_ 2566718974 EngineWaitToStartLampData "This parameter provides measured data from the Engine Wait To Start Lamp.  See SPN 1081 for the command.00b = Lamp deactived (off)01b = Lamp actived (on)10b = E…";
CM_ SG_ 2566718974 EngnArFltrRstrtnLmpDt "This parameter provides measured data from the Engine Air Filter Restriction Lamp.00b = Lamp deactivated (Off)01b = Lamp activated (On)10b = Error11b = Not avai…";
CM_ SG_ 2566718974 EngnClntTmprtrHghLmpDt "This parameter provides measured data from the Engine Coolant Temperature High Lamp.00b = Lamp deactivated (Off)01b = Lamp activated (On)10b = Error11b = Not av…";
CM_ SG_ 2566718974 EngnCntrlMdl1RdfrUsLmpDt "This parameter provides measured data from the Engine Control Module 1 Ready for Use Lamp.00b = Lamp deactivated (Off)01b = Lamp activated (On)10b = Error11b = …";
CM_ SG_ 2566718974 EngnCntrlMdl2RdfrUsLmpDt "This parameter provides measured data from the Engine Control Module 2 Ready for Use Lamp.00b = Lamp deactivated (Off)01b = Lamp activated (On)10b = Error11b = …";
CM_ SG_ 2566718974 EngnCntrlMdl3RdfrUsLmpDt "This parameter provides measured data from the Engine Control Module 3 Ready for Use Lamp.00b = Lamp deactivated (Off)01b = Lamp activated (On)10b = Error11b = …";
CM_ SG_ 2566718974 EngnFlFltrRstrtdLmpDt "This parameter provides measured data from the Engine Fuel Filter Restricted Lamp.00b = Lamp deactivated (Off)01b = Lamp activated (On)10b = Error11b = Not avai…";
CM_ SG_ 2566718974 EngnIdlMngmntAtvLmpDt "This parameter provides measured data from the Engine Idle Management Active Lamp.00b = Lamp deactivated (Off)01b = Lamp activated (On)10b = Error11b = Not avai…";
CM_ SG_ 2566718974 OBDMalfunctionIndicatorLampData "This parameter provides measured data from the OBD Malfunction Indicator Lamp.00b = Lamp deactivated (Off)01b = Lamp activated (On)10b = Error11b = Not availabl…";
CM_ SG_ 2566718974 VhlAlrtnRtLmtLmpDt "This parameter provides measured data from the Vehicle Acceleration Rate Limit Lamp.00b = Lamp deactivated (Off)01b = Lamp activated (On)10b = Error11b = Not av…";
CM_ SG_ 2566718974 EngnStpStrtAtmtStpAtvLmpDt "Provides measured data from the engine stop-start automatic stop active lamp.00b = Lamp deactivated (Off)01b = Lamp activated (On)10b = Error11b = Not available…";
CM_ SG_ 2566718974 EngnStpStrtAtmtStrtFldLmpDt "Provides measured data from the engine stop-start automatic start failed lamp.00b = Lamp deactivated (Off)01b = Lamp activated (On)10b = Error11b = Not availabl…";
CM_ SG_ 2566718974 EngineStopStartEnabledLampData "Provides measured data from the engine stop-start enabled lamp.00b = Lamp deactivated (Off)01b = Lamp activated (On)10b = Error11b = Not available…";
CM_ BO_ 2566719230 "Direct Lamp Control Command 2";
CM_ SG_ 2566719230 HillHolderLampCommand "Command signal directly controlling Hill Holder Lamp.00b = Lamp Off01b = Lamp On10b = Lamp Flash (1 Hz)11b = Not available…";
CM_ SG_ 2566719230 VehicleFuelLevelLowLampCommand "Command signal directly controlling the Vehicle Fuel Level Low Lamp.00b = Lamp Off01b = Lamp On10b = Reserved11b = Not available…";
CM_ SG_ 2566719230 VhlArPrssrLwLmpCmmnd "Command signal directly controlling the Vehicle Air Pressure Low Lamp.00b = Lamp Off01b = Lamp On10b = Reserved11b = Not available…";
CM_ SG_ 2566719230 VhlBttrChrgngLmpCmmnd "Command signal directly controlling the Vehicle Battery Charging Lamp.00b = Lamp Off01b = Lamp On10b = Reserved11b = Not available…";
CM_ SG_ 2566719230 VhlBttrVltgLwLmpCmmnd "Command signal directly controlling the Vehicle Battery Voltage Low Lamp.00b = Lamp Off01b = Lamp On10b = Reserved11b = Not available…";
CM_ SG_ 2566719230 VhlHVACRrltnLmpCmmnd "Command signal directly controlling the Vehicle HVAC Recirculation Lamp.00b = Lamp Off01b = Lamp On10b = Reserved11b = Not available…";
CM_ BO_ 2566719486 "Direct Lamp Control Command 1";
CM_ SG_ 2566719486 CmprssnBrkEnlSwthIndtrLmpCmmnd "Command signal directly controlling Compression Brake Enable Switch Indicator Lamp.  The compression brake switch indicator signals the status of the compressio…";
CM_ SG_ 2566719486 EngineAmberWarningLampCommand "Command signal directly controlling the Engine Amber Warning Lamp00b = Lamp Off01b = Lamp On10b = Reserved11b = Not availableNote:  SPN 624 should be used for r…";
CM_ SG_ 2566719486 EngineBrakeActiveLampCommand "Command signal directly controlling the Engine Brake Active Lamp. This is used for engine based retarders.00b = Lamp Off01b = Lamp On10b = Reserved11b = Not ava…";
CM_ SG_ 2566719486 EngineOilPressureLowLampCommand "Command signal directly controlling the Engine Oil Pressure Low Lamp00b = Lamp Off01b = Lamp On10b = Reserved11b = Not available…";
CM_ SG_ 2566719486 EngineProtectLampCommand "Command signal directly controlling the Engine Protect Lamp00b = Lamp Off01b = Lamp On10b = Reserved11b = Not availableNote:  SPN 987 should be used for reporti…";
CM_ SG_ 2566719486 EngineRedStopLampCommand "Command signal directly controlling the Engine Red Stop Lamp00b = Lamp Off01b = Lamp On10b = Reserved11b = Not availableNote:  SPN 623 should be used for report…";
CM_ SG_ 2566719486 EngineSpeedHighLampCommand "Command signal directly controlling the Engine Speed High Warning lamp.00b = Lamp Off01b = Lamp On10b = Reserved11b = Not available…";
CM_ SG_ 2566719486 EngineSpeedVeryHighLampCommand "Command signal directly controlling the Engine Speed Very High Warning lamp.00b = Lamp Off01b = Lamp On10b = Reserved11b = Not available…";
CM_ SG_ 2566719486 EngnArFltrRstrtnLmpCmmnd "Command signal directly controlling the Engine Air Filter Restriction Lamp.00b = Lamp Off01b = Lamp On10b = Reserved11b = Not available…";
CM_ SG_ 2566719486 EngnClntLvlLwLmpCmmnd "Command signal directly controlling the Engine Coolant Level Low Lamp00b = Lamp Off01b = Lamp On10b = Reserved11b = Not available…";
CM_ SG_ 2566719486 EngnClntTmprtrHghLmpCmmnd "Command signal directly controlling the Engine Coolant Temperature High Lamp00b = Lamp Off01b = Lamp On10b = Reserved11b = Not available…";
CM_ SG_ 2566719486 EngnCntrlMdl1RdfrUsLmpCmmnd "Command signal directly controlling the Engine Control Module 1 Ready for use Lamp. This lamp is used to indicate whether ECM 1 can control the operation of the…";
CM_ SG_ 2566719486 EngnCntrlMdl2RdfrUsLmpCmmnd "Command signal directly controlling the Engine Control Module 2 Ready for Use Lamp. This lamp is used to indicate whether ECM 2 can control the operation of the…";
CM_ SG_ 2566719486 EngnCntrlMdl3RdfrUsLmpCmmnd "Command signal directly controlling the Engine Control Module 3 Ready for Use Lamp. This lamp is used to indicate whether ECM 3 can control the operation of the…";
CM_ SG_ 2566719486 EngnFlFltrRstrtdLmpCmmnd "Command signal directly controlling the Engine Fuel Filter Restricted Lamp.00b = Lamp Off01b = Lamp On10b = Reserved11b = Not available…";
CM_ SG_ 2566719486 EngnIdlMngmntAtvLmpCmmnd "Command signal directly controlling the Engine Idle Management Active Lamp00b = Lamp Off01b = Lamp On10b = Reserved11b = Not availableNote:  SPN 1661 should be …";
CM_ SG_ 2566719486 EngnIdlMngmntPndngEvntLmpCmmnd "Command signal directly controlling the Engine Idle Management Pending Event Lamp.  An engine start-up or shutdown is considered an event.00b = Lamp Off01b = La…";
CM_ SG_ 2566719486 OBDMlfntnIndtrLmpCmmnd "Command signal directly controlling the OBD Malfunction Indicator Lamp00b = Lamp Off01b = Lamp On10b = Reserved11b = Not availableNote:  SPN 1213 should be used…";
CM_ SG_ 2566719486 VhlAlrtnRtLmtLmpCmmnd "Command signal directly controlling the Vehicle Acceleration Rate Limit Lamp.00b = Lamp Off01b = Lamp On10b = Reserved11b = Not availableNOTE: SPN 2979 is the o…";
CM_ SG_ 2566719486 EngnStpStrtAtmtStpAtvLmpCmmnd "Command signal directly controlling the engine stop-start automatic stop active lamp.00b = Lamp off01b = Lamp on10b = Reserved11b = Not availableNote: SPN 9680 …";
CM_ SG_ 2566719486 EngnStpStrtAtmtStrtFldLmpCmmnd "Command signal directly controlling the engine stop-start automatic start failed lamp.00b = Lamp off01b = Lamp on10b = Reserved11b = Not availableNote: SPN 9681…";
CM_ SG_ 2566719486 EngnStpStrtEnldLmpCmmnd "Command signal directly controlling the engine stop-start enabled lamp.00b = Lamp off01b = Lamp on10b = Reserved11b = Not availableNote: SPN 9682 should be used…";
CM_ BO_ 2566719998 "High Resolution Fuel Consumption (Liquid)";
CM_ SG_ 2566719998 EngineTripFuelHighResolution "Fuel consumed during all or part of a journey.   High resolution used for calculations and fleet management systems.  See SPN 182 for alternate resolution.…";
CM_ SG_ 2566719998 EngnTtlFlUsdHghRsltn "Accumulated amount of fuel used during vehicle operation.  High resolution used for calculations and fleet management systems.  See SPN 250 for alternate resolu…";
CM_ BO_ 2566722302 "Magnet Status Information 1";
CM_ SG_ 2566722302 GeneratorOverheatStatus "The Status of Generator being Overheated.00b = Not Overheat01b = Overheat10b = Error11b = Not Available…";
CM_ SG_ 2566722302 GensetEnableActiveStatus "Status of the Genset Enable Relay that enables or disables the Genset.00b = Not Enabled01b = Enabled10b = Error11b = Not Avaialble…";
CM_ SG_ 2566722302 GensetSoftstartActiveStatus "The Genset Softstart Active Status refers to the status of the genset softstart relay. The moment the Genset System is started, this relay is activated. As a re…";
CM_ SG_ 2566722302 GnrtrDtClExddStts "The status of the duty cycle of the generator usage, indicating if the generator has been on for too much time within a defined time window.  The duty cycle is …";
CM_ SG_ 2566722302 GnstSstmOtptVltgRngStts "Status of generator voltage in or out of desired operating range.00b = Out of Range 01b = In Range10b = Error11b = Not Available…";
CM_ SG_ 2566722302 GrappleMagnetSelectionSwitch "This is a switch that can be used to select either the Grapple or Magnet function of the material handler machine.00b = Grapple Selected01b = Magnet Selected10b…";
CM_ SG_ 2566722302 ReverseCurrentRangeSetting "The operator setting for the Reverse Current. The setting defines the maximum reverse current. The actual current limits are specific to the application.00000b …";
CM_ SG_ 2566722302 VoltageMonitorActiveStatus "Status of Voltage Monitor Relay. When it is activated, the Generator Voltage Monitor is connected to the generator output line so that the generator output volt…";
CM_ BO_ 2566722558 "Magnet System Configuration Information";
CM_ SG_ 2566722558 MagnetBoostTime "The duration of time after the activation of the magnet circuit that a relatively high current is sent to the magnet for material pick up operations. This time …";
CM_ SG_ 2566722558 MagnetRatedPower "The rated power that the magnet can accept during material holding operations.  Note that the magnet may experience more power over short intervals, such as dur…";
CM_ BO_ 2566722814 "Battery Charger 2";
CM_ SG_ 2566722814 BatteryCharger2OutputCurrent "Output current of the battery charger connected to the main battery. If positive, this parameter shows the charging current of the battery charger connected to …";
CM_ SG_ 2566722814 BatteryCharger2OutputVoltage "Output voltage measured on the battery terminals of the offline battery charger connected to the auxiliary battery.…";
CM_ SG_ 2566722814 BatteryCharger2PowerLineState "A state of the battery charger connection to the power line for the charger connected to the auxiliary battery.0 = Disconnected. The power line is disconnected …";
CM_ SG_ 2566722814 BatteryCharger2State "A state of the offline battery charger connected to the auxiliary battery. 0 = Idling. The power line or the battery is disconnected from the charger.1 = Chargi…";
CM_ BO_ 2566723070 "Battery Charger 1";
CM_ SG_ 2566723070 BatteryCharger1OutputCurrent "Output current of the battery charger connected to the main battery. If positive, this parameter shows the charging current of the battery charger connected to …";
CM_ SG_ 2566723070 BatteryCharger1OutputVoltage "Output voltage measured on the battery terminals of the battery charger connected to the main battery.…";
CM_ SG_ 2566723070 BatteryCharger1PowerLineState "A state of the battery charger connection to the power line for the charger connected to the main battery.0 = Disconnected. The power line is disconnected from …";
CM_ SG_ 2566723070 BatteryCharger1State "A state of the battery charger connected to the main battery.  0 = Idling. The power line or the battery is disconnected from the charger.1 = Charging the batte…";
CM_ BO_ 2566724350 "Aftertreatment 1 Warm Up Diesel Oxidation Catalyst Information";
CM_ SG_ 2566724350 Atttt1WUpDsOxdtCtstItTpt "This is the temperature measured at the intake of the warm up oxidation catalytic converter in exhaust bank 1.…";
CM_ SG_ 2566724350 Atttt1WUpDsOxdtCtstOttTpt "This is the temperature measured at the outlet of the warm up oxidation catalytic converter in exhaust bank 1.…";
CM_ BO_ 2566724606 "Diesel Particulate Filter 2 Soot";
CM_ SG_ 2566724606 Aftrtrtmnt2DslPrtltFltrMnStSgnl "Mean output signal level from diesel particulate filter 2 soot sensor.…";
CM_ SG_ 2566724606 Aftrtrtmnt2DslPrtltFltrStDnst "Soot density in diesel particulate filter 2.…";
CM_ SG_ 2566724606 Aftrtrtmnt2DslPrtltFltrStMss "Soot mass in diesel particulate filter 2.…";
CM_ SG_ 2566724606 Atttt2DsPttFtMdStS "Median output signal level from diesel particulate filter 2 soot sensor.…";
CM_ SG_ 2566724606 Atttt2DsPttFtStSsPFMI "Used to identify the applicable J1939-73 FMI detected in the soot sensor signal by the manufacturer’s sensor control software in diesel particulate filter 2.  I…";
CM_ SG_ 2566724606 DsPttFt2StSsECUItTpt "Internal temperature of the diesel particulate filter 2 soot sensor ECU.…";
CM_ BO_ 2566724862 "Diesel Particulate Filter 1 Soot";
CM_ SG_ 2566724862 Aftrtrtmnt1DslPrtltFltrMnStSgnl "Mean output signal level from diesel particulate filter 1 soot sensor.…";
CM_ SG_ 2566724862 Aftrtrtmnt1DslPrtltFltrStDnst "Soot density in diesel particulate filter 1.…";
CM_ SG_ 2566724862 Aftrtrtmnt1DslPrtltFltrStMss "Soot mass in diesel particulate filter 1.…";
CM_ SG_ 2566724862 Atttt1DsPttFtMdStS "Median output signal level from diesel particulate filter 1 soot sensor.…";
CM_ SG_ 2566724862 Atttt1DsPttFtStSsPFMI "Used to identify the applicable J1939-73 FMI detected in the soot sensor signal by the manufacturer’s sensor control software in diesel particulate filter 1. In…";
CM_ SG_ 2566724862 DsPttFt1StSsECUItTpt "Internal temperature of the diesel particulate filter 1 soot sensor ECU.…";
CM_ BO_ 2566725118 "Aftertreatment Differential Temperature 2 ";
CM_ SG_ 2566725118 Atttt1TWCtstDtTpt "The differential engine combustion byproducts gas temperature measured between the intake and outlet of the three way catalyst for exhaust bank 1.…";
CM_ SG_ 2566725118 Atttt2TWCtstDtTpt "The differential engine combustion byproducts gas temperature measured between the intake and outlet of the three way catalyst for exhaust bank 2.…";
CM_ BO_ 2566725374 "Aftertreatment Differential Temperature 1 ";
CM_ SG_ 2566725374 Atttt1GsOxdtCtstDtTpt "The differential engine combustion byproducts gas temperature measured between the intake and outlet of the gas oxidation catalyst for exhaust bank 1.  This par…";
CM_ SG_ 2566725374 Atttt2GsOxdtCtstDtTpt "The differential engine combustion byproducts gas temperature measured between the intake and outlet of the gas oxidation catalyst for exhaust bank 2.  This par…";
CM_ BO_ 2566725630 "Aftertreatment 2 Diesel Oxidation Catalyst 1";
CM_ SG_ 2566725630 Atttt2DsOxdtCtstDtPss "Exhaust differential pressure measured between the intake and exhaust of a diesel oxidation catalyst in exhaust bank 2.  This parameter should be used with engi…";
CM_ SG_ 2566725630 Atttt2DsOxdtCtstDtPssPFMI "Used to identify the applicable J1939-73 FMI detected in the diesel oxidation catalyst differential pressure sensor by the manufacturer’s sensor control softwar…";
CM_ SG_ 2566725630 Atttt2DsOxdtCtstItTpt "Temperature of engine combustion byproducts entering the diesel oxidation catalyst in exhaust bank 2.  This parameter should be used with engines fueled by dies…";
CM_ SG_ 2566725630 Atttt2DsOxdtCtstItTptPFMI "Used to identify the applicable J1939-73 FMI detected in the diesel oxidation catalyst intake temperature sensor by the manufacturer’s sensor control software i…";
CM_ SG_ 2566725630 Atttt2DsOxdtCtstOttTpt "Temperature of engine combustion byproducts leaving the diesel oxidation catalyst exhaust in exhaust bank 2.  This parameter should be used with engines fueled …";
CM_ SG_ 2566725630 Atttt2DsOxdtCtstOttTptPFMI "Used to identify the applicable J1939-73 FMI detected in the diesel oxidation catalyst outlet gas temperature sensor by the manufacturer’s sensor control softwa…";
CM_ BO_ 2566725886 "Aftertreatment 1 Diesel Oxidation Catalyst 1";
CM_ SG_ 2566725886 Atttt1DsOxdtCtstDtPss "Exhaust differential pressure measured between the intake and exhaust of a diesel oxidation catalyst in exhaust bank 1.  This parameter should be used with engi…";
CM_ SG_ 2566725886 Atttt1DsOxdtCtstDtPssPFMI "Used to identify the applicable J1939-73 FMI detected in the diesel oxidation catalyst differential pressure sensor by the manufacturer’s sensor control softwar…";
CM_ SG_ 2566725886 Atttt1DsOxdtCtstItTpt "Temperature of engine combustion byproducts entering the diesel oxidation catalyst in exhaust bank 1.  This parameter should be used with engines fueled by dies…";
CM_ SG_ 2566725886 Atttt1DsOxdtCtstItTptPFMI "Used to identify the applicable J1939-73 FMI detected in the diesel oxidation catalyst intake temperature sensor by the manufacturer’s sensor control software i…";
CM_ SG_ 2566725886 Atttt1DsOxdtCtstOttTpt "Temperature of engine combustion byproducts leaving the diesel oxidation catalyst exhaust in exhaust bank 1.  This parameter should be used with engines fueled …";
CM_ SG_ 2566725886 Atttt1DsOxdtCtstOttTptPFMI "Used to identify the applicable J1939-73 FMI detected in the diesel oxidation catalyst outlet gas temperature sensor by the manufacturer’s sensor control softwa…";
CM_ BO_ 2566726142 "Aftertreatment 2 Gas Oxidation Catalyst";
CM_ SG_ 2566726142 Atttt2GsOxdtCtstDtPss "Exhaust differential pressure measured between the intake and exhaust of the gas oxidation catalyst in exhaust bank 2.  This parameter should be used with engin…";
CM_ SG_ 2566726142 Atttt2GsOxdtCtstDtPssPFMI "Used to identify the applicable J1939-73 FMI detected in the gas oxidation catalyst differential pressure sensor by the manufacturer’s sensor control software i…";
CM_ SG_ 2566726142 Atttt2GsOxdtCtstItTpt "Temperature of engine combustion byproducts entering the gas oxidation catalyst in exhaust bank 2.  This parameter should be used with engines fueled by gaseous…";
CM_ SG_ 2566726142 Atttt2GsOxdtCtstItTptPFMI "Used to identify the applicable J1939-73 FMI detected in the gas oxidation catalyst intake gas temperature sensor by the manufacturer’s sensor control software …";
CM_ SG_ 2566726142 Atttt2GsOxdtCtstOttTpt "Temperature of engine combustion byproducts leaving the gas oxidation catalyst in exhaust bank 2.  This parameter should be used with engines fueled by gaseous …";
CM_ SG_ 2566726142 Atttt2GsOxdtCtstOttTptPFMI "Used to identify the applicable J1939-73 FMI detected in the gas oxidation catalyst outlet gas temperature sensor by the manufacturer’s sensor control software …";
CM_ BO_ 2566726398 "Aftertreatment 1 Gas Oxidation Catalyst";
CM_ SG_ 2566726398 Atttt1GsOxdtCtstDtPss "Exhaust differential pressure measured between the intake and exhaust of the gas oxidation catalyst in exhaust bank 1.  This parameter should be used with engin…";
CM_ SG_ 2566726398 Atttt1GsOxdtCtstDtPssPFMI "Used to identify the applicable J1939-73 FMI detected in the gas oxidation catalyst differential pressure sensor by the manufacturer’s sensor control software i…";
CM_ SG_ 2566726398 Atttt1GsOxdtCtstItTpt "Temperature of engine combustion byproducts entering the gas oxidation catalyst in exhaust bank 1.  This parameter should be used with engines fueled by gaseous…";
CM_ SG_ 2566726398 Atttt1GsOxdtCtstItTptPFMI "Used to identify the applicable J1939-73 FMI detected in the gas oxidation catalyst intake temperature sensor by the manufacturer’s sensor control software in e…";
CM_ SG_ 2566726398 Atttt1GsOxdtCtstOttTpt "Temperature of engine combustion byproducts leaving the gas oxidation catalyst in exhaust bank 1.  This parameter should be used with engines fueled by gaseous …";
CM_ SG_ 2566726398 Atttt1GsOxdtCtstOttTptPFMI "Used to identify the applicable J1939-73 FMI detected in the gas oxidation catalyst outlet temperature sensor by the manufacturer’s sensor control software in e…";
CM_ BO_ 2566730238 "Fan Drive #2";
CM_ SG_ 2566730238 EstimatedPercentFan2Speed "Estimated fan speed as a ratio of the fan drive (current speed) to the fully engaged fan drive (maximum fan speed).  A two state fan (off/on) will use 0% and 10…";
CM_ SG_ 2566730238 Fan2DriveBypassCommandStatus "Status of the Fan Drive Bypass Command for the second fan as being commanded by the ECU.  The fan drive bypass diverts pump pressure away from the hydraulic mot…";
CM_ SG_ 2566730238 Fan2DriveState "This parameter is used to indicate the current state or mode of operation by the second fan drive.0000b = Fan off0001b = Engine system–General0010b = Excessive …";
CM_ SG_ 2566730238 Fan2Speed "The speed of the second fan associated with engine coolant system.…";
CM_ SG_ 2566730238 HydraulicFan2MotorPressure "The hydraulic pressure used to drive the second fan system, sensed before the hydraulic fan motor.…";
CM_ BO_ 2566730750 "Aftertreatment 2 Diesel Exhaust Fluid Supply Information";
CM_ SG_ 2566730750 Aftrtrtmnt2DslExhstFldPmp "State of the Aftertreatment 2 Diesel Exhaust Fluid dosing pump.  Indicates if the pump is currently active (pumping).  00b = Off01b = On10b = Error11b = Not ava…";
CM_ SG_ 2566730750 Aftrtrtmnt2DslExhstFldPmpPwrRl "The state of the aftertreatment 2 diesel exhaust fluid pump power relay.00b = Not active - No power is being applied to the relay01b = Active - Power is being a…";
CM_ SG_ 2566730750 Aftrtrtmnt2DslExhstFldPmpStt "State of Aftertreatment 2 Diesel Exhaust Fluid dosing pump.00b = pump operational01b = pump error10b = reserved for SAE assignment11b = not available…";
CM_ SG_ 2566730750 Atttt2DsExstFdDsUt1DvtVv "Command to the valve which determines whether the diesel exhaust fluid of dosing unit 1 is delivered to the injector or is routed back to the diesel exhaust flu…";
CM_ SG_ 2566730750 Atttt2DsExstFdDsUt2DvtVv "Command to the valve which determines whether the diesel exhaust fluid of dosing unit 2 is delivered to the injector or is routed back to the diesel exhaust flu…";
CM_ SG_ 2566730750 Atttt2DsExstFdPp1MtSpd "Rotational speed of the motor driving the first or only pump for the diesel exhaust fluid used in aftertreatment system 2 (exhaust bank 2).…";
CM_ SG_ 2566730750 Atttt2DsExstFdPpDvPt "The percent (command) sent to the motor to control the speed of  the diesel exhaust fluid pump.…";
CM_ SG_ 2566730750 Atttt2DsExstFdTDVvCd "Commanded percentage of maximum Aftertreatment 2 Diesel Exhaust Fluid Tank Drain Valve opening. 100% means the the drain valve is fully open providing maximum f…";
CM_ SG_ 2566730750 Atttt2DsExstFdTFVvCd "Commanded percentage of maximum Aftertreatment 2 Diesel Exhaust Fluid Tank Fill Valve opening. 100% means the fill valve is fully open providing maximum flow of…";
CM_ BO_ 2566731006 "Aftertreatment 2 SCR Reagant Tank 2 Information";
CM_ SG_ 2566731006 Aftrtrtmnt2DslExhstFldQkThwHtr "The diesel exhaust fluid quick thaw tank heater percentage for aftertreatment system 2 (exhaust bank 2). 0% is off. See SPN 5415 for the command for this tank h…";
CM_ SG_ 2566731006 Atttt2DsExstFdQTwHtPFMI "Used to identify the applicable J1939-73 FMI detected for the heater of the diesel exhaust fluid quick thaw tank for aftertreatment system 2 (exhaust bank 2), a…";
CM_ SG_ 2566731006 Atttt2DsExstFdQTwLvPFMI "Used to identify the applicable J1939-73 FMI detected for the fluid level height of the diesel exhaust fluid quick thaw tank for aftertreatment system 2 (exhaus…";
CM_ SG_ 2566731006 Atttt2DsExstFdQTwTLv "The diesel exhaust fluid level height in mm in the diesel exhaust fluid quick thaw tank for aftertreatment system 2 (exhaust bank 2).  See SPN 4433 for alternat…";
CM_ SG_ 2566731006 Atttt2DsExstFdQTwTpt "The diesel exhaust fluid quick thaw tank temperature for aftertreatment system 2 (exhaust bank 2).…";
CM_ SG_ 2566731006 Atttt2DsExstFdQTwTptPFMI "Used to identify the applicable J1939-73 FMI detected for the diesel exhaust fluid quick thaw tank temperature for aftertreatment system 2 (exhaust bank 2), as …";
CM_ SG_ 2566731006 Atttt2DsExstFdQTwTV "Ratio of volume of diesel exhaust fluid to the total volume of diesel exhaust fluid storage container for aftertreatment system 2 (exhaust bank 2).  0% is empty…";
CM_ BO_ 2566731262 "Aftertreatment 2 Diesel Exhaust Fluid Tank 1 Information 1";
CM_ SG_ 2566731262 Aftrtrtmnt2DslExhstFldTnkHtr "Percentage of heating applied to the aftertreatment 2 diesel exhaust fluid tank heater.  A value of 0% means no heating applied, a value of 100% means full heat…";
CM_ SG_ 2566731262 Aftrtrtmnt2DslExhstFldTnkLvl "The diesel exhaust fluid level height in mm in the diesel exhaust fluid storage container for aftertreatment system 2 (exhaust bank 2).  See SPN 4426 and SPN 75…";
CM_ SG_ 2566731262 Aftrtrtmnt2DslExhstFldTnkVlm "Ratio of volume of diesel exhaust fluid to the total volume of the diesel exhaust fluid storage container for aftertreatment system 2 (exhaust bank 2).  0% is e…";
CM_ SG_ 2566731262 Atttt2DsExstFdT1HtPFMI "Used to identify the applicable J1939-73 FMI detected for the heater of the diesel exhaust fluid tank for aftertreatment system 2 (exhaust bank 2), as detected …";
CM_ SG_ 2566731262 Atttt2DsExstFdT1TptPFMI "Used to identify the applicable J1939-73 FMI detected for the diesel exhaust fluid tank temperature for aftertreatment system 2 (exhaust bank 2), as detected by…";
CM_ SG_ 2566731262 Atttt2DsExstFdTLvVPFMI "Used to identify the applicable J1939-73 FMI detected in the diesel exhaust fluid tank level sensor by the manufacturer's sensor control software.  This FMI is …";
CM_ SG_ 2566731262 Atttt2DsExstFdTTpt1 "Temperature of the diesel exhaust fluid in the storage tank.…";
CM_ BO_ 2566731518 "Aftertreatment 2 Diesel Exhaust Fluid Information 1";
CM_ SG_ 2566731518 Aftrtrtmnt2DslExhstFldCndtvt "A measure of the conductivity of the diesel exhaust fluid at the sensor.  The conductivity is an indication of the diesel exhaust fluid's chemical make up.…";
CM_ SG_ 2566731518 Aftrtrtmnt2DslExhstFldCnntrtn "A measure of the concentration of urea in water.  Zero percent means that the tank contains no urea.  A 32.5% value indicates that the reagent is of the proper …";
CM_ SG_ 2566731518 Aftrtrtmnt2DslExhstFldTmprtr2 "Temperature of the diesel exhaust fluid at the device measuring diesel exhaust fluid quality…";
CM_ SG_ 2566731518 Aftrtrtmnt2DslExhstFldTpPrprt "This parameter indicates the property of the fluid compound in the tank.  A value of 0011b indicates uncontaminated Diesel Exhaust Fluid.0000b = Urea concentrat…";
CM_ SG_ 2566731518 Atttt2DsExstFdPptsPFMI "Used to identify the applicable J1939-73 FMI that applies to the most significant failure of the diesel exhaust fluid properties sensor.  This may be used for i…";
CM_ SG_ 2566731518 Atttt2DsExstFdTpt2PFMI "Used to identify the applicable J1939-73 FMI that applies to the most significant failure of the diesel exhaust fluid temperature sensor. In the case of multipl…";
CM_ BO_ 2566731774 "Aftertreatment 2 SCR Service Information 1";
CM_ SG_ 2566731774 Aftrtrtmnt2SCRCnvrsnEffn "The SCR conversion efficiency percentage.  Calculated as 100 times the catalyst intake NOx minus the catalyst outlet NOx divided by the catalyst intake NOx.  Th…";
CM_ SG_ 2566731774 Aftrtrtmnt2SCRSstmSlftnLvl "Indicates the sulfur level in the SCR system for aftertreatment 2.100% level could be the regeneration trigger level (and if conditions are not favorable for re…";
CM_ SG_ 2566731774 Atttt2DsExstFdAvCspt "Measured use of diesel exhaust fluid by a Selective Catalytic Reduction system for exhaust emission control, averaged over the previous 15 hours of engine opera…";
CM_ SG_ 2566731774 Atttt2SCRCddDsExstFdCspt "This parameter transmits the amount of diesel exhaust fluid that the emissions control system has requested to be used, averaged over the past 15 hours of engin…";
CM_ BO_ 2566732030 "Aftertreatment 2 SCR Exhaust Gas Temperature 1";
CM_ SG_ 2566732030 Aftrtrtmnt2SCRIntkTmprtr "Temperature of engine combustion byproducts entering the SCR in exhaust bank 2.…";
CM_ SG_ 2566732030 Aftrtrtmnt2SCROtltTmprtr "Temperature of engine combustion byproducts leaving the SCR exhaust in exhaust bank 2.…";
CM_ SG_ 2566732030 Atttt2SCRItTptPFMI "Used to identify the applicable J1939-73 FMI detected in the SCR intake temperature sensor by the manufacturer’s sensor control software in exhaust bank 2. In t…";
CM_ SG_ 2566732030 Atttt2SCROttTptPFMI "Used to identify the applicable J1939-73 FMI detected in the SCR outlet temperature sensor by the manufacturer’s sensor control software in exhaust bank 2.  In …";
CM_ BO_ 2566732286 "Aftertreatment 2 SCR Exhaust Gas Pressures";
CM_ SG_ 2566732286 Aftrtrtmnt2SCRDffrntlPrssr "Differential pressure measured between the intake and exhaust of an SCR component in exhaust bank 2.…";
CM_ SG_ 2566732286 Aftrtrtmnt2SCRIntkAsltPrssr "Used to read the pressure at the catalyst intake of the selective catalytic reduction system of aftertreatment 2.…";
CM_ SG_ 2566732286 Aftrtrtmnt2SCRIntkPrssr "The gage pressure at the intake of the selective catalytic reduction system of Aftertreatment 2.…";
CM_ SG_ 2566732286 Atttt2SCRDtPssPFMI "Used to identify the applicable J1939-73 FMI detected in the SCR differential pressure sensor by the manufacturer’s sensor control software in exhaust bank 2. I…";
CM_ BO_ 2566732542 "Aftertreatment 2 SCR Dosing System Requests 2";
CM_ SG_ 2566732542 Aftrtrtmnt2DslExhstFldLnHtr1 "The diesel exhaust fluid line heater 1 request for aftertreatment system 2 (exhaust bank 2). 00b = request for heater to be inactive 01b = request for heater to…";
CM_ SG_ 2566732542 Aftrtrtmnt2DslExhstFldLnHtr10 "The diesel exhaust fluid line heater 10 request for aftertreatment system 2 (exhaust bank 2).00b = request for heater to be inactive01b = request for heater to …";
CM_ SG_ 2566732542 Aftrtrtmnt2DslExhstFldLnHtr2 "The diesel exhaust fluid line heater 2 request for aftertreatment system 2 (exhaust bank 2). 00b = request for heater to be inactive 01b = request for heater to…";
CM_ SG_ 2566732542 Aftrtrtmnt2DslExhstFldLnHtr3 "The diesel exhaust fluid line heater 3 request for aftertreatment system 2 (exhaust bank 2). 00b = request for heater to be inactive 01b = request for heater to…";
CM_ SG_ 2566732542 Aftrtrtmnt2DslExhstFldLnHtr4 "The diesel exhaust fluid line heater 4 request for aftertreatment system 2 (exhaust bank 2). 00b = request for heater to be inactive 01b = request for heater to…";
CM_ SG_ 2566732542 Aftrtrtmnt2DslExhstFldLnHtr5 "Identifies the diesel exhaust fluid line heater 5 request for aftertreatment system 2 (exhaust bank 2).00b = request for heater to be inactive 01b = request for…";
CM_ SG_ 2566732542 Aftrtrtmnt2DslExhstFldLnHtr6 "The diesel exhaust fluid line heater 6 request for aftertreatment system 2 (exhaust bank 2).00b = request for heater to be inactive01b = request for heater to b…";
CM_ SG_ 2566732542 Aftrtrtmnt2DslExhstFldLnHtr7 "The diesel exhaust fluid line heater 7 request for aftertreatment system 2 (exhaust bank 2).00b = request for heater to be inactive01b = request for heater to b…";
CM_ SG_ 2566732542 Aftrtrtmnt2DslExhstFldLnHtr8 "The diesel exhaust fluid line heater 8 request for aftertreatment system 2 (exhaust bank 2).00b = request for heater to be inactive01b = request for heater to b…";
CM_ SG_ 2566732542 Aftrtrtmnt2DslExhstFldLnHtr9 "The diesel exhaust fluid line heater 9 request for aftertreatment system 2 (exhaust bank 2).00b = request for heater to be inactive01b = request for heater to b…";
CM_ SG_ 2566732542 Aftrtrtmnt2DslExhstFldLnHtrRl1 "The aftertreatment system 2 diesel exhaust fluid line heater relay 1 is used to energize one or more DEF line heaters.00b = Off01b = On10b = Error11b = Not avai…";
CM_ SG_ 2566732542 Aftrtrtmnt2DslExhstFldLnHtrRl2 "The aftertreatment system 2 diesel exhaust fluid line heater relay 2 is used to energize one or more DEF line heaters.00b = Off01b = On10b = Error11b = Not avai…";
CM_ SG_ 2566732542 Aftrtrtmnt2DslExhstFldLnHtrRl3 "The aftertreatment system 2 diesel exhaust fluid line heater relay 3 is used to energize one or more DEF line heaters.00b = Off01b = On10b = Error11b = Not avai…";
CM_ SG_ 2566732542 Atttt2DsExstFdDsFtSppssRqst "Used if external devices can warn of conditions that require suppression of potential faults in the doser due to environmental conditions.00b = Error suppressio…";
CM_ SG_ 2566732542 Atttt2DsExstFdDsHtMdRqst "Used if multiple heater modes are available in the Doser.000b = Heater off001b = Heater economy mode010b = Heater automatic mode011b = Heater on100b to 110b = R…";
CM_ SG_ 2566732542 Atttt2DsExstFdQTwHtCd "The command for the heater of the diesel exhaust fluid quick thaw tank for aftertreatment system 2 (exhaust bank 2).  See SPN 4438 for the measured heater perce…";
CM_ SG_ 2566732542 Atttt2DsExstFdTHtCd "Command for the Aftertreatment 2 Diesel Exhaust Fluid Tank Heater.  A value of 0% means no heating applied, a value of 100% means full heating applied.  See SPN…";
CM_ BO_ 2566732798 "Aftertreatment 2 SCR Dosing System Information 2";
CM_ SG_ 2566732798 Aftrtrtmnt2DslExhstFldLnHtr1Stt "The diesel exhaust fluid line heater 1 state for aftertreatment system 2 (exhaust bank 2).00b = heater inactive 01b = heater active 10b = error 11b = not availa…";
CM_ SG_ 2566732798 Aftrtrtmnt2DslExhstFldLnHtr2Stt "The diesel exhaust fluid line heater 2 state for aftertreatment system 2 (exhaust bank 2).00b = heater inactive 01b = heater active 10b = error 11b = not availa…";
CM_ SG_ 2566732798 Aftrtrtmnt2DslExhstFldLnHtr3Stt "The diesel exhaust fluid line heater 3 state for aftertreatment system 2 (exhaust bank 2).00b = heater inactive 01b = heater active 10b = error 11b = not availa…";
CM_ SG_ 2566732798 Aftrtrtmnt2DslExhstFldLnHtr4Stt "The diesel exhaust fluid line heater 4 state for aftertreatment system 2 (exhaust bank 2).00b = heater inactive 01b = heater active 10b = error 11b = not availa…";
CM_ SG_ 2566732798 Aftrtrtmnt2SCRDsngArAssstVlv "The position of the valve used to regulate the air supply of an air assist SCR dosing system for an engine. 0% represents no supply and 100% is full supply.…";
CM_ SG_ 2566732798 Aftrtrtmnt2SCRFdkCntrlStts "The SCR feedback control status (open/closed loop) for aftertreatment system 2 (exhaust bank 2).000b = open loop control active 001b = closed loop control activ…";
CM_ SG_ 2566732798 Atttt2DsExstFdDs1Tpt "The temperature (measured closest to dosing valve) of the first or only DEF doser for aftertreatment system 2 (exhaust bank 2).…";
CM_ SG_ 2566732798 Atttt2DsExstFdLHt1PFMI "Used to identify the applicable J1939-73 FMI detected in the diesel exhaust fluid line heater 1, by the manufacturer’s control software in exhaust bank 2.  In t…";
CM_ SG_ 2566732798 Atttt2DsExstFdLHt2PFMI "Used to identify the applicable J1939-73 FMI detected in the diesel exhaust fluid line heater 2, by the manufacturer’s control software in exhaust bank 2.  In t…";
CM_ SG_ 2566732798 Atttt2DsExstFdLHt3PFMI "Used to identify the applicable J1939-73 FMI detected in the diesel exhaust fluid line heater 3, by the manufacturer’s control software in exhaust bank 2.  In t…";
CM_ SG_ 2566732798 Atttt2DsExstFdLHt4PFMI "Used to identify the applicable J1939-73 FMI detected in the diesel exhaust fluid line heater 4, by the manufacturer’s control software in exhaust bank 2.  In t…";
CM_ SG_ 2566732798 Atttt2SCRDsAAssstAstPss "The SCR dosing system air assist absolute pressure for aftertreatment system 2 (exhaust bank 2).  The air assist system is used to improve the dosed reagent ato…";
CM_ SG_ 2566732798 Atttt2SCRDsVvExstTptRdtRqst "Protection request for the doser valve of the SCR system to prevent overheating000b = no request 001b = reduction request stage 1010b = reduction request stage …";
CM_ BO_ 2566733054 "Aftertreatment 1 Diesel Exhaust Fluid Supply Information";
CM_ SG_ 2566733054 Aftrtrtmnt1DslExhstFldPmp "State of the aftertreatment 1 Diesel Exhaust Fluid dosing pump.  Indicates if the pump is currently active (pumping).  00b = Off01b = On10b = Error11b = Not ava…";
CM_ SG_ 2566733054 Aftrtrtmnt1DslExhstFldPmpPwrRl "The state of the aftertreatment 1 diesel exhaust fluid pump power relay.00b = not active - no power is being applied to the relay01b = active - power is being a…";
CM_ SG_ 2566733054 Aftrtrtmnt1DslExhstFldPmpStt "State of the aftertreatment 1 Diesel Exhaust Fluid dosing pump.  Indicates whether or not the pump is operational.00b = pump operational01b = pump error10b = re…";
CM_ SG_ 2566733054 Atttt1DsExstFdDsUt1DvtVv "Command to the valve which determines whether the diesel exhaust fluid on dosing unit 1 is delivered to the injector or is routed back to the diesel exhaust flu…";
CM_ SG_ 2566733054 Atttt1DsExstFdDsUt2DvtVv "Command to the valve which determines whether the diesel exhaust fluid on dosing unit 2 is delivered to the injector or is routed back to the diesel exhaust flu…";
CM_ SG_ 2566733054 Atttt1DsExstFdPp1MtSpd "Rotational speed of the motor driving the first or only pump for the diesel exhaust fluid used in aftertreatment system 1 (exhaust bank 1).…";
CM_ SG_ 2566733054 Atttt1DsExstFdPpDvPt "The percent (command) sent to the motor to control the speed of the diesel exhaust fluid pump.…";
CM_ SG_ 2566733054 Atttt1DsExstFdTDVvCd "Commanded percentage of maximum Aftertreatment 1 Diesel Exhaust Fluid Tank Drain Valve opening. 100% means the drain valve is fully open providing maximum flow …";
CM_ SG_ 2566733054 Atttt1DsExstFdTFVvCd "Commanded percentage of maximum Aftertreatment 1 Diesel Exhaust Fluid Tank Fill Valve opening. 100% means the fill valve is fully open providing maximum flow of…";
CM_ BO_ 2566733310 "Aftertreatment 1 SCR Reagant Tank 2 Information";
CM_ SG_ 2566733310 Aftrtrtmnt1DslExhstFldQkThwHtr "The diesel exhaust fluid quick thaw tank heater percentage for aftertreatment system 1 (exhaust bank 1). 0% is off. See SPN 5414 for the command for this tank h…";
CM_ SG_ 2566733310 Atttt1DsExstFdQTwHtPFMI "Used to identify the applicable J1939-73 FMI detected for the heater of the diesel exhaust fluid quick thaw tank for aftertreatment system 1 (exhaust bank 1), a…";
CM_ SG_ 2566733310 Atttt1DsExstFdQTwLvVPFMI "Used to identify the applicable J1939-73 FMI detected for the fluid level height of the diesel exhaust fluid quick thaw tank for aftertreatment system 1 (exhaus…";
CM_ SG_ 2566733310 Atttt1DsExstFdQTwTLv "The diesel exhaust fluid level height in mm in the diesel exhaust fluid quick thaw tank for aftertreatment system 1 (exhaust bank 1). See SPN 4367 for alternate…";
CM_ SG_ 2566733310 Atttt1DsExstFdQTwTpt "The diesel exhaust fluid quick thaw tank temperature for aftertreatment system 1 (exhaust bank 1).…";
CM_ SG_ 2566733310 Atttt1DsExstFdQTwTptPFMI "Used to identify the applicable J1939-73 FMI detected for the diesel exhaust fluid quick thaw tank temperature for aftertreatment system 1 (exhaust bank 1), as …";
CM_ SG_ 2566733310 Atttt1DsExstFdQTwTV "Ratio of volume of diesel exhaust fluid to the total volume of the diesel exhaust fluid quick thaw tank for aftertreatment system 1 (exhaust bank 1).  0% is emp…";
CM_ BO_ 2566733822 "Aftertreatment 1 SCR Exhaust Gas Pressures";
CM_ SG_ 2566733822 Aftrtrtmnt1SCRDffrntlPrssr "Differential pressure measured between the intake and outlet of an SCR component in exhaust bank 1.…";
CM_ SG_ 2566733822 Aftrtrtmnt1SCRIntkAsltPrssr "Used to read the pressure at the catalyst intake of the selective catalytic reduction system of aftertreatment 1.…";
CM_ SG_ 2566733822 Aftrtrtmnt1SCRIntkPrssr "The gage pressure at the intake of the selective catalytic reduction system of Aftertreatment 1.…";
CM_ SG_ 2566733822 Atttt1SCRDtPssPFMI "Used to identify the applicable J1939-73 FMI detected in the SCR differential pressure sensor by the manufacturer’s sensor control software in exhaust bank 1.  …";
CM_ BO_ 2566734078 "Aftertreatment 1 SCR Dosing System Requests 2";
CM_ SG_ 2566734078 Aftrtrtmnt1DslExhstFldLnHtr1 "The diesel exhaust fluid line heater 1 request for aftertreatment system 1 (exhaust bank 1).00b = request for heater to be inactive 01b = request for heater to …";
CM_ SG_ 2566734078 Aftrtrtmnt1DslExhstFldLnHtr10 "The diesel exhaust fluid line heater 10 request for aftertreatment system 1 (exhaust bank 1).00b = request for heater to be inactive01b = request for heater to …";
CM_ SG_ 2566734078 Aftrtrtmnt1DslExhstFldLnHtr2 "The diesel exhaust fluid line heater 2 request for aftertreatment system 1 (exhaust bank 1).00b = request for heater to be inactive 01b = request for heater to …";
CM_ SG_ 2566734078 Aftrtrtmnt1DslExhstFldLnHtr3 "The diesel exhaust fluid line heater 3 request for aftertreatment system 1 (exhaust bank 1).00b = request for heater to be inactive 01b = request for heater to …";
CM_ SG_ 2566734078 Aftrtrtmnt1DslExhstFldLnHtr4 "The diesel exhaust fluid line heater 4 request for aftertreatment system 1 (exhaust bank 1).00b = request for heater to be inactive 01b = request for heater to …";
CM_ SG_ 2566734078 Aftrtrtmnt1DslExhstFldLnHtr5 "The diesel exhaust fluid line heater 5 request for aftertreatment system 1 (exhaust bank 1).00b = request for heater to be inactive01b = request for heater to b…";
CM_ SG_ 2566734078 Aftrtrtmnt1DslExhstFldLnHtr6 "The diesel exhaust fluid line heater 6 request for aftertreatment system 1 (exhaust bank 1).00b = request for heater to be inactive01b = request for heater to b…";
CM_ SG_ 2566734078 Aftrtrtmnt1DslExhstFldLnHtr7 "The diesel exhaust fluid line heater 7 request for aftertreatment system 1 (exhaust bank 1).00b = request for heater to be inactive01b = request for heater to b…";
CM_ SG_ 2566734078 Aftrtrtmnt1DslExhstFldLnHtr8 "The diesel exhaust fluid line heater 8 request for aftertreatment system 1 (exhaust bank 1).00b = request for heater to be inactive01b = request for heater to b…";
CM_ SG_ 2566734078 Aftrtrtmnt1DslExhstFldLnHtr9 "The diesel exhaust fluid line heater 9 request for aftertreatment system 1 (exhaust bank 1).00b = request for heater to be inactive01b = request for heater to b…";
CM_ SG_ 2566734078 Aftrtrtmnt1DslExhstFldLnHtrRl1 "The Aftertreatment Diesel Exhaust Fluid Line Heater Relay 1 is used to energize one or more DEF line heaters.00b = Off01b = On10b = Error11b = Not available…";
CM_ SG_ 2566734078 Aftrtrtmnt1DslExhstFldLnHtrRl2 "The Aftertreatment Diesel Exhaust Fluid Line Heater Relay 2 is used to energize one or more DEF line heaters.00b = Off01b = On10b = Error11b = Not available…";
CM_ SG_ 2566734078 Aftrtrtmnt1DslExhstFldLnHtrRl3 "The aftertreatment diesel exhaust fluid line heater relay 3 is used to energize one or more DEF line heaters.00b = Off01b = On10b = Error11b = Not available…";
CM_ SG_ 2566734078 Atttt1DsExstFdDsFtSppssRqst "Used if external devices can warn of conditions that require suppression of potential faults in the doser due to environmental conditions.00b = Error suppressio…";
CM_ SG_ 2566734078 Atttt1DsExstFdDsHtMdRqst "Used if multiple heater modes are available in the Doser.000b = Heater off001b = Heater economy mode010b = Heater automatic mode011b = Heater on100b to 110b = R…";
CM_ SG_ 2566734078 Atttt1DsExstFdPpHtCd "Command for the Aftertreatment 1 Diesel Exhaust Fluid Pump Heater. A value of 0% means no heating commanded, a value of 100% means full heating commanded. See S…";
CM_ SG_ 2566734078 Atttt1DsExstFdQTwHtCd "The command for the heater of the diesel exhaust fluid quick thaw tank for aftertreatment system 1 (exhaust bank 1).  See SPN 4372 for the measured heater perce…";
CM_ SG_ 2566734078 Atttt1DsExstFdTHtCd "Command for the Aftertreatment 1 Diesel Exhaust Fluid Tank Heater.  A value of 0% means no heating applied, a value of 100% means full heating applied.  See SPN…";
BA_DEF_ SG_  "SPN" INT 0 524287;
BA_DEF_ BO_  "VFrameFormat" ENUM  "StandardCAN","ExtendedCAN","reserved","J1939PG";
BA_DEF_DEF_  "SPN" 0;
BA_DEF_DEF_  "VFrameFormat" "J1939PG";
BA_ "SPN" SG_ 2566697982 FusedOutput10Current 6089;
BA_ "SPN" SG_ 2566697982 FusedOutput11Current 6090;
BA_ "SPN" SG_ 2566697982 FusedOutput12Current 6091;
BA_ "SPN" SG_ 2566697982 FusedOutput13Current 6092;
BA_ "SPN" SG_ 2566697982 FusedOutput14Current 6093;
BA_ "SPN" SG_ 2566697982 FusedOutput15Current 6094;
BA_ "SPN" SG_ 2566697982 FusedOutput16Current 6095;
BA_ "SPN" SG_ 2566697982 FusedOutput17Current 6096;
BA_ "SPN" SG_ 2566697982 FusedOutput18Current 6097;
BA_ "SPN" SG_ 2566697982 FusedOutput19Current 6098;
BA_ "SPN" SG_ 2566697982 FusedOutput1Current 6080;
BA_ "SPN" SG_ 2566697982 FusedOutput20Current 6099;
BA_ "SPN" SG_ 2566697982 FusedOutput21Current 6100;
BA_ "SPN" SG_ 2566697982 FusedOutput22Current 6101;
BA_ "SPN" SG_ 2566697982 FusedOutput23Current 6102;
BA_ "SPN" SG_ 2566697982 FusedOutput24Current 6103;
BA_ "SPN" SG_ 2566697982 FusedOutput25Current 6104;
BA_ "SPN" SG_ 2566697982 FusedOutput26Current 6105;
BA_ "SPN" SG_ 2566697982 FusedOutput27Current 6106;
BA_ "SPN" SG_ 2566697982 FusedOutput28Current 6107;
BA_ "SPN" SG_ 2566697982 FusedOutput29Current 6108;
BA_ "SPN" SG_ 2566697982 FusedOutput2Current 6081;
BA_ "SPN" SG_ 2566697982 FusedOutput30Current 6109;
BA_ "SPN" SG_ 2566697982 FusedOutput31Current 6110;
BA_ "SPN" SG_ 2566697982 FusedOutput32Current 6111;
BA_ "SPN" SG_ 2566697982 FusedOutput3Current 6082;
BA_ "SPN" SG_ 2566697982 FusedOutput4Current 6083;
BA_ "SPN" SG_ 2566697982 FusedOutput5Current 6084;
BA_ "SPN" SG_ 2566697982 FusedOutput6Current 6085;
BA_ "SPN" SG_ 2566697982 FusedOutput7Current 6086;
BA_ "SPN" SG_ 2566697982 FusedOutput8Current 6087;
BA_ "SPN" SG_ 2566697982 FusedOutput9Current 6088;
BA_ "SPN" SG_ 2566698238 SwitchedOutput1 6051;
BA_ "SPN" SG_ 2566698238 SwitchedOutput10 6058;
BA_ "SPN" SG_ 2566698238 SwitchedOutput11 6057;
BA_ "SPN" SG_ 2566698238 SwitchedOutput12 6056;
BA_ "SPN" SG_ 2566698238 SwitchedOutput13 6063;
BA_ "SPN" SG_ 2566698238 SwitchedOutput14 6062;
BA_ "SPN" SG_ 2566698238 SwitchedOutput15 6061;
BA_ "SPN" SG_ 2566698238 SwitchedOutput16 6060;
BA_ "SPN" SG_ 2566698238 SwitchedOutput17 6067;
BA_ "SPN" SG_ 2566698238 SwitchedOutput18 6066;
BA_ "SPN" SG_ 2566698238 SwitchedOutput19 6065;
BA_ "SPN" SG_ 2566698238 SwitchedOutput2 6050;
BA_ "SPN" SG_ 2566698238 SwitchedOutput20 6064;
BA_ "SPN" SG_ 2566698238 SwitchedOutput21 6071;
BA_ "SPN" SG_ 2566698238 SwitchedOutput22 6070;
BA_ "SPN" SG_ 2566698238 SwitchedOutput23 6069;
BA_ "SPN" SG_ 2566698238 SwitchedOutput24 6068;
BA_ "SPN" SG_ 2566698238 SwitchedOutput25 6075;
BA_ "SPN" SG_ 2566698238 SwitchedOutput26 6074;
BA_ "SPN" SG_ 2566698238 SwitchedOutput27 6073;
BA_ "SPN" SG_ 2566698238 SwitchedOutput28 6072;
BA_ "SPN" SG_ 2566698238 SwitchedOutput29 6079;
BA_ "SPN" SG_ 2566698238 SwitchedOutput3 6049;
BA_ "SPN" SG_ 2566698238 SwitchedOutput30 6078;
BA_ "SPN" SG_ 2566698238 SwitchedOutput31 6077;
BA_ "SPN" SG_ 2566698238 SwitchedOutput32 6076;
BA_ "SPN" SG_ 2566698238 SwitchedOutput4 6048;
BA_ "SPN" SG_ 2566698238 SwitchedOutput5 6055;
BA_ "SPN" SG_ 2566698238 SwitchedOutput6 6054;
BA_ "SPN" SG_ 2566698238 SwitchedOutput7 6053;
BA_ "SPN" SG_ 2566698238 SwitchedOutput8 6052;
BA_ "SPN" SG_ 2566698238 SwitchedOutput9 6059;
BA_ "SPN" SG_ 2566698494 FusedOutput1 6019;
BA_ "SPN" SG_ 2566698494 FusedOutput10 6026;
BA_ "SPN" SG_ 2566698494 FusedOutput11 6025;
BA_ "SPN" SG_ 2566698494 FusedOutput12 6024;
BA_ "SPN" SG_ 2566698494 FusedOutput13 6031;
BA_ "SPN" SG_ 2566698494 FusedOutput14 6030;
BA_ "SPN" SG_ 2566698494 FusedOutput15 6029;
BA_ "SPN" SG_ 2566698494 FusedOutput16 6028;
BA_ "SPN" SG_ 2566698494 FusedOutput17 6035;
BA_ "SPN" SG_ 2566698494 FusedOutput18 6034;
BA_ "SPN" SG_ 2566698494 FusedOutput19 6033;
BA_ "SPN" SG_ 2566698494 FusedOutput2 6018;
BA_ "SPN" SG_ 2566698494 FusedOutput20 6032;
BA_ "SPN" SG_ 2566698494 FusedOutput21 6039;
BA_ "SPN" SG_ 2566698494 FusedOutput22 6038;
BA_ "SPN" SG_ 2566698494 FusedOutput23 6037;
BA_ "SPN" SG_ 2566698494 FusedOutput24 6036;
BA_ "SPN" SG_ 2566698494 FusedOutput25 6043;
BA_ "SPN" SG_ 2566698494 FusedOutput26 6042;
BA_ "SPN" SG_ 2566698494 FusedOutput27 6041;
BA_ "SPN" SG_ 2566698494 FusedOutput28 6040;
BA_ "SPN" SG_ 2566698494 FusedOutput29 6047;
BA_ "SPN" SG_ 2566698494 FusedOutput3 6017;
BA_ "SPN" SG_ 2566698494 FusedOutput30 6046;
BA_ "SPN" SG_ 2566698494 FusedOutput31 6045;
BA_ "SPN" SG_ 2566698494 FusedOutput32 6044;
BA_ "SPN" SG_ 2566698494 FusedOutput4 6016;
BA_ "SPN" SG_ 2566698494 FusedOutput5 6023;
BA_ "SPN" SG_ 2566698494 FusedOutput6 6022;
BA_ "SPN" SG_ 2566698494 FusedOutput7 6021;
BA_ "SPN" SG_ 2566698494 FusedOutput8 6020;
BA_ "SPN" SG_ 2566698494 FusedOutput9 6027;
BA_ "SPN" SG_ 2566698750 SLIBatteryPackCapacity 5982;
BA_ "SPN" SG_ 2566698750 SLIBatteryPackHealth 5983;
BA_ "SPN" SG_ 2566698750 SLIBatteryPackStateofCharge 5981;
BA_ "SPN" SG_ 2566698750 SLICrnkngPrdtdMnmmBttrVltg 7497;
BA_ "SPN" SG_ 2566699006 HrdBttrPkRmnngChrg 5464;
BA_ "SPN" SG_ 2566699006 HrdSstmEngnStpStrtRmnngPrntg 8558;
BA_ "SPN" SG_ 2566699006 HrdPrplsnMdMxmmSpdSttng 9708;
BA_ "SPN" SG_ 2566699006 HrdPrplsnMdRmnngDstn 9709;
BA_ "SPN" SG_ 2566699262 Atttt2DsPttFtTtNxtAtvRt 5979;
BA_ "SPN" SG_ 2566699262 Atttt2SCRSstTSLstSstCEvt 6948;
BA_ "SPN" SG_ 2566699518 Atttt1DsPttFtTtNxtAtvRt 5978;
BA_ "SPN" SG_ 2566699518 Atttt1SCRSstTSLstSstCEvt 6941;
BA_ "SPN" SG_ 2566699774 Atttt2DsExstFdCtMd1PwSpp1 5968;
BA_ "SPN" SG_ 2566699774 Atttt2DsExstFdCtMd1PwSpp2 6310;
BA_ "SPN" SG_ 2566699774 Atttt2DsExstFdCtMd1RCt 5967;
BA_ "SPN" SG_ 2566699774 Atttt2DsExstFdCtMd2PwSpp1 7533;
BA_ "SPN" SG_ 2566699774 Atttt2DsExstFdCtMd2PwSpp2 7534;
BA_ "SPN" SG_ 2566699774 Atttt2DsExstFdCtMd2RCt 7532;
BA_ "SPN" SG_ 2566699774 Atttt2DsExstFdCtMdCtB 8483;
BA_ "SPN" SG_ 2566700030 Atttt1DsExstFdCtMd1PwSpp1 5966;
BA_ "SPN" SG_ 2566700030 Atttt1DsExstFdCtMd1PwSpp2 6309;
BA_ "SPN" SG_ 2566700030 Atttt1DsExstFdCtMd1RCt 5965;
BA_ "SPN" SG_ 2566700030 Atttt1DsExstFdCtMd2PwSpp1 7522;
BA_ "SPN" SG_ 2566700030 Atttt1DsExstFdCtMd2PwSpp2 7523;
BA_ "SPN" SG_ 2566700030 Atttt1DsExstFdCtMd2RCt 7521;
BA_ "SPN" SG_ 2566700030 Atttt1DsExstFdCtMdCtB 7417;
BA_ "SPN" SG_ 2566700286 Aftrtrtmnt2TtlDslExhstFldUsd 5964;
BA_ "SPN" SG_ 2566700542 Aftrtrtmnt1TtlDslExhstFldUsd 5963;
BA_ "SPN" SG_ 2566700542 AftrtrtmntTrpDslExhstFld 6563;
BA_ "SPN" SG_ 2566701566 TransmissionClutch2Pressure 5937;
BA_ "SPN" SG_ 2566701566 TrnsmssnOlTrnsmssnClrOtltTmprtr 5938;
BA_ "SPN" SG_ 2566701822 ExtrnlEnrgSrCnntnStts 7898;
BA_ "SPN" SG_ 2566701822 HrdPrplsnMdTrnstnStts 7897;
BA_ "SPN" SG_ 2566701822 HrdSstmEltrAltrntrIndtr 7451;
BA_ "SPN" SG_ 2566701822 HrdSstmHghVltgExpsrIndtr 7454;
BA_ "SPN" SG_ 2566701822 HrdSstmIntlztnIndtr 7453;
BA_ "SPN" SG_ 2566701822 HrdSstmMtrOvrspdAdlAlrm 7450;
BA_ "SPN" SG_ 2566701822 HrdSstmMtrOvrspdIndtr 7449;
BA_ "SPN" SG_ 2566701822 HrdSstmPrplsnDslStts 8267;
BA_ "SPN" SG_ 2566701822 HrdSstmRgnrtvBrkngIndtr 7452;
BA_ "SPN" SG_ 2566701822 HybridPropulsionModeStatus 7896;
BA_ "SPN" SG_ 2566701822 HybridSystemEngineAssistStatus 7418;
BA_ "SPN" SG_ 2566701822 HybridSystemOBDRelatedDTCStatus 6810;
BA_ "SPN" SG_ 2566701822 HybridSystemOverheatIndicator 5873;
BA_ "SPN" SG_ 2566701822 HybridSystemServiceIndicator 7448;
BA_ "SPN" SG_ 2566701822 HybridSystemStopIndicator 5874;
BA_ "SPN" SG_ 2566701822 HybridSystemWarningIndicator 5872;
BA_ "SPN" SG_ 2566701822 PropulsionSystemActive 7315;
BA_ "SPN" SG_ 2566701822 StoredEnergySourceLevel 7895;
BA_ "SPN" SG_ 2566701822 StrdEnrgSrInrsngMdAllwd 7894;
BA_ "SPN" SG_ 2566701822 StrdEnrgSrOnlMdAllwd 7893;
BA_ "SPN" SG_ 2566702078 SupplyGasMethanePercentage 5867;
BA_ "SPN" SG_ 2566702334 Aftrtrtmnt2SCRIntrmdtTmprtr 5864;
BA_ "SPN" SG_ 2566702334 Atttt2SCRItdtTptPFMI 5865;
BA_ "SPN" SG_ 2566702590 Aftrtrtmnt1SCRIntrmdtTmprtr 5862;
BA_ "SPN" SG_ 2566702590 Atttt1SCRItdtTptPFMI 5863;
BA_ "SPN" SG_ 2566703358 EngineDualFuelMode 6791;
BA_ "SPN" SG_ 2566703358 EngineFuelingInhibitAllowed 5795;
BA_ "SPN" SG_ 2566703358 EngnFlngDsrdRqstCnt 6897;
BA_ "SPN" SG_ 2566703358 EngnFlngInhtPrvntdRsn 5866;
BA_ "SPN" SG_ 2566703358 EngnFlngInhtPrvntdRsnExtnsn 8145;
BA_ "SPN" SG_ 2566703358 EngnFlngInhtRqstCnt 6896;
BA_ "SPN" SG_ 2566703358 EngnGsSstttnFlPrntg 6333;
BA_ "SPN" SG_ 2566703358 EngnPrttnDrtOvrrdStts 9174;
BA_ "SPN" SG_ 2566703358 FeedbackEngineFuelingState 5794;
BA_ "SPN" SG_ 2566703358 SrAddrssfCntrllngDvfrFlngStt 6307;
BA_ "SPN" SG_ 2566703614 EngineFuelValve1Temperature 5785;
BA_ "SPN" SG_ 2566703614 EngineFuelValve2Temperature 5786;
BA_ "SPN" SG_ 2566703614 EngineThrottleValve1Position2 6650;
BA_ "SPN" SG_ 2566703614 EngineThrottleValve1Temperature 5783;
BA_ "SPN" SG_ 2566703614 EngineThrottleValve2Temperature 5784;
BA_ "SPN" SG_ 2566703614 EngnFlRkFlSpplTmprtr 7314;
BA_ "SPN" SG_ 2566703614 EngnTrhrgrWstgtAttr2Tmprtr 5787;
BA_ "SPN" SG_ 2566703870 EExstGsRt2Att1TptStts 5774;
BA_ "SPN" SG_ 2566703870 EExstGsRt2Att2TptStts 5778;
BA_ "SPN" SG_ 2566703870 EngnExhstGsRrltn2Attr1DsrdPstn 5776;
BA_ "SPN" SG_ 2566703870 EngnExhstGsRrltn2Attr1OprtnStts 5781;
BA_ "SPN" SG_ 2566703870 EngnExhstGsRrltn2Attr1PrlmnrFMI 5773;
BA_ "SPN" SG_ 2566703870 EngnExhstGsRrltn2Attr1Tmprtr 5775;
BA_ "SPN" SG_ 2566703870 EngnExhstGsRrltn2Attr2DsrdPstn 5780;
BA_ "SPN" SG_ 2566703870 EngnExhstGsRrltn2Attr2OprtnStts 5782;
BA_ "SPN" SG_ 2566703870 EngnExhstGsRrltn2Attr2PrlmnrFMI 5777;
BA_ "SPN" SG_ 2566703870 EngnExhstGsRrltn2Attr2Tmprtr 5779;
BA_ "SPN" SG_ 2566704126 EExstGsRt1Att1TptStts 5764;
BA_ "SPN" SG_ 2566704126 EExstGsRt1Att2TptStts 5768;
BA_ "SPN" SG_ 2566704126 EngnExhstGsRrltn1Attr1DsrdPstn 5766;
BA_ "SPN" SG_ 2566704126 EngnExhstGsRrltn1Attr1OprtnStts 5771;
BA_ "SPN" SG_ 2566704126 EngnExhstGsRrltn1Attr1PrlmnrFMI 5763;
BA_ "SPN" SG_ 2566704126 EngnExhstGsRrltn1Attr1Tmprtr 5765;
BA_ "SPN" SG_ 2566704126 EngnExhstGsRrltn1Attr2DsrdPstn 5770;
BA_ "SPN" SG_ 2566704126 EngnExhstGsRrltn1Attr2OprtnStts 5772;
BA_ "SPN" SG_ 2566704126 EngnExhstGsRrltn1Attr2PrlmnrFMI 5767;
BA_ "SPN" SG_ 2566704126 EngnExhstGsRrltn1Attr2Tmprtr 5769;
BA_ "SPN" SG_ 2566704382 Aftrtrtmnt1Otlt1GsSnsrPwrSppl 5759;
BA_ "SPN" SG_ 2566704382 Aftrtrtmnt1Otlt2GsSnsrPwrSppl 8147;
BA_ "SPN" SG_ 2566704382 Aftrtrtmnt2Otlt1GsSnsrPwrSppl 5761;
BA_ "SPN" SG_ 2566704382 EngnExhst1GsSnsr1PwrSppl 5758;
BA_ "SPN" SG_ 2566704382 EngnExhst2GsSnsr1PwrSppl 5760;
BA_ "SPN" SG_ 2566704382 EngnExhst1GsSnsr2PwrSppl 8146;
BA_ "SPN" SG_ 2566705150 Atttt1OttNOxSsSdssT 5709;
BA_ "SPN" SG_ 2566705150 Atttt2OttNOxSsSdssT 5711;
BA_ "SPN" SG_ 2566705150 EExst1ItNOxSsSdssT 5710;
BA_ "SPN" SG_ 2566705150 EExst2ItNOxSsSdssT 5712;
BA_ "SPN" SG_ 2566705406 Aftrtrtmnt1PrtltSnsr 5835;
BA_ "SPN" SG_ 2566705406 Aftrtrtmnt1PrtltSnsrCrrnt 7393;
BA_ "SPN" SG_ 2566705406 Aftrtrtmnt2PrtltSnsr 5836;
BA_ "SPN" SG_ 2566706686 Aftrtrtmnt1DslExhstFldPmpHtr 5706;
BA_ "SPN" SG_ 2566706686 Atttt1DsExstFdDsUt1HtR 5746;
BA_ "SPN" SG_ 2566706686 Atttt1DsExstFdPp2MtSpd 7461;
BA_ "SPN" SG_ 2566706686 Atttt1DsExstFdPpPwSpp 8474;
BA_ "SPN" SG_ 2566706942 Atttt1DsPttFt2StSsAssFq3 5652;
BA_ "SPN" SG_ 2566706942 Atttt1DsPttFt2StSsAssFq4 5654;
BA_ "SPN" SG_ 2566706942 Atttt1DsPttFt2StSsFq3StS 5653;
BA_ "SPN" SG_ 2566706942 Atttt1DsPttFt2StSsFq4StS 5655;
BA_ "SPN" SG_ 2566707198 Atttt1DsPttFt2StSsAssFq1 5648;
BA_ "SPN" SG_ 2566707198 Atttt1DsPttFt2StSsAssFq2 5650;
BA_ "SPN" SG_ 2566707198 Atttt1DsPttFt2StSsFq1StS 5649;
BA_ "SPN" SG_ 2566707198 Atttt1DsPttFt2StSsFq2StS 5651;
BA_ "SPN" SG_ 2566707454 Atttt1DsPttFt2StSsAssRqstFq1 5644;
BA_ "SPN" SG_ 2566707454 Atttt1DsPttFt2StSsAssRqstFq2 5645;
BA_ "SPN" SG_ 2566707454 Atttt1DsPttFt2StSsAssRqstFq3 5646;
BA_ "SPN" SG_ 2566707454 Atttt1DsPttFt2StSsAssRqstFq4 5647;
BA_ "SPN" SG_ 2566707710 Atttt1DsPttFt1StSsAssFq3 5640;
BA_ "SPN" SG_ 2566707710 Atttt1DsPttFt1StSsAssFq4 5642;
BA_ "SPN" SG_ 2566707710 Atttt1DsPttFt1StSsFq3StS 5641;
BA_ "SPN" SG_ 2566707710 Atttt1DsPttFt1StSsFq4StS 5643;
BA_ "SPN" SG_ 2566707966 Atttt1DsPttFt1StSsAssFq1 5636;
BA_ "SPN" SG_ 2566707966 Atttt1DsPttFt1StSsAssFq2 5638;
BA_ "SPN" SG_ 2566707966 Atttt1DsPttFt1StSsFq1StS 5637;
BA_ "SPN" SG_ 2566707966 Atttt1DsPttFt1StSsFq2StS 5639;
BA_ "SPN" SG_ 2566708222 Atttt1DsPttFt1StSsAssRqstFq1 5632;
BA_ "SPN" SG_ 2566708222 Atttt1DsPttFt1StSsAssRqstFq2 5633;
BA_ "SPN" SG_ 2566708222 Atttt1DsPttFt1StSsAssRqstFq3 5634;
BA_ "SPN" SG_ 2566708222 Atttt1DsPttFt1StSsAssRqstFq4 5635;
BA_ "SPN" SG_ 2566708478 AdptvCrsCntrlRdnssStts 5606;
BA_ "SPN" SG_ 2566708478 AEBSreadinessstate 6208;
BA_ "SPN" SG_ 2566708478 CrsCntrlDrvrCnlltnStts 7836;
BA_ "SPN" SG_ 2566708478 CrsCntrlStSpdHghRsltn 6809;
BA_ "SPN" SG_ 2566708478 CruiseControlSpeed 7319;
BA_ "SPN" SG_ 2566708478 PrdtvCrsCntrlStSpdOffstStts 7318;
BA_ "SPN" SG_ 2566708478 SAddssCtDvDsCsCt 5608;
BA_ "SPN" SG_ 2566708478 SAddssCtDvPsCsCt 5609;
BA_ "SPN" SG_ 2566708734 Aftrtrtmnt2SndrArAsltPrssr 5590;
BA_ "SPN" SG_ 2566708990 Aftrtrtmnt1SndrArAsltPrssr 5589;
BA_ "SPN" SG_ 2566708990 OprtrIndmntOvrrdRnwlRqrd 10154;
BA_ "SPN" SG_ 2566709246 EFSppPpItAstPssExtddR 7472;
BA_ "SPN" SG_ 2566709246 EngineFuelFilterDegradation 5584;
BA_ "SPN" SG_ 2566709246 EngineFuelReturnPressure 6816;
BA_ "SPN" SG_ 2566709246 EngnFlDlvrAsltPrssr 5578;
BA_ "SPN" SG_ 2566709246 EngnFltrdFlDlvrAsltPrssr 5580;
BA_ "SPN" SG_ 2566709246 EngnFltrdFlDlvrPrssr 5579;
BA_ "SPN" SG_ 2566709246 EngnThrttlVlv2DffrntlPrssr 7595;
BA_ "SPN" SG_ 2566709502 Aftertreatment1FuelMassRate 5503;
BA_ "SPN" SG_ 2566709502 Aftertreatment2FuelMassRate 5834;
BA_ "SPN" SG_ 2566709502 Atttt1DsPttFtItTptStPt 5501;
BA_ "SPN" SG_ 2566709502 EngineUnburnedFuelPercentage 5502;
BA_ "SPN" SG_ 2566709758 EngineDieselFuelDemandRate 7596;
BA_ "SPN" SG_ 2566709758 EngineFuelRateHighResolution 1600;
BA_ "SPN" SG_ 2566710014 SpplmntlFnCntrllrECUTmprtr 5561;
BA_ "SPN" SG_ 2566710014 SpplmntlFnCntrllrTmprtrStts 5559;
BA_ "SPN" SG_ 2566710014 SupplementalFanCurrent 5563;
BA_ "SPN" SG_ 2566710014 SupplementalFanDirectionStatus 5557;
BA_ "SPN" SG_ 2566710014 SupplementalFanDriveStatus 5560;
BA_ "SPN" SG_ 2566710014 SupplementalFanEnableStatus 5556;
BA_ "SPN" SG_ 2566710014 SupplementalFanPower 5564;
BA_ "SPN" SG_ 2566710014 SupplementalFanSpeed 5562;
BA_ "SPN" SG_ 2566710014 SupplementalFanVelocityStatus 5558;
BA_ "SPN" SG_ 2566710526 EngineFuelDensity 5538;
BA_ "SPN" SG_ 2566710526 EngineFuelDynamicViscosity 5537;
BA_ "SPN" SG_ 2566710526 EngnFl1Tmprtr1HghRsltn 5540;
BA_ "SPN" SG_ 2566710526 EngnFlDltrtHghRsltn 5539;
BA_ "SPN" SG_ 2566710782 HdrlOlRltvDltrtHghRsltn 5535;
BA_ "SPN" SG_ 2566710782 HdrlOlTmprtrHghRsltn 5536;
BA_ "SPN" SG_ 2566710782 HydraulicOilDensity 5534;
BA_ "SPN" SG_ 2566710782 HydraulicOilDynamicViscosity 5533;
BA_ "SPN" SG_ 2566711038 LubricationCycleModeLockStatus 5515;
BA_ "SPN" SG_ 2566711038 LubricationCycleModeStatus 5516;
BA_ "SPN" SG_ 2566711038 LubricationOperationModeStatus 5517;
BA_ "SPN" SG_ 2566711038 LubricationPumpEnableStatus 5518;
BA_ "SPN" SG_ 2566711038 LubricationReservoirLevel 5519;
BA_ "SPN" SG_ 2566711038 LubricationTimingCycleStatus 5520;
BA_ "SPN" SG_ 2566711294 EngnFrtnPrntTrqAtIdlPnt1 5471;
BA_ "SPN" SG_ 2566711294 EngnFrtnPrntTrqPnt2 5472;
BA_ "SPN" SG_ 2566711294 EngnFrtnPrntTrqPnt3 5473;
BA_ "SPN" SG_ 2566711294 EngnFrtnPrntTrqPnt4 5474;
BA_ "SPN" SG_ 2566711294 EngnFrtnPrntTrqPnt5 5475;
BA_ "SPN" SG_ 2566711294 EngnFrtnPrntTrqPnt6 5476;
BA_ "SPN" SG_ 2566711294 EngnFrtnPrntTrqPnt7 5477;
BA_ "SPN" SG_ 2566711550 ItVvAttSstOPss1SdCt 5499;
BA_ "SPN" SG_ 2566711550 ItVvAttSstOPss2SdCt 5500;
BA_ "SPN" SG_ 2566711806 Armrest1Switch1 1503;
BA_ "SPN" SG_ 2566711806 Armrest1Switch2 5492;
BA_ "SPN" SG_ 2566711806 Armrest2Switch1 5493;
BA_ "SPN" SG_ 2566711806 Armrest2Switch2 5494;
BA_ "SPN" SG_ 2566712318 Aftrtrtmnt2NOxAdsrrDslftnStts 5462;
BA_ "SPN" SG_ 2566712318 Aftrtrtmnt2NOxAdsrrRgnrtnStts 5460;
BA_ "SPN" SG_ 2566712574 Aftrtrtmnt1NOxAdsrrDslftnStts 5461;
BA_ "SPN" SG_ 2566712574 Aftrtrtmnt1NOxAdsrrRgnrtnStts 5459;
BA_ "SPN" SG_ 2566712830 Atttt2WUpDsOxdtCtstItTpt 5315;
BA_ "SPN" SG_ 2566712830 Atttt2WUpDsOxdtCtstOttTpt 5316;
BA_ "SPN" SG_ 2566713598 EngnFlFltrStnSdDgrdtn 6716;
BA_ "SPN" SG_ 2566713598 EngnFlFltrStnSdIntkAsltPrssr 5417;
BA_ "SPN" SG_ 2566713598 FuelTankTransferPump 4010;
BA_ "SPN" SG_ 2566713598 FuelTankTransferPumpPressure 7395;
BA_ "SPN" SG_ 2566713598 EngineFuelPumpIntakeOilPressure 9648;
BA_ "SPN" SG_ 2566713854 EExstPssRtCtOptStts 5628;
BA_ "SPN" SG_ 2566713854 EngnExhstBnk1PrssrRgltrPstn 5625;
BA_ "SPN" SG_ 2566713854 EngnExhstPrssrAttr1DsrdPstn 5789;
BA_ "SPN" SG_ 2566713854 EngnExhstPrssrAttr1Tmprtr 5790;
BA_ "SPN" SG_ 2566713854 EngnExhstPrssrRgltrPrlmnrFMI 5626;
BA_ "SPN" SG_ 2566713854 EngnExhstPrssrRgltrTmprtrStts 5627;
BA_ "SPN" SG_ 2566713854 EngnTrhrgrWstgtAttr1OprtnStts 5451;
BA_ "SPN" SG_ 2566713854 EngnTrhrgrWstgtAttr1Tmprtr 5788;
BA_ "SPN" SG_ 2566713854 EngnTrhrgrWstgtAttr2OprtnStts 5452;
BA_ "SPN" SG_ 2566713854 EngnTrhrgrWstgtAttr2PrlmnrFMI 5384;
BA_ "SPN" SG_ 2566713854 EngnTrhrgrWstgtAttr2TmprtrStts 5385;
BA_ "SPN" SG_ 2566714110 EngineFuelValve1OperationStatus 5447;
BA_ "SPN" SG_ 2566714110 EngineFuelValve1PreliminaryFMI 5380;
BA_ "SPN" SG_ 2566714110 EngineFuelValve2OperationStatus 5448;
BA_ "SPN" SG_ 2566714110 EngineFuelValve2PreliminaryFMI 5382;
BA_ "SPN" SG_ 2566714110 EngnDsrdThrttlVlv1Pstn 5374;
BA_ "SPN" SG_ 2566714110 EngnDsrdThrttlVlv2Pstn 5377;
BA_ "SPN" SG_ 2566714110 EngnFlVlv1TmprtrStts 5381;
BA_ "SPN" SG_ 2566714110 EngnFlVlv2TmprtrStts 5383;
BA_ "SPN" SG_ 2566714110 EngnThrttlVlv1OprtnStts 5445;
BA_ "SPN" SG_ 2566714110 EngnThrttlVlv1PrlmnrFMI 5375;
BA_ "SPN" SG_ 2566714110 EngnThrttlVlv1TmprtrStts 5376;
BA_ "SPN" SG_ 2566714110 EngnThrttlVlv2OprtnStts 5446;
BA_ "SPN" SG_ 2566714110 EngnThrttlVlv2PrlmnrFMI 5378;
BA_ "SPN" SG_ 2566714110 EngnThrttlVlv2Tmprtrstts 5379;
BA_ "SPN" SG_ 2566714366 EngnTrhrgrCmprssrBpssAttr2Pstn 5388;
BA_ "SPN" SG_ 2566714366 ETCpssBpssAtt1OptStts 5449;
BA_ "SPN" SG_ 2566714366 ETCpssBpssAtt1Tpt 5791;
BA_ "SPN" SG_ 2566714366 ETCpssBpssAtt2DsdPst 5389;
BA_ "SPN" SG_ 2566714366 ETCpssBpssAtt2OptStts 5450;
BA_ "SPN" SG_ 2566714366 ETCpssBpssAtt2Tpt 5792;
BA_ "SPN" SG_ 2566714366 ETCpssBpssAtt2TptStts 5391;
BA_ "SPN" SG_ 2566714366 ETpssBpssAtt2PFMI 5390;
BA_ "SPN" SG_ 2566714622 EngnChrgArClr2AmntArTmprtr 5291;
BA_ "SPN" SG_ 2566714622 EngnChrgArClr2Effn 5292;
BA_ "SPN" SG_ 2566714622 EngnChrgArClr2IntkTmprtr 5289;
BA_ "SPN" SG_ 2566714622 EngnChrgArClr2OtltTmprtr 5290;
BA_ "SPN" SG_ 2566714878 EngnChrgArClr2PrlrEffn 5288;
BA_ "SPN" SG_ 2566714878 EngnChrgArClr2PrlrIntkTmprtr 5286;
BA_ "SPN" SG_ 2566714878 EngnChrgArClr2PrlrOtltTmprtr 5287;
BA_ "SPN" SG_ 2566715134 EngnChrgArClr1AmntArTmprtr 5284;
BA_ "SPN" SG_ 2566715134 EngnChrgArClr1Effn 5285;
BA_ "SPN" SG_ 2566715134 EngnChrgArClr1IntkTmprtr 5283;
BA_ "SPN" SG_ 2566715390 EngnChrgArClr1PrlrEffn 5282;
BA_ "SPN" SG_ 2566715390 EngnChrgArClr1PrlrIntkTmprtr 5280;
BA_ "SPN" SG_ 2566715390 EngnChrgArClr1PrlrOtltTmprtr 5281;
BA_ "SPN" SG_ 2566715646 Atttt2DsPttFtStSM 5271;
BA_ "SPN" SG_ 2566715646 Atttt2DsPttFtStSMx 5270;
BA_ "SPN" SG_ 2566715646 Atttt2DsPttFtStSStddDvt 5269;
BA_ "SPN" SG_ 2566715902 Atttt1DsPttFtStSM 5268;
BA_ "SPN" SG_ 2566715902 Atttt1DsPttFtStSMx 5267;
BA_ "SPN" SG_ 2566715902 Atttt1DsPttFtStSStddDvt 5266;
BA_ "SPN" SG_ 2566717438 EngnExhstGsRrltn2MxrIntkTmprtr 5256;
BA_ "SPN" SG_ 2566717438 EngnExhstGsRrltn2Tmprtr 5255;
BA_ "SPN" SG_ 2566717950 LowVoltageDisconnectTemperature 5148;
BA_ "SPN" SG_ 2566717950 LwVltgDsnntCrrntOprtngMd 5143;
BA_ "SPN" SG_ 2566717950 LwVltgDsnntMnlCnntStt 5142;
BA_ "SPN" SG_ 2566717950 LwVltgDsnntMnlDsnntStt 5141;
BA_ "SPN" SG_ 2566717950 LwVltgDsnntOtpt1Stt 5146;
BA_ "SPN" SG_ 2566717950 LwVltgDsnntOtpt2Stt 5145;
BA_ "SPN" SG_ 2566717950 LwVltgDsnntOtpt3Stt 5144;
BA_ "SPN" SG_ 2566717950 LwVltgDsnntVtOtptStt 5147;
BA_ "SPN" SG_ 2566718718 HillHolderLampData 1848;
BA_ "SPN" SG_ 2566718718 VehicleAirPressureLowLampData 5106;
BA_ "SPN" SG_ 2566718718 VehicleBatteryChargingLampData 5108;
BA_ "SPN" SG_ 2566718718 VehicleFuelLevelLowLampData 5105;
BA_ "SPN" SG_ 2566718718 VhlBttrVltgLwLmpDt 5104;
BA_ "SPN" SG_ 2566718718 VhlHVACRrltnLmpDt 5107;
BA_ "SPN" SG_ 2566718974 CmprssnBrkEnlSwthIndtrLmpDt 5098;
BA_ "SPN" SG_ 2566718974 EngineAmberWarningLampData 5094;
BA_ "SPN" SG_ 2566718974 EngineBrakeActiveLampData 5097;
BA_ "SPN" SG_ 2566718974 EngineCoolantLevelLowLampData 5101;
BA_ "SPN" SG_ 2566718974 EngineOilPressureLowLampData 5099;
BA_ "SPN" SG_ 2566718974 EngineProtectLampData 5093;
BA_ "SPN" SG_ 2566718974 EngineRedStopLampData 5095;
BA_ "SPN" SG_ 2566718974 EngineSpeedHighLampData 6711;
BA_ "SPN" SG_ 2566718974 EngineSpeedVeryHighLampData 6712;
BA_ "SPN" SG_ 2566718974 EngineWaitToStartLampData 5416;
BA_ "SPN" SG_ 2566718974 EngnArFltrRstrtnLmpDt 5103;
BA_ "SPN" SG_ 2566718974 EngnClntTmprtrHghLmpDt 5100;
BA_ "SPN" SG_ 2566718974 EngnCntrlMdl1RdfrUsLmpDt 6202;
BA_ "SPN" SG_ 2566718974 EngnCntrlMdl2RdfrUsLmpDt 6203;
BA_ "SPN" SG_ 2566718974 EngnCntrlMdl3RdfrUsLmpDt 6204;
BA_ "SPN" SG_ 2566718974 EngnFlFltrRstrtdLmpDt 5470;
BA_ "SPN" SG_ 2566718974 EngnIdlMngmntAtvLmpDt 5102;
BA_ "SPN" SG_ 2566718974 OBDMalfunctionIndicatorLampData 5096;
BA_ "SPN" SG_ 2566718974 VhlAlrtnRtLmtLmpDt 6900;
BA_ "SPN" SG_ 2566718974 EngnStpStrtAtmtStpAtvLmpDt 9680;
BA_ "SPN" SG_ 2566718974 EngnStpStrtAtmtStrtFldLmpDt 9681;
BA_ "SPN" SG_ 2566718974 EngineStopStartEnabledLampData 9682;
BA_ "SPN" SG_ 2566719230 HillHolderLampCommand 1847;
BA_ "SPN" SG_ 2566719230 VehicleFuelLevelLowLampCommand 5088;
BA_ "SPN" SG_ 2566719230 VhlArPrssrLwLmpCmmnd 5089;
BA_ "SPN" SG_ 2566719230 VhlBttrChrgngLmpCmmnd 5091;
BA_ "SPN" SG_ 2566719230 VhlBttrVltgLwLmpCmmnd 5087;
BA_ "SPN" SG_ 2566719230 VhlHVACRrltnLmpCmmnd 5090;
BA_ "SPN" SG_ 2566719486 CmprssnBrkEnlSwthIndtrLmpCmmnd 3987;
BA_ "SPN" SG_ 2566719486 EngineAmberWarningLampCommand 5078;
BA_ "SPN" SG_ 2566719486 EngineBrakeActiveLampCommand 5081;
BA_ "SPN" SG_ 2566719486 EngineOilPressureLowLampCommand 5082;
BA_ "SPN" SG_ 2566719486 EngineProtectLampCommand 5077;
BA_ "SPN" SG_ 2566719486 EngineRedStopLampCommand 5079;
BA_ "SPN" SG_ 2566719486 EngineSpeedHighLampCommand 6709;
BA_ "SPN" SG_ 2566719486 EngineSpeedVeryHighLampCommand 6710;
BA_ "SPN" SG_ 2566719486 EngnArFltrRstrtnLmpCmmnd 5086;
BA_ "SPN" SG_ 2566719486 EngnClntLvlLwLmpCmmnd 5084;
BA_ "SPN" SG_ 2566719486 EngnClntTmprtrHghLmpCmmnd 5083;
BA_ "SPN" SG_ 2566719486 EngnCntrlMdl1RdfrUsLmpCmmnd 6205;
BA_ "SPN" SG_ 2566719486 EngnCntrlMdl2RdfrUsLmpCmmnd 6206;
BA_ "SPN" SG_ 2566719486 EngnCntrlMdl3RdfrUsLmpCmmnd 6207;
BA_ "SPN" SG_ 2566719486 EngnFlFltrRstrtdLmpCmmnd 5469;
BA_ "SPN" SG_ 2566719486 EngnIdlMngmntAtvLmpCmmnd 5085;
BA_ "SPN" SG_ 2566719486 EngnIdlMngmntPndngEvntLmpCmmnd 9372;
BA_ "SPN" SG_ 2566719486 OBDMlfntnIndtrLmpCmmnd 5080;
BA_ "SPN" SG_ 2566719486 VhlAlrtnRtLmtLmpCmmnd 6899;
BA_ "SPN" SG_ 2566719486 EngnStpStrtAtmtStpAtvLmpCmmnd 9683;
BA_ "SPN" SG_ 2566719486 EngnStpStrtAtmtStrtFldLmpCmmnd 9684;
BA_ "SPN" SG_ 2566719486 EngnStpStrtEnldLmpCmmnd 9685;
BA_ "SPN" SG_ 2566719998 EngineTripFuelHighResolution 5053;
BA_ "SPN" SG_ 2566719998 EngnTtlFlUsdHghRsltn 5054;
BA_ "SPN" SG_ 2566722302 GeneratorOverheatStatus 5000;
BA_ "SPN" SG_ 2566722302 GensetEnableActiveStatus 5005;
BA_ "SPN" SG_ 2566722302 GensetSoftstartActiveStatus 5004;
BA_ "SPN" SG_ 2566722302 GnrtrDtClExddStts 5007;
BA_ "SPN" SG_ 2566722302 GnstSstmOtptVltgRngStts 5001;
BA_ "SPN" SG_ 2566722302 GrappleMagnetSelectionSwitch 5003;
BA_ "SPN" SG_ 2566722302 ReverseCurrentRangeSetting 5002;
BA_ "SPN" SG_ 2566722302 VoltageMonitorActiveStatus 5006;
BA_ "SPN" SG_ 2566722558 MagnetBoostTime 4998;
BA_ "SPN" SG_ 2566722558 MagnetRatedPower 4999;
BA_ "SPN" SG_ 2566722814 BatteryCharger2OutputCurrent 4997;
BA_ "SPN" SG_ 2566722814 BatteryCharger2OutputVoltage 4996;
BA_ "SPN" SG_ 2566722814 BatteryCharger2PowerLineState 4995;
BA_ "SPN" SG_ 2566722814 BatteryCharger2State 4994;
BA_ "SPN" SG_ 2566723070 BatteryCharger1OutputCurrent 4993;
BA_ "SPN" SG_ 2566723070 BatteryCharger1OutputVoltage 4992;
BA_ "SPN" SG_ 2566723070 BatteryCharger1PowerLineState 4991;
BA_ "SPN" SG_ 2566723070 BatteryCharger1State 4990;
BA_ "SPN" SG_ 2566724350 Atttt1WUpDsOxdtCtstItTpt 4809;
BA_ "SPN" SG_ 2566724350 Atttt1WUpDsOxdtCtstOttTpt 4810;
BA_ "SPN" SG_ 2566724606 Aftrtrtmnt2DslPrtltFltrMnStSgnl 4788;
BA_ "SPN" SG_ 2566724606 Aftrtrtmnt2DslPrtltFltrStDnst 4787;
BA_ "SPN" SG_ 2566724606 Aftrtrtmnt2DslPrtltFltrStMss 4786;
BA_ "SPN" SG_ 2566724606 Atttt2DsPttFtMdStS 4789;
BA_ "SPN" SG_ 2566724606 Atttt2DsPttFtStSsPFMI 4790;
BA_ "SPN" SG_ 2566724606 DsPttFt2StSsECUItTpt 5570;
BA_ "SPN" SG_ 2566724862 Aftrtrtmnt1DslPrtltFltrMnStSgnl 4783;
BA_ "SPN" SG_ 2566724862 Aftrtrtmnt1DslPrtltFltrStDnst 4782;
BA_ "SPN" SG_ 2566724862 Aftrtrtmnt1DslPrtltFltrStMss 4781;
BA_ "SPN" SG_ 2566724862 Atttt1DsPttFtMdStS 4784;
BA_ "SPN" SG_ 2566724862 Atttt1DsPttFtStSsPFMI 4785;
BA_ "SPN" SG_ 2566724862 DsPttFt1StSsECUItTpt 5569;
BA_ "SPN" SG_ 2566725118 Atttt1TWCtstDtTpt 4779;
BA_ "SPN" SG_ 2566725118 Atttt2TWCtstDtTpt 4780;
BA_ "SPN" SG_ 2566725374 Atttt1GsOxdtCtstDtTpt 4777;
BA_ "SPN" SG_ 2566725374 Atttt2GsOxdtCtstDtTpt 4778;
BA_ "SPN" SG_ 2566725630 Atttt2DsOxdtCtstDtPss 4773;
BA_ "SPN" SG_ 2566725630 Atttt2DsOxdtCtstDtPssPFMI 4776;
BA_ "SPN" SG_ 2566725630 Atttt2DsOxdtCtstItTpt 4771;
BA_ "SPN" SG_ 2566725630 Atttt2DsOxdtCtstItTptPFMI 4774;
BA_ "SPN" SG_ 2566725630 Atttt2DsOxdtCtstOttTpt 4772;
BA_ "SPN" SG_ 2566725630 Atttt2DsOxdtCtstOttTptPFMI 4775;
BA_ "SPN" SG_ 2566725886 Atttt1DsOxdtCtstDtPss 4767;
BA_ "SPN" SG_ 2566725886 Atttt1DsOxdtCtstDtPssPFMI 4770;
BA_ "SPN" SG_ 2566725886 Atttt1DsOxdtCtstItTpt 4765;
BA_ "SPN" SG_ 2566725886 Atttt1DsOxdtCtstItTptPFMI 4768;
BA_ "SPN" SG_ 2566725886 Atttt1DsOxdtCtstOttTpt 4766;
BA_ "SPN" SG_ 2566725886 Atttt1DsOxdtCtstOttTptPFMI 4769;
BA_ "SPN" SG_ 2566726142 Atttt2GsOxdtCtstDtPss 4761;
BA_ "SPN" SG_ 2566726142 Atttt2GsOxdtCtstDtPssPFMI 4764;
BA_ "SPN" SG_ 2566726142 Atttt2GsOxdtCtstItTpt 4759;
BA_ "SPN" SG_ 2566726142 Atttt2GsOxdtCtstItTptPFMI 4762;
BA_ "SPN" SG_ 2566726142 Atttt2GsOxdtCtstOttTpt 4760;
BA_ "SPN" SG_ 2566726142 Atttt2GsOxdtCtstOttTptPFMI 4763;
BA_ "SPN" SG_ 2566726398 Atttt1GsOxdtCtstDtPss 4755;
BA_ "SPN" SG_ 2566726398 Atttt1GsOxdtCtstDtPssPFMI 4758;
BA_ "SPN" SG_ 2566726398 Atttt1GsOxdtCtstItTpt 4753;
BA_ "SPN" SG_ 2566726398 Atttt1GsOxdtCtstItTptPFMI 4756;
BA_ "SPN" SG_ 2566726398 Atttt1GsOxdtCtstOttTpt 4754;
BA_ "SPN" SG_ 2566726398 Atttt1GsOxdtCtstOttTptPFMI 4757;
BA_ "SPN" SG_ 2566730238 EstimatedPercentFan2Speed 1550;
BA_ "SPN" SG_ 2566730238 Fan2DriveBypassCommandStatus 1708;
BA_ "SPN" SG_ 2566730238 Fan2DriveState 1557;
BA_ "SPN" SG_ 2566730238 Fan2Speed 1598;
BA_ "SPN" SG_ 2566730238 HydraulicFan2MotorPressure 1707;
BA_ "SPN" SG_ 2566730750 Aftrtrtmnt2DslExhstFldPmp 7108;
BA_ "SPN" SG_ 2566730750 Aftrtrtmnt2DslExhstFldPmpPwrRl 8481;
BA_ "SPN" SG_ 2566730750 Aftrtrtmnt2DslExhstFldPmpStt 5438;
BA_ "SPN" SG_ 2566730750 Atttt2DsExstFdDsUt1DvtVv 4442;
BA_ "SPN" SG_ 2566730750 Atttt2DsExstFdDsUt2DvtVv 7537;
BA_ "SPN" SG_ 2566730750 Atttt2DsExstFdPp1MtSpd 4440;
BA_ "SPN" SG_ 2566730750 Atttt2DsExstFdPpDvPt 4441;
BA_ "SPN" SG_ 2566730750 Atttt2DsExstFdTDVvCd 5439;
BA_ "SPN" SG_ 2566730750 Atttt2DsExstFdTFVvCd 5437;
BA_ "SPN" SG_ 2566731006 Aftrtrtmnt2DslExhstFldQkThwHtr 4438;
BA_ "SPN" SG_ 2566731006 Atttt2DsExstFdQTwHtPFMI 4439;
BA_ "SPN" SG_ 2566731006 Atttt2DsExstFdQTwLvPFMI 4436;
BA_ "SPN" SG_ 2566731006 Atttt2DsExstFdQTwTLv 4435;
BA_ "SPN" SG_ 2566731006 Atttt2DsExstFdQTwTpt 4434;
BA_ "SPN" SG_ 2566731006 Atttt2DsExstFdQTwTptPFMI 4437;
BA_ "SPN" SG_ 2566731006 Atttt2DsExstFdQTwTV 4433;
BA_ "SPN" SG_ 2566731262 Aftrtrtmnt2DslExhstFldTnkHtr 4431;
BA_ "SPN" SG_ 2566731262 Aftrtrtmnt2DslExhstFldTnkLvl 4428;
BA_ "SPN" SG_ 2566731262 Aftrtrtmnt2DslExhstFldTnkVlm 4426;
BA_ "SPN" SG_ 2566731262 Atttt2DsExstFdT1HtPFMI 4432;
BA_ "SPN" SG_ 2566731262 Atttt2DsExstFdT1TptPFMI 4430;
BA_ "SPN" SG_ 2566731262 Atttt2DsExstFdTLvVPFMI 4429;
BA_ "SPN" SG_ 2566731262 Atttt2DsExstFdTTpt1 4427;
BA_ "SPN" SG_ 2566731518 Aftrtrtmnt2DslExhstFldCndtvt 4422;
BA_ "SPN" SG_ 2566731518 Aftrtrtmnt2DslExhstFldCnntrtn 4421;
BA_ "SPN" SG_ 2566731518 Aftrtrtmnt2DslExhstFldTmprtr2 4420;
BA_ "SPN" SG_ 2566731518 Aftrtrtmnt2DslExhstFldTpPrprt 4425;
BA_ "SPN" SG_ 2566731518 Atttt2DsExstFdPptsPFMI 4424;
BA_ "SPN" SG_ 2566731518 Atttt2DsExstFdTpt2PFMI 4423;
BA_ "SPN" SG_ 2566731774 Aftrtrtmnt2SCRCnvrsnEffn 4419;
BA_ "SPN" SG_ 2566731774 Aftrtrtmnt2SCRSstmSlftnLvl 7849;
BA_ "SPN" SG_ 2566731774 Atttt2DsExstFdAvCspt 4417;
BA_ "SPN" SG_ 2566731774 Atttt2SCRCddDsExstFdCspt 4418;
BA_ "SPN" SG_ 2566732030 Aftrtrtmnt2SCRIntkTmprtr 4413;
BA_ "SPN" SG_ 2566732030 Aftrtrtmnt2SCROtltTmprtr 4415;
BA_ "SPN" SG_ 2566732030 Atttt2SCRItTptPFMI 4414;
BA_ "SPN" SG_ 2566732030 Atttt2SCROttTptPFMI 4416;
BA_ "SPN" SG_ 2566732286 Aftrtrtmnt2SCRDffrntlPrssr 4411;
BA_ "SPN" SG_ 2566732286 Aftrtrtmnt2SCRIntkAsltPrssr 6798;
BA_ "SPN" SG_ 2566732286 Aftrtrtmnt2SCRIntkPrssr 6587;
BA_ "SPN" SG_ 2566732286 Atttt2SCRDtPssPFMI 4412;
BA_ "SPN" SG_ 2566732542 Aftrtrtmnt2DslExhstFldLnHtr1 4407;
BA_ "SPN" SG_ 2566732542 Aftrtrtmnt2DslExhstFldLnHtr10 7571;
BA_ "SPN" SG_ 2566732542 Aftrtrtmnt2DslExhstFldLnHtr2 4408;
BA_ "SPN" SG_ 2566732542 Aftrtrtmnt2DslExhstFldLnHtr3 4409;
BA_ "SPN" SG_ 2566732542 Aftrtrtmnt2DslExhstFldLnHtr4 4410;
BA_ "SPN" SG_ 2566732542 Aftrtrtmnt2DslExhstFldLnHtr5 5490;
BA_ "SPN" SG_ 2566732542 Aftrtrtmnt2DslExhstFldLnHtr6 7567;
BA_ "SPN" SG_ 2566732542 Aftrtrtmnt2DslExhstFldLnHtr7 7568;
BA_ "SPN" SG_ 2566732542 Aftrtrtmnt2DslExhstFldLnHtr8 7569;
BA_ "SPN" SG_ 2566732542 Aftrtrtmnt2DslExhstFldLnHtr9 7570;
BA_ "SPN" SG_ 2566732542 Aftrtrtmnt2DslExhstFldLnHtrRl1 5973;
BA_ "SPN" SG_ 2566732542 Aftrtrtmnt2DslExhstFldLnHtrRl2 7526;
BA_ "SPN" SG_ 2566732542 Aftrtrtmnt2DslExhstFldLnHtrRl3 7527;
BA_ "SPN" SG_ 2566732542 Atttt2DsExstFdDsFtSppssRqst 4405;
BA_ "SPN" SG_ 2566732542 Atttt2DsExstFdDsHtMdRqst 4406;
BA_ "SPN" SG_ 2566732542 Atttt2DsExstFdQTwHtCd 5415;
BA_ "SPN" SG_ 2566732542 Atttt2DsExstFdTHtCd 5138;
BA_ "SPN" SG_ 2566732798 Aftrtrtmnt2DslExhstFldLnHtr1Stt 4393;
BA_ "SPN" SG_ 2566732798 Aftrtrtmnt2DslExhstFldLnHtr2Stt 4395;
BA_ "SPN" SG_ 2566732798 Aftrtrtmnt2DslExhstFldLnHtr3Stt 4397;
BA_ "SPN" SG_ 2566732798 Aftrtrtmnt2DslExhstFldLnHtr4Stt 4399;
BA_ "SPN" SG_ 2566732798 Aftrtrtmnt2SCRDsngArAssstVlv 4389;
BA_ "SPN" SG_ 2566732798 Aftrtrtmnt2SCRFdkCntrlStts 4392;
BA_ "SPN" SG_ 2566732798 Atttt2DsExstFdDs1Tpt 4390;
BA_ "SPN" SG_ 2566732798 Atttt2DsExstFdLHt1PFMI 4394;
BA_ "SPN" SG_ 2566732798 Atttt2DsExstFdLHt2PFMI 4396;
BA_ "SPN" SG_ 2566732798 Atttt2DsExstFdLHt3PFMI 4398;
BA_ "SPN" SG_ 2566732798 Atttt2DsExstFdLHt4PFMI 4400;
BA_ "SPN" SG_ 2566732798 Atttt2SCRDsAAssstAstPss 4388;
BA_ "SPN" SG_ 2566732798 Atttt2SCRDsVvExstTptRdtRqst 4391;
BA_ "SPN" SG_ 2566733054 Aftrtrtmnt1DslExhstFldPmp 7107;
BA_ "SPN" SG_ 2566733054 Aftrtrtmnt1DslExhstFldPmpPwrRl 7416;
BA_ "SPN" SG_ 2566733054 Aftrtrtmnt1DslExhstFldPmpStt 5435;
BA_ "SPN" SG_ 2566733054 Atttt1DsExstFdDsUt1DvtVv 4376;
BA_ "SPN" SG_ 2566733054 Atttt1DsExstFdDsUt2DvtVv 7536;
BA_ "SPN" SG_ 2566733054 Atttt1DsExstFdPp1MtSpd 4374;
BA_ "SPN" SG_ 2566733054 Atttt1DsExstFdPpDvPt 4375;
BA_ "SPN" SG_ 2566733054 Atttt1DsExstFdTDVvCd 5436;
BA_ "SPN" SG_ 2566733054 Atttt1DsExstFdTFVvCd 5434;
BA_ "SPN" SG_ 2566733310 Aftrtrtmnt1DslExhstFldQkThwHtr 4372;
BA_ "SPN" SG_ 2566733310 Atttt1DsExstFdQTwHtPFMI 4373;
BA_ "SPN" SG_ 2566733310 Atttt1DsExstFdQTwLvVPFMI 4370;
BA_ "SPN" SG_ 2566733310 Atttt1DsExstFdQTwTLv 4369;
BA_ "SPN" SG_ 2566733310 Atttt1DsExstFdQTwTpt 4368;
BA_ "SPN" SG_ 2566733310 Atttt1DsExstFdQTwTptPFMI 4371;
BA_ "SPN" SG_ 2566733310 Atttt1DsExstFdQTwTV 4367;
BA_ "SPN" SG_ 2566733822 Aftrtrtmnt1SCRDffrntlPrssr 4358;
BA_ "SPN" SG_ 2566733822 Aftrtrtmnt1SCRIntkAsltPrssr 6797;
BA_ "SPN" SG_ 2566733822 Aftrtrtmnt1SCRIntkPrssr 6586;
BA_ "SPN" SG_ 2566733822 Atttt1SCRDtPssPFMI 4359;
BA_ "SPN" SG_ 2566734078 Aftrtrtmnt1DslExhstFldLnHtr1 4354;
BA_ "SPN" SG_ 2566734078 Aftrtrtmnt1DslExhstFldLnHtr10 7566;
BA_ "SPN" SG_ 2566734078 Aftrtrtmnt1DslExhstFldLnHtr2 4355;
BA_ "SPN" SG_ 2566734078 Aftrtrtmnt1DslExhstFldLnHtr3 4356;
BA_ "SPN" SG_ 2566734078 Aftrtrtmnt1DslExhstFldLnHtr4 4357;
BA_ "SPN" SG_ 2566734078 Aftrtrtmnt1DslExhstFldLnHtr5 7561;
BA_ "SPN" SG_ 2566734078 Aftrtrtmnt1DslExhstFldLnHtr6 7562;
BA_ "SPN" SG_ 2566734078 Aftrtrtmnt1DslExhstFldLnHtr7 7563;
BA_ "SPN" SG_ 2566734078 Aftrtrtmnt1DslExhstFldLnHtr8 7564;
BA_ "SPN" SG_ 2566734078 Aftrtrtmnt1DslExhstFldLnHtr9 7565;
BA_ "SPN" SG_ 2566734078 Aftrtrtmnt1DslExhstFldLnHtrRl1 5491;
BA_ "SPN" SG_ 2566734078 Aftrtrtmnt1DslExhstFldLnHtrRl2 7069;
BA_ "SPN" SG_ 2566734078 Aftrtrtmnt1DslExhstFldLnHtrRl3 7540;
BA_ "SPN" SG_ 2566734078 Atttt1DsExstFdDsFtSppssRqst 4352;
BA_ "SPN" SG_ 2566734078 Atttt1DsExstFdDsHtMdRqst 4353;
BA_ "SPN" SG_ 2566734078 Atttt1DsExstFdPpHtCd 5707;
BA_ "SPN" SG_ 2566734078 Atttt1DsExstFdQTwHtCd 5414;
BA_ "SPN" SG_ 2566734078 Atttt1DsExstFdTHtCd 5137;
